VERSION "created by canmatrix"

NS_ :

BS_:

BU_: Pack01BMSLeader Pack02BMS Pack03BMS Pack04BMS Pack05BMS Pack06BMS Pack07BMS Pack08BMS Pack09BMS Pack10BMS Pack11BMS Pack12BMS Pack13BMS Pack14BMS Pack15BMS Pack16BMS

BO_ 2364525001 Control_1_Pack01BMSLeader: 8 Pack01BMSLeader
 SG_ Connect_Command : 0|3@1+ (1,0) [0|7] "" Pack01BMSLeader
 SG_ Disable_Command : 3|2@1+ (1,0) [0|3] "" Pack01BMSLeader

BO_ 2364525257 Control_1_Pack02BMS: 8 Pack01BMSLeader
 SG_ Connect_Command : 0|3@1+ (1,0) [0|7] "" Pack02BMS
 SG_ Disable_Command : 3|2@1+ (1,0) [0|3] "" Pack02BMS

BO_ 2364525513 Control_1_Pack03BMS: 8 Pack01BMSLeader
 SG_ Connect_Command : 0|3@1+ (1,0) [0|7] "" Pack03BMS
 SG_ Disable_Command : 3|2@1+ (1,0) [0|3] "" Pack03BMS

BO_ 2364525769 Control_1_Pack04BMS: 8 Pack01BMSLeader
 SG_ Connect_Command : 0|3@1+ (1,0) [0|7] "" Pack04BMS
 SG_ Disable_Command : 3|2@1+ (1,0) [0|3] "" Pack04BMS

BO_ 2364526025 Control_1_Pack05BMS: 8 Pack01BMSLeader
 SG_ Connect_Command : 0|3@1+ (1,0) [0|7] "" Pack05BMS
 SG_ Disable_Command : 3|2@1+ (1,0) [0|3] "" Pack05BMS

BO_ 2364526281 Control_1_Pack06BMS: 8 Pack01BMSLeader
 SG_ Connect_Command : 0|3@1+ (1,0) [0|7] "" Pack06BMS
 SG_ Disable_Command : 3|2@1+ (1,0) [0|3] "" Pack06BMS

BO_ 2364526537 Control_1_Pack07BMS: 8 Pack01BMSLeader
 SG_ Connect_Command : 0|3@1+ (1,0) [0|7] "" Pack07BMS
 SG_ Disable_Command : 3|2@1+ (1,0) [0|3] "" Pack07BMS

BO_ 2364526793 Control_1_Pack08BMS: 8 Pack01BMSLeader
 SG_ Connect_Command : 0|3@1+ (1,0) [0|7] "" Pack08BMS
 SG_ Disable_Command : 3|2@1+ (1,0) [0|3] "" Pack08BMS

BO_ 2364527049 Control_1_Pack09BMS: 8 Pack01BMSLeader
 SG_ Connect_Command : 0|3@1+ (1,0) [0|7] "" Pack09BMS
 SG_ Disable_Command : 3|2@1+ (1,0) [0|3] "" Pack09BMS

BO_ 2364527305 Control_1_Pack10BMS: 8 Pack01BMSLeader
 SG_ Connect_Command : 0|3@1+ (1,0) [0|7] "" Pack10BMS
 SG_ Disable_Command : 3|2@1+ (1,0) [0|3] "" Pack10BMS

BO_ 2364527561 Control_1_Pack11BMS: 8 Pack01BMSLeader
 SG_ Connect_Command : 0|3@1+ (1,0) [0|7] "" Pack11BMS
 SG_ Disable_Command : 3|2@1+ (1,0) [0|3] "" Pack11BMS

BO_ 2364527817 Control_1_Pack12BMS: 8 Pack01BMSLeader
 SG_ Connect_Command : 0|3@1+ (1,0) [0|7] "" Pack12BMS
 SG_ Disable_Command : 3|2@1+ (1,0) [0|3] "" Pack12BMS

BO_ 2364528073 Control_1_Pack13BMS: 8 Pack01BMSLeader
 SG_ Connect_Command : 0|3@1+ (1,0) [0|7] "" Pack13BMS
 SG_ Disable_Command : 3|2@1+ (1,0) [0|3] "" Pack13BMS

BO_ 2364528329 Control_1_Pack14BMS: 8 Pack01BMSLeader
 SG_ Connect_Command : 0|3@1+ (1,0) [0|7] "" Pack14BMS
 SG_ Disable_Command : 3|2@1+ (1,0) [0|3] "" Pack14BMS

BO_ 2364528585 Control_1_Pack15BMS: 8 Pack01BMSLeader
 SG_ Connect_Command : 0|3@1+ (1,0) [0|7] "" Pack15BMS
 SG_ Disable_Command : 3|2@1+ (1,0) [0|3] "" Pack15BMS

BO_ 2364528841 Control_1_Pack16BMS: 8 Pack01BMSLeader
 SG_ Connect_Command : 0|3@1+ (1,0) [0|7] "" Pack16BMS
 SG_ Disable_Command : 3|2@1+ (1,0) [0|3] "" Pack16BMS

BO_ 2365587401 Control_2_Broadcast: 8 Pack01BMSLeader
 SG_ System_Current : 0|16@1+ (0.05,-1600) [-1600|1676.75] "A" Vector__XXX
 SG_ System_Average_Current_Connected : 16|16@1+ (0.05,-1600) [-1600|1676.75] "A" Vector__XXX
 SG_ System_HVDC_Bus_Voltage : 32|16@1+ (0.05,0) [0|3276.75] "V" Vector__XXX
 SG_ System_Charging_Mode : 48|2@1+ (1,0) [0|3] "" Vector__XXX

BO_ 2365587145 Control_3_Broadcast: 8 Pack01BMSLeader
 SG_ System_Unix_Time : 0|32@1+ (1,0) [0|4294967295] "s" Vector__XXX
 SG_ System_Clear_DMs_Command : 32|2@1+ (1,0) [0|3] "" Vector__XXX

BO_ 2566834889 DM1_INTERPACK_Pack01BMSLeader: 550 Pack01BMSLeader

BO_ 2566834890 DM1_INTERPACK_Pack02BMS: 550 Pack02BMS

BO_ 2566834891 DM1_INTERPACK_Pack03BMS: 550 Pack03BMS

BO_ 2566834892 DM1_INTERPACK_Pack04BMS: 550 Pack04BMS

BO_ 2566834893 DM1_INTERPACK_Pack05BMS: 550 Pack05BMS

BO_ 2566834894 DM1_INTERPACK_Pack06BMS: 550 Pack06BMS

BO_ 2566834895 DM1_INTERPACK_Pack07BMS: 550 Pack07BMS

BO_ 2566834896 DM1_INTERPACK_Pack08BMS: 550 Pack08BMS

BO_ 2566834897 DM1_INTERPACK_Pack09BMS: 550 Pack09BMS

BO_ 2566834898 DM1_INTERPACK_Pack10BMS: 550 Pack10BMS

BO_ 2566834899 DM1_INTERPACK_Pack11BMS: 550 Pack11BMS

BO_ 2566834900 DM1_INTERPACK_Pack12BMS: 550 Pack12BMS

BO_ 2566834901 DM1_INTERPACK_Pack13BMS: 550 Pack13BMS

BO_ 2566834902 DM1_INTERPACK_Pack14BMS: 550 Pack14BMS

BO_ 2566834903 DM1_INTERPACK_Pack15BMS: 550 Pack15BMS

BO_ 2566834904 DM1_INTERPACK_Pack16BMS: 550 Pack16BMS

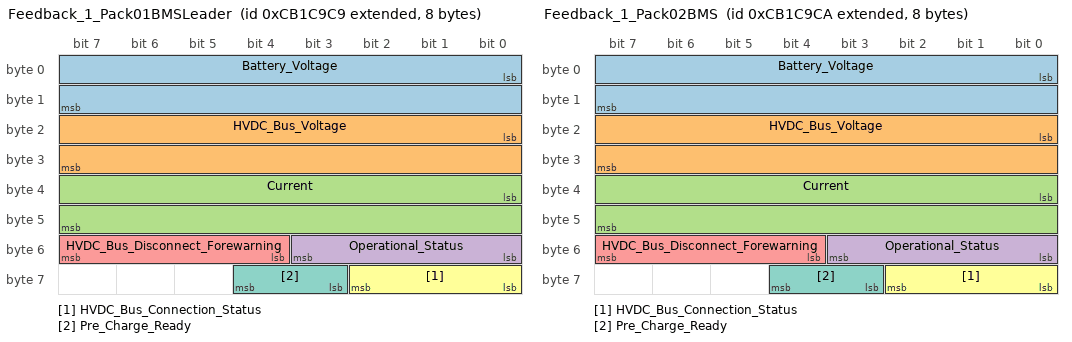
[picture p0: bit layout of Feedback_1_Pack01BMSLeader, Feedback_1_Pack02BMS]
BO_ 2360461769 Feedback_1_Pack01BMSLeader: 8 Pack01BMSLeader
 SG_ Battery_Voltage : 0|16@1+ (0.05,0) [0|3276.75] "V" Pack01BMSLeader
 SG_ HVDC_Bus_Voltage : 16|16@1+ (0.05,0) [0|3276.75] "V" Pack01BMSLeader
 SG_ Current : 32|16@1+ (0.05,-1600) [-1600|1676.75] "A" Pack01BMSLeader
 SG_ Operational_Status : 48|4@1+ (1,0) [0|15] "" Pack01BMSLeader
 SG_ HVDC_Bus_Disconnect_Forewarning : 52|4@1+ (1,0) [0|15] "" Pack01BMSLeader
 SG_ HVDC_Bus_Connection_Status : 56|3@1+ (1,0) [0|7] "" Pack01BMSLeader
 SG_ Pre_Charge_Ready : 59|2@1+ (1,0) [0|3] "" Pack01BMSLeader

BO_ 2360461770 Feedback_1_Pack02BMS: 8 Pack02BMS
 SG_ Battery_Voltage : 0|16@1+ (0.05,0) [0|3276.75] "V" Pack01BMSLeader
 SG_ HVDC_Bus_Voltage : 16|16@1+ (0.05,0) [0|3276.75] "V" Pack01BMSLeader
 SG_ Current : 32|16@1+ (0.05,-1600) [-1600|1676.75] "A" Pack01BMSLeader
 SG_ Operational_Status : 48|4@1+ (1,0) [0|15] "" Pack01BMSLeader
 SG_ HVDC_Bus_Disconnect_Forewarning : 52|4@1+ (1,0) [0|15] "" Pack01BMSLeader
 SG_ HVDC_Bus_Connection_Status : 56|3@1+ (1,0) [0|7] "" Pack01BMSLeader
 SG_ Pre_Charge_Ready : 59|2@1+ (1,0) [0|3] "" Pack01BMSLeader

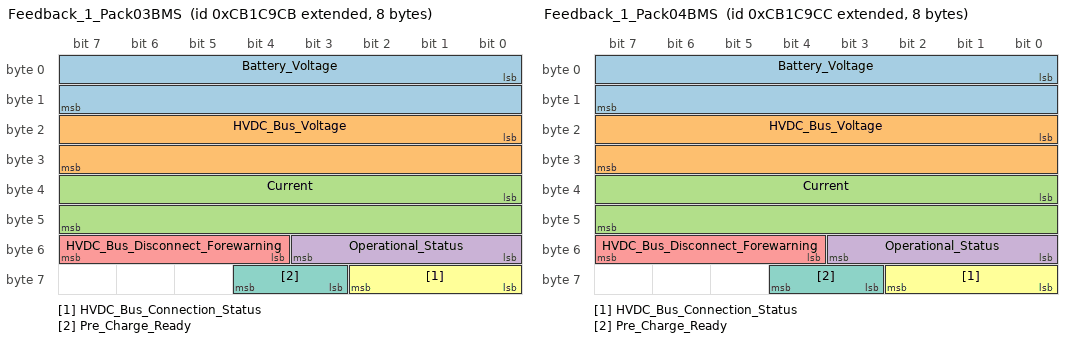
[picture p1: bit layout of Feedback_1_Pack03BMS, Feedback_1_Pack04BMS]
BO_ 2360461771 Feedback_1_Pack03BMS: 8 Pack03BMS
 SG_ Battery_Voltage : 0|16@1+ (0.05,0) [0|3276.75] "V" Pack01BMSLeader
 SG_ HVDC_Bus_Voltage : 16|16@1+ (0.05,0) [0|3276.75] "V" Pack01BMSLeader
 SG_ Current : 32|16@1+ (0.05,-1600) [-1600|1676.75] "A" Pack01BMSLeader
 SG_ Operational_Status : 48|4@1+ (1,0) [0|15] "" Pack01BMSLeader
 SG_ HVDC_Bus_Disconnect_Forewarning : 52|4@1+ (1,0) [0|15] "" Pack01BMSLeader
 SG_ HVDC_Bus_Connection_Status : 56|3@1+ (1,0) [0|7] "" Pack01BMSLeader
 SG_ Pre_Charge_Ready : 59|2@1+ (1,0) [0|3] "" Pack01BMSLeader

BO_ 2360461772 Feedback_1_Pack04BMS: 8 Pack04BMS
 SG_ Battery_Voltage : 0|16@1+ (0.05,0) [0|3276.75] "V" Pack01BMSLeader
 SG_ HVDC_Bus_Voltage : 16|16@1+ (0.05,0) [0|3276.75] "V" Pack01BMSLeader
 SG_ Current : 32|16@1+ (0.05,-1600) [-1600|1676.75] "A" Pack01BMSLeader
 SG_ Operational_Status : 48|4@1+ (1,0) [0|15] "" Pack01BMSLeader
 SG_ HVDC_Bus_Disconnect_Forewarning : 52|4@1+ (1,0) [0|15] "" Pack01BMSLeader
 SG_ HVDC_Bus_Connection_Status : 56|3@1+ (1,0) [0|7] "" Pack01BMSLeader
 SG_ Pre_Charge_Ready : 59|2@1+ (1,0) [0|3] "" Pack01BMSLeader

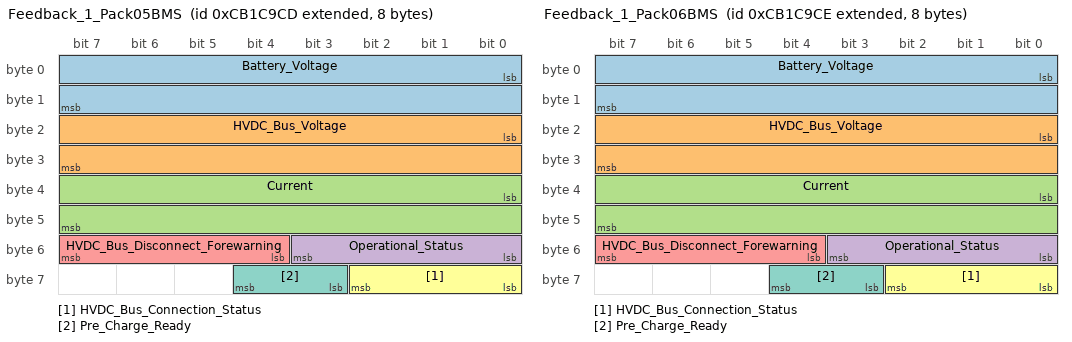
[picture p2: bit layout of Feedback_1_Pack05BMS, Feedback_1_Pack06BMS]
BO_ 2360461773 Feedback_1_Pack05BMS: 8 Pack05BMS
 SG_ Battery_Voltage : 0|16@1+ (0.05,0) [0|3276.75] "V" Pack01BMSLeader
 SG_ HVDC_Bus_Voltage : 16|16@1+ (0.05,0) [0|3276.75] "V" Pack01BMSLeader
 SG_ Current : 32|16@1+ (0.05,-1600) [-1600|1676.75] "A" Pack01BMSLeader
 SG_ Operational_Status : 48|4@1+ (1,0) [0|15] "" Pack01BMSLeader
 SG_ HVDC_Bus_Disconnect_Forewarning : 52|4@1+ (1,0) [0|15] "" Pack01BMSLeader
 SG_ HVDC_Bus_Connection_Status : 56|3@1+ (1,0) [0|7] "" Pack01BMSLeader
 SG_ Pre_Charge_Ready : 59|2@1+ (1,0) [0|3] "" Pack01BMSLeader

BO_ 2360461774 Feedback_1_Pack06BMS: 8 Pack06BMS
 SG_ Battery_Voltage : 0|16@1+ (0.05,0) [0|3276.75] "V" Pack01BMSLeader
 SG_ HVDC_Bus_Voltage : 16|16@1+ (0.05,0) [0|3276.75] "V" Pack01BMSLeader
 SG_ Current : 32|16@1+ (0.05,-1600) [-1600|1676.75] "A" Pack01BMSLeader
 SG_ Operational_Status : 48|4@1+ (1,0) [0|15] "" Pack01BMSLeader
 SG_ HVDC_Bus_Disconnect_Forewarning : 52|4@1+ (1,0) [0|15] "" Pack01BMSLeader
 SG_ HVDC_Bus_Connection_Status : 56|3@1+ (1,0) [0|7] "" Pack01BMSLeader
 SG_ Pre_Charge_Ready : 59|2@1+ (1,0) [0|3] "" Pack01BMSLeader

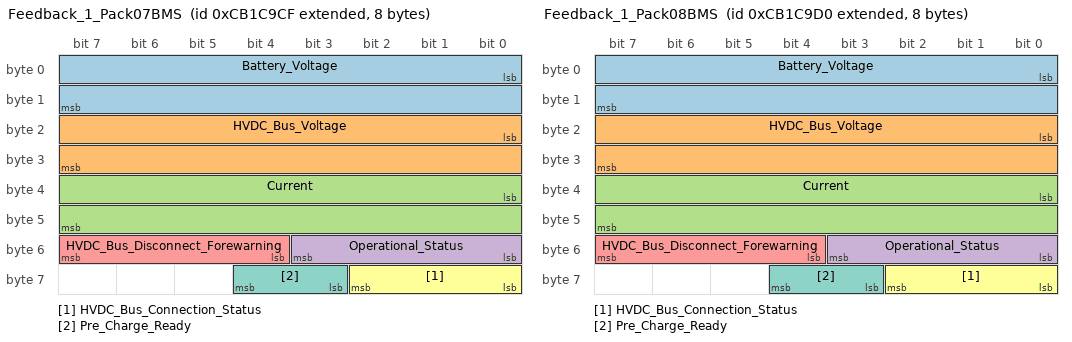
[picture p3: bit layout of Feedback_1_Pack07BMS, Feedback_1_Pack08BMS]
BO_ 2360461775 Feedback_1_Pack07BMS: 8 Pack07BMS
 SG_ Battery_Voltage : 0|16@1+ (0.05,0) [0|3276.75] "V" Pack01BMSLeader
 SG_ HVDC_Bus_Voltage : 16|16@1+ (0.05,0) [0|3276.75] "V" Pack01BMSLeader
 SG_ Current : 32|16@1+ (0.05,-1600) [-1600|1676.75] "A" Pack01BMSLeader
 SG_ Operational_Status : 48|4@1+ (1,0) [0|15] "" Pack01BMSLeader
 SG_ HVDC_Bus_Disconnect_Forewarning : 52|4@1+ (1,0) [0|15] "" Pack01BMSLeader
 SG_ HVDC_Bus_Connection_Status : 56|3@1+ (1,0) [0|7] "" Pack01BMSLeader
 SG_ Pre_Charge_Ready : 59|2@1+ (1,0) [0|3] "" Pack01BMSLeader

BO_ 2360461776 Feedback_1_Pack08BMS: 8 Pack08BMS
 SG_ Battery_Voltage : 0|16@1+ (0.05,0) [0|3276.75] "V" Pack01BMSLeader
 SG_ HVDC_Bus_Voltage : 16|16@1+ (0.05,0) [0|3276.75] "V" Pack01BMSLeader
 SG_ Current : 32|16@1+ (0.05,-1600) [-1600|1676.75] "A" Pack01BMSLeader
 SG_ Operational_Status : 48|4@1+ (1,0) [0|15] "" Pack01BMSLeader
 SG_ HVDC_Bus_Disconnect_Forewarning : 52|4@1+ (1,0) [0|15] "" Pack01BMSLeader
 SG_ HVDC_Bus_Connection_Status : 56|3@1+ (1,0) [0|7] "" Pack01BMSLeader
 SG_ Pre_Charge_Ready : 59|2@1+ (1,0) [0|3] "" Pack01BMSLeader

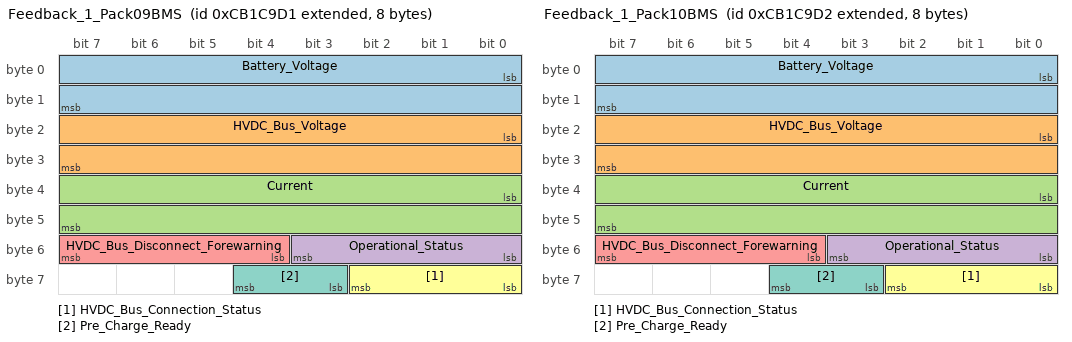
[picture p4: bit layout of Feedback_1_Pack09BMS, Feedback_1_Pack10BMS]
BO_ 2360461777 Feedback_1_Pack09BMS: 8 Pack09BMS
 SG_ Battery_Voltage : 0|16@1+ (0.05,0) [0|3276.75] "V" Pack01BMSLeader
 SG_ HVDC_Bus_Voltage : 16|16@1+ (0.05,0) [0|3276.75] "V" Pack01BMSLeader
 SG_ Current : 32|16@1+ (0.05,-1600) [-1600|1676.75] "A" Pack01BMSLeader
 SG_ Operational_Status : 48|4@1+ (1,0) [0|15] "" Pack01BMSLeader
 SG_ HVDC_Bus_Disconnect_Forewarning : 52|4@1+ (1,0) [0|15] "" Pack01BMSLeader
 SG_ HVDC_Bus_Connection_Status : 56|3@1+ (1,0) [0|7] "" Pack01BMSLeader
 SG_ Pre_Charge_Ready : 59|2@1+ (1,0) [0|3] "" Pack01BMSLeader

BO_ 2360461778 Feedback_1_Pack10BMS: 8 Pack10BMS
 SG_ Battery_Voltage : 0|16@1+ (0.05,0) [0|3276.75] "V" Pack01BMSLeader
 SG_ HVDC_Bus_Voltage : 16|16@1+ (0.05,0) [0|3276.75] "V" Pack01BMSLeader
 SG_ Current : 32|16@1+ (0.05,-1600) [-1600|1676.75] "A" Pack01BMSLeader
 SG_ Operational_Status : 48|4@1+ (1,0) [0|15] "" Pack01BMSLeader
 SG_ HVDC_Bus_Disconnect_Forewarning : 52|4@1+ (1,0) [0|15] "" Pack01BMSLeader
 SG_ HVDC_Bus_Connection_Status : 56|3@1+ (1,0) [0|7] "" Pack01BMSLeader
 SG_ Pre_Charge_Ready : 59|2@1+ (1,0) [0|3] "" Pack01BMSLeader

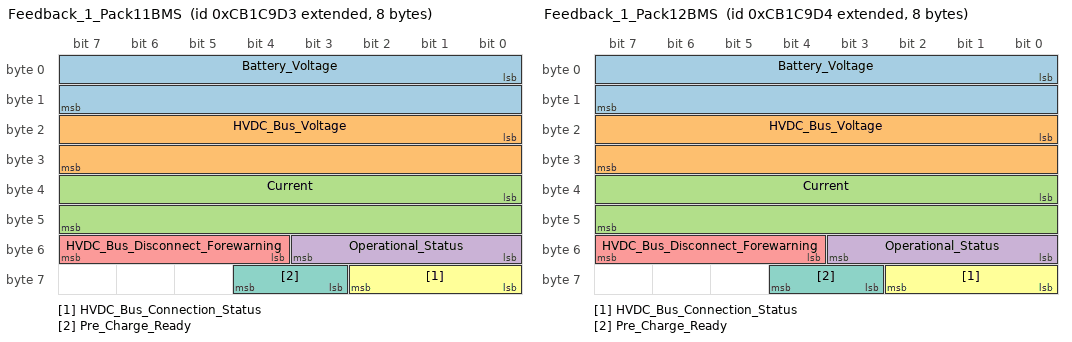
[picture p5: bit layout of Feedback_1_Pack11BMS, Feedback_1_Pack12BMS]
BO_ 2360461779 Feedback_1_Pack11BMS: 8 Pack11BMS
 SG_ Battery_Voltage : 0|16@1+ (0.05,0) [0|3276.75] "V" Pack01BMSLeader
 SG_ HVDC_Bus_Voltage : 16|16@1+ (0.05,0) [0|3276.75] "V" Pack01BMSLeader
 SG_ Current : 32|16@1+ (0.05,-1600) [-1600|1676.75] "A" Pack01BMSLeader
 SG_ Operational_Status : 48|4@1+ (1,0) [0|15] "" Pack01BMSLeader
 SG_ HVDC_Bus_Disconnect_Forewarning : 52|4@1+ (1,0) [0|15] "" Pack01BMSLeader
 SG_ HVDC_Bus_Connection_Status : 56|3@1+ (1,0) [0|7] "" Pack01BMSLeader
 SG_ Pre_Charge_Ready : 59|2@1+ (1,0) [0|3] "" Pack01BMSLeader

BO_ 2360461780 Feedback_1_Pack12BMS: 8 Pack12BMS
 SG_ Battery_Voltage : 0|16@1+ (0.05,0) [0|3276.75] "V" Pack01BMSLeader
 SG_ HVDC_Bus_Voltage : 16|16@1+ (0.05,0) [0|3276.75] "V" Pack01BMSLeader
 SG_ Current : 32|16@1+ (0.05,-1600) [-1600|1676.75] "A" Pack01BMSLeader
 SG_ Operational_Status : 48|4@1+ (1,0) [0|15] "" Pack01BMSLeader
 SG_ HVDC_Bus_Disconnect_Forewarning : 52|4@1+ (1,0) [0|15] "" Pack01BMSLeader
 SG_ HVDC_Bus_Connection_Status : 56|3@1+ (1,0) [0|7] "" Pack01BMSLeader
 SG_ Pre_Charge_Ready : 59|2@1+ (1,0) [0|3] "" Pack01BMSLeader

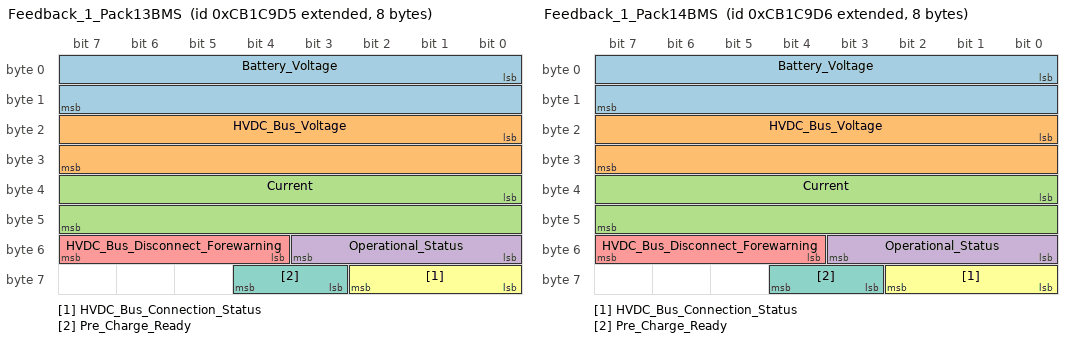
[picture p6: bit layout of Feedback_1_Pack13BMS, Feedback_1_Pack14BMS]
BO_ 2360461781 Feedback_1_Pack13BMS: 8 Pack13BMS
 SG_ Battery_Voltage : 0|16@1+ (0.05,0) [0|3276.75] "V" Pack01BMSLeader
 SG_ HVDC_Bus_Voltage : 16|16@1+ (0.05,0) [0|3276.75] "V" Pack01BMSLeader
 SG_ Current : 32|16@1+ (0.05,-1600) [-1600|1676.75] "A" Pack01BMSLeader
 SG_ Operational_Status : 48|4@1+ (1,0) [0|15] "" Pack01BMSLeader
 SG_ HVDC_Bus_Disconnect_Forewarning : 52|4@1+ (1,0) [0|15] "" Pack01BMSLeader
 SG_ HVDC_Bus_Connection_Status : 56|3@1+ (1,0) [0|7] "" Pack01BMSLeader
 SG_ Pre_Charge_Ready : 59|2@1+ (1,0) [0|3] "" Pack01BMSLeader

BO_ 2360461782 Feedback_1_Pack14BMS: 8 Pack14BMS
 SG_ Battery_Voltage : 0|16@1+ (0.05,0) [0|3276.75] "V" Pack01BMSLeader
 SG_ HVDC_Bus_Voltage : 16|16@1+ (0.05,0) [0|3276.75] "V" Pack01BMSLeader
 SG_ Current : 32|16@1+ (0.05,-1600) [-1600|1676.75] "A" Pack01BMSLeader
 SG_ Operational_Status : 48|4@1+ (1,0) [0|15] "" Pack01BMSLeader
 SG_ HVDC_Bus_Disconnect_Forewarning : 52|4@1+ (1,0) [0|15] "" Pack01BMSLeader
 SG_ HVDC_Bus_Connection_Status : 56|3@1+ (1,0) [0|7] "" Pack01BMSLeader
 SG_ Pre_Charge_Ready : 59|2@1+ (1,0) [0|3] "" Pack01BMSLeader

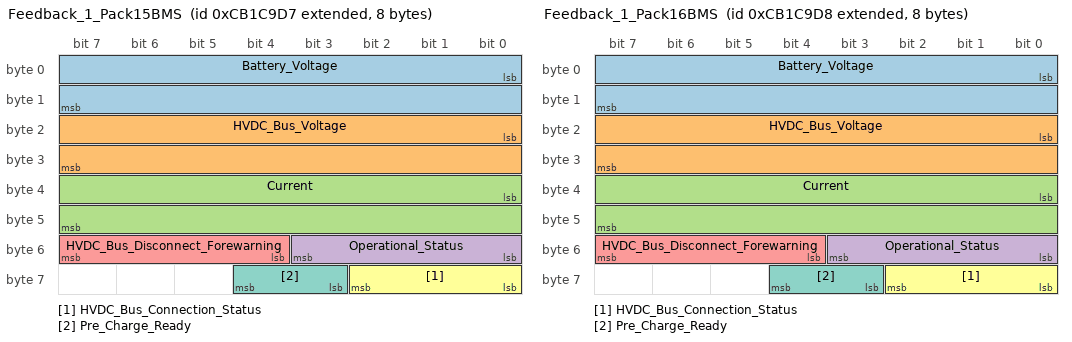
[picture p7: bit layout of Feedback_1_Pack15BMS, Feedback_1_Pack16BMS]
BO_ 2360461783 Feedback_1_Pack15BMS: 8 Pack15BMS
 SG_ Battery_Voltage : 0|16@1+ (0.05,0) [0|3276.75] "V" Pack01BMSLeader
 SG_ HVDC_Bus_Voltage : 16|16@1+ (0.05,0) [0|3276.75] "V" Pack01BMSLeader
 SG_ Current : 32|16@1+ (0.05,-1600) [-1600|1676.75] "A" Pack01BMSLeader
 SG_ Operational_Status : 48|4@1+ (1,0) [0|15] "" Pack01BMSLeader
 SG_ HVDC_Bus_Disconnect_Forewarning : 52|4@1+ (1,0) [0|15] "" Pack01BMSLeader
 SG_ HVDC_Bus_Connection_Status : 56|3@1+ (1,0) [0|7] "" Pack01BMSLeader
 SG_ Pre_Charge_Ready : 59|2@1+ (1,0) [0|3] "" Pack01BMSLeader

BO_ 2360461784 Feedback_1_Pack16BMS: 8 Pack16BMS
 SG_ Battery_Voltage : 0|16@1+ (0.05,0) [0|3276.75] "V" Pack01BMSLeader
 SG_ HVDC_Bus_Voltage : 16|16@1+ (0.05,0) [0|3276.75] "V" Pack01BMSLeader
 SG_ Current : 32|16@1+ (0.05,-1600) [-1600|1676.75] "A" Pack01BMSLeader
 SG_ Operational_Status : 48|4@1+ (1,0) [0|15] "" Pack01BMSLeader
 SG_ HVDC_Bus_Disconnect_Forewarning : 52|4@1+ (1,0) [0|15] "" Pack01BMSLeader
 SG_ HVDC_Bus_Connection_Status : 56|3@1+ (1,0) [0|7] "" Pack01BMSLeader
 SG_ Pre_Charge_Ready : 59|2@1+ (1,0) [0|3] "" Pack01BMSLeader

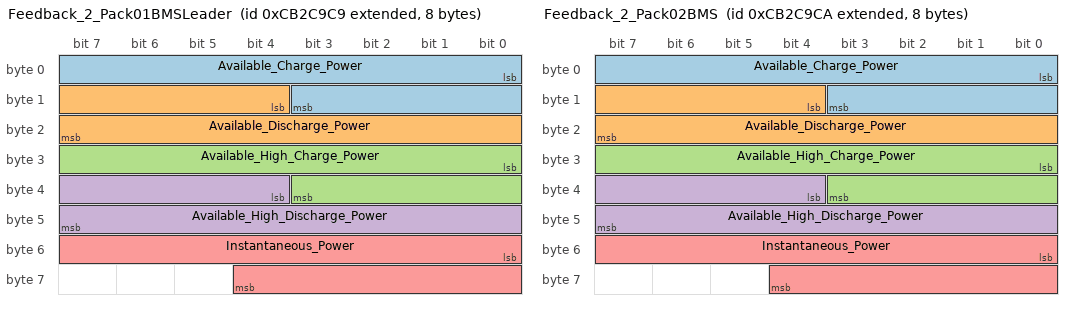
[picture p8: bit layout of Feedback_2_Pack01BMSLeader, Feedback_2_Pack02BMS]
BO_ 2360527305 Feedback_2_Pack01BMSLeader: 8 Pack01BMSLeader
 SG_ Available_Charge_Power : 0|12@1+ (0.05,0) [0|204.75] "kW" Pack01BMSLeader
 SG_ Available_Discharge_Power : 12|12@1+ (0.05,0) [0|204.75] "kW" Pack01BMSLeader
 SG_ Available_High_Charge_Power : 24|12@1+ (0.05,0) [0|204.75] "kW" Pack01BMSLeader
 SG_ Available_High_Discharge_Power : 36|12@1+ (0.05,0) [0|204.75] "kW" Pack01BMSLeader
 SG_ Instantaneous_Power : 48|13@1+ (0.05,-204) [-204|205.55] "kW" Pack01BMSLeader

BO_ 2360527306 Feedback_2_Pack02BMS: 8 Pack02BMS
 SG_ Available_Charge_Power : 0|12@1+ (0.05,0) [0|204.75] "kW" Pack01BMSLeader
 SG_ Available_Discharge_Power : 12|12@1+ (0.05,0) [0|204.75] "kW" Pack01BMSLeader
 SG_ Available_High_Charge_Power : 24|12@1+ (0.05,0) [0|204.75] "kW" Pack01BMSLeader
 SG_ Available_High_Discharge_Power : 36|12@1+ (0.05,0) [0|204.75] "kW" Pack01BMSLeader
 SG_ Instantaneous_Power : 48|13@1+ (0.05,-204) [-204|205.55] "kW" Pack01BMSLeader

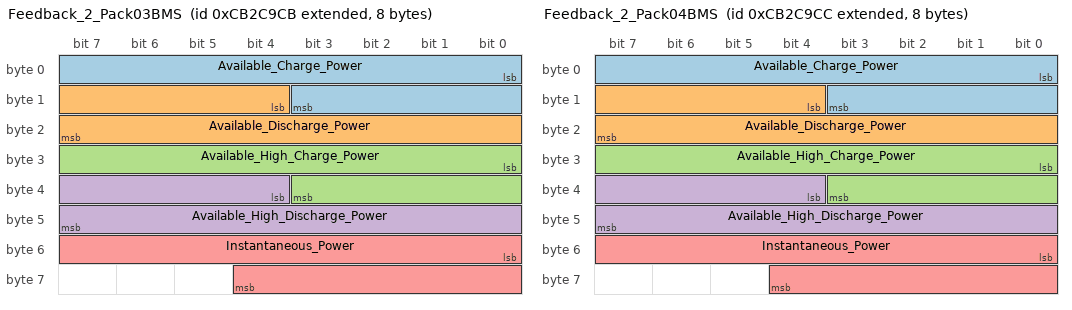
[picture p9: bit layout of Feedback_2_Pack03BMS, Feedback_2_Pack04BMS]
BO_ 2360527307 Feedback_2_Pack03BMS: 8 Pack03BMS
 SG_ Available_Charge_Power : 0|12@1+ (0.05,0) [0|204.75] "kW" Pack01BMSLeader
 SG_ Available_Discharge_Power : 12|12@1+ (0.05,0) [0|204.75] "kW" Pack01BMSLeader
 SG_ Available_High_Charge_Power : 24|12@1+ (0.05,0) [0|204.75] "kW" Pack01BMSLeader
 SG_ Available_High_Discharge_Power : 36|12@1+ (0.05,0) [0|204.75] "kW" Pack01BMSLeader
 SG_ Instantaneous_Power : 48|13@1+ (0.05,-204) [-204|205.55] "kW" Pack01BMSLeader

BO_ 2360527308 Feedback_2_Pack04BMS: 8 Pack04BMS
 SG_ Available_Charge_Power : 0|12@1+ (0.05,0) [0|204.75] "kW" Pack01BMSLeader
 SG_ Available_Discharge_Power : 12|12@1+ (0.05,0) [0|204.75] "kW" Pack01BMSLeader
 SG_ Available_High_Charge_Power : 24|12@1+ (0.05,0) [0|204.75] "kW" Pack01BMSLeader
 SG_ Available_High_Discharge_Power : 36|12@1+ (0.05,0) [0|204.75] "kW" Pack01BMSLeader
 SG_ Instantaneous_Power : 48|13@1+ (0.05,-204) [-204|205.55] "kW" Pack01BMSLeader

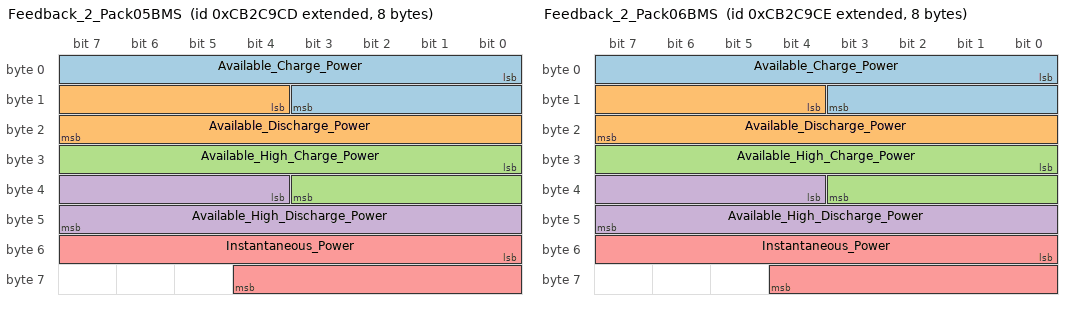
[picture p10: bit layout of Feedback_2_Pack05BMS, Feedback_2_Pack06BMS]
BO_ 2360527309 Feedback_2_Pack05BMS: 8 Pack05BMS
 SG_ Available_Charge_Power : 0|12@1+ (0.05,0) [0|204.75] "kW" Pack01BMSLeader
 SG_ Available_Discharge_Power : 12|12@1+ (0.05,0) [0|204.75] "kW" Pack01BMSLeader
 SG_ Available_High_Charge_Power : 24|12@1+ (0.05,0) [0|204.75] "kW" Pack01BMSLeader
 SG_ Available_High_Discharge_Power : 36|12@1+ (0.05,0) [0|204.75] "kW" Pack01BMSLeader
 SG_ Instantaneous_Power : 48|13@1+ (0.05,-204) [-204|205.55] "kW" Pack01BMSLeader

BO_ 2360527310 Feedback_2_Pack06BMS: 8 Pack06BMS
 SG_ Available_Charge_Power : 0|12@1+ (0.05,0) [0|204.75] "kW" Pack01BMSLeader
 SG_ Available_Discharge_Power : 12|12@1+ (0.05,0) [0|204.75] "kW" Pack01BMSLeader
 SG_ Available_High_Charge_Power : 24|12@1+ (0.05,0) [0|204.75] "kW" Pack01BMSLeader
 SG_ Available_High_Discharge_Power : 36|12@1+ (0.05,0) [0|204.75] "kW" Pack01BMSLeader
 SG_ Instantaneous_Power : 48|13@1+ (0.05,-204) [-204|205.55] "kW" Pack01BMSLeader

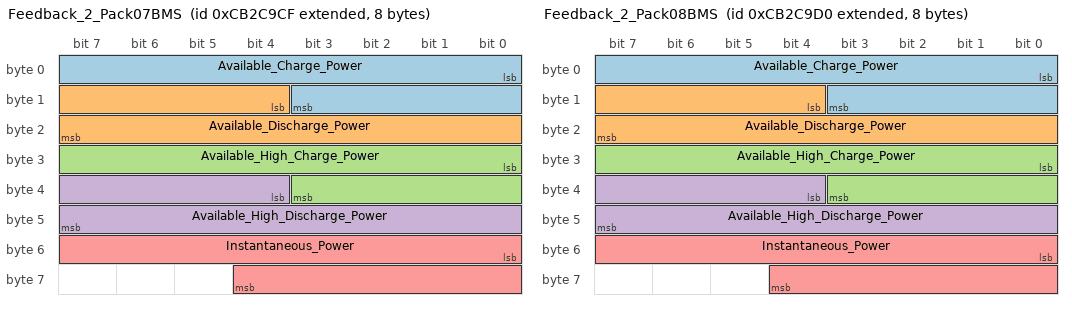
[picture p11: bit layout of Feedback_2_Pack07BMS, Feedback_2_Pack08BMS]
BO_ 2360527311 Feedback_2_Pack07BMS: 8 Pack07BMS
 SG_ Available_Charge_Power : 0|12@1+ (0.05,0) [0|204.75] "kW" Pack01BMSLeader
 SG_ Available_Discharge_Power : 12|12@1+ (0.05,0) [0|204.75] "kW" Pack01BMSLeader
 SG_ Available_High_Charge_Power : 24|12@1+ (0.05,0) [0|204.75] "kW" Pack01BMSLeader
 SG_ Available_High_Discharge_Power : 36|12@1+ (0.05,0) [0|204.75] "kW" Pack01BMSLeader
 SG_ Instantaneous_Power : 48|13@1+ (0.05,-204) [-204|205.55] "kW" Pack01BMSLeader

BO_ 2360527312 Feedback_2_Pack08BMS: 8 Pack08BMS
 SG_ Available_Charge_Power : 0|12@1+ (0.05,0) [0|204.75] "kW" Pack01BMSLeader
 SG_ Available_Discharge_Power : 12|12@1+ (0.05,0) [0|204.75] "kW" Pack01BMSLeader
 SG_ Available_High_Charge_Power : 24|12@1+ (0.05,0) [0|204.75] "kW" Pack01BMSLeader
 SG_ Available_High_Discharge_Power : 36|12@1+ (0.05,0) [0|204.75] "kW" Pack01BMSLeader
 SG_ Instantaneous_Power : 48|13@1+ (0.05,-204) [-204|205.55] "kW" Pack01BMSLeader

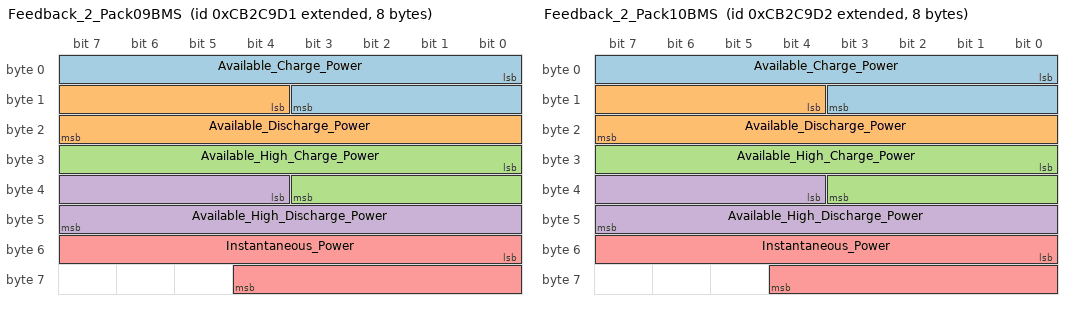
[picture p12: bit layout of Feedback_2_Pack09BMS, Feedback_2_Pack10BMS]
BO_ 2360527313 Feedback_2_Pack09BMS: 8 Pack09BMS
 SG_ Available_Charge_Power : 0|12@1+ (0.05,0) [0|204.75] "kW" Pack01BMSLeader
 SG_ Available_Discharge_Power : 12|12@1+ (0.05,0) [0|204.75] "kW" Pack01BMSLeader
 SG_ Available_High_Charge_Power : 24|12@1+ (0.05,0) [0|204.75] "kW" Pack01BMSLeader
 SG_ Available_High_Discharge_Power : 36|12@1+ (0.05,0) [0|204.75] "kW" Pack01BMSLeader
 SG_ Instantaneous_Power : 48|13@1+ (0.05,-204) [-204|205.55] "kW" Pack01BMSLeader

BO_ 2360527314 Feedback_2_Pack10BMS: 8 Pack10BMS
 SG_ Available_Charge_Power : 0|12@1+ (0.05,0) [0|204.75] "kW" Pack01BMSLeader
 SG_ Available_Discharge_Power : 12|12@1+ (0.05,0) [0|204.75] "kW" Pack01BMSLeader
 SG_ Available_High_Charge_Power : 24|12@1+ (0.05,0) [0|204.75] "kW" Pack01BMSLeader
 SG_ Available_High_Discharge_Power : 36|12@1+ (0.05,0) [0|204.75] "kW" Pack01BMSLeader
 SG_ Instantaneous_Power : 48|13@1+ (0.05,-204) [-204|205.55] "kW" Pack01BMSLeader

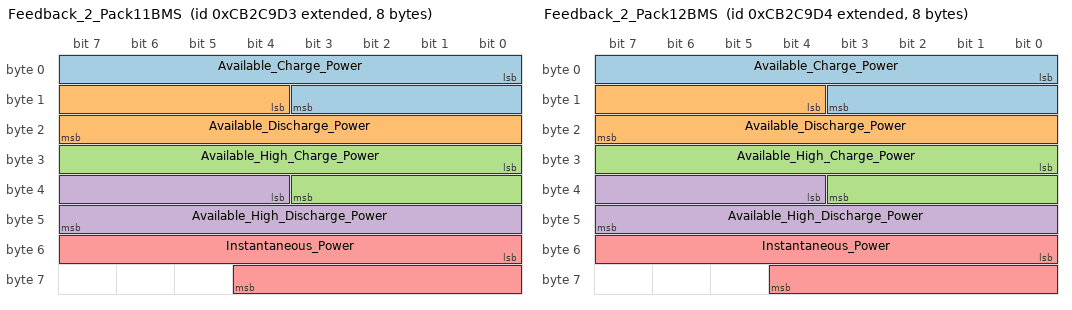
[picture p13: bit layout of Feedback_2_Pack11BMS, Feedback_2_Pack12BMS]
BO_ 2360527315 Feedback_2_Pack11BMS: 8 Pack11BMS
 SG_ Available_Charge_Power : 0|12@1+ (0.05,0) [0|204.75] "kW" Pack01BMSLeader
 SG_ Available_Discharge_Power : 12|12@1+ (0.05,0) [0|204.75] "kW" Pack01BMSLeader
 SG_ Available_High_Charge_Power : 24|12@1+ (0.05,0) [0|204.75] "kW" Pack01BMSLeader
 SG_ Available_High_Discharge_Power : 36|12@1+ (0.05,0) [0|204.75] "kW" Pack01BMSLeader
 SG_ Instantaneous_Power : 48|13@1+ (0.05,-204) [-204|205.55] "kW" Pack01BMSLeader

BO_ 2360527316 Feedback_2_Pack12BMS: 8 Pack12BMS
 SG_ Available_Charge_Power : 0|12@1+ (0.05,0) [0|204.75] "kW" Pack01BMSLeader
 SG_ Available_Discharge_Power : 12|12@1+ (0.05,0) [0|204.75] "kW" Pack01BMSLeader
 SG_ Available_High_Charge_Power : 24|12@1+ (0.05,0) [0|204.75] "kW" Pack01BMSLeader
 SG_ Available_High_Discharge_Power : 36|12@1+ (0.05,0) [0|204.75] "kW" Pack01BMSLeader
 SG_ Instantaneous_Power : 48|13@1+ (0.05,-204) [-204|205.55] "kW" Pack01BMSLeader

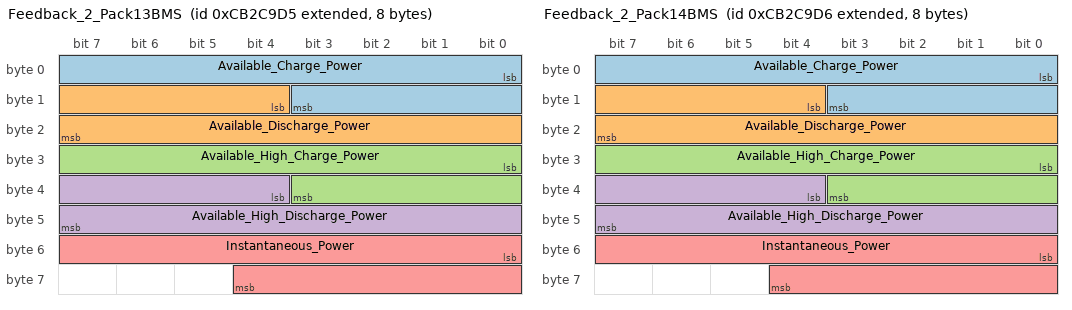
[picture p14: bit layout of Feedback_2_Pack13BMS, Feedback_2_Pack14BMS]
BO_ 2360527317 Feedback_2_Pack13BMS: 8 Pack13BMS
 SG_ Available_Charge_Power : 0|12@1+ (0.05,0) [0|204.75] "kW" Pack01BMSLeader
 SG_ Available_Discharge_Power : 12|12@1+ (0.05,0) [0|204.75] "kW" Pack01BMSLeader
 SG_ Available_High_Charge_Power : 24|12@1+ (0.05,0) [0|204.75] "kW" Pack01BMSLeader
 SG_ Available_High_Discharge_Power : 36|12@1+ (0.05,0) [0|204.75] "kW" Pack01BMSLeader
 SG_ Instantaneous_Power : 48|13@1+ (0.05,-204) [-204|205.55] "kW" Pack01BMSLeader

BO_ 2360527318 Feedback_2_Pack14BMS: 8 Pack14BMS
 SG_ Available_Charge_Power : 0|12@1+ (0.05,0) [0|204.75] "kW" Pack01BMSLeader
 SG_ Available_Discharge_Power : 12|12@1+ (0.05,0) [0|204.75] "kW" Pack01BMSLeader
 SG_ Available_High_Charge_Power : 24|12@1+ (0.05,0) [0|204.75] "kW" Pack01BMSLeader
 SG_ Available_High_Discharge_Power : 36|12@1+ (0.05,0) [0|204.75] "kW" Pack01BMSLeader
 SG_ Instantaneous_Power : 48|13@1+ (0.05,-204) [-204|205.55] "kW" Pack01BMSLeader

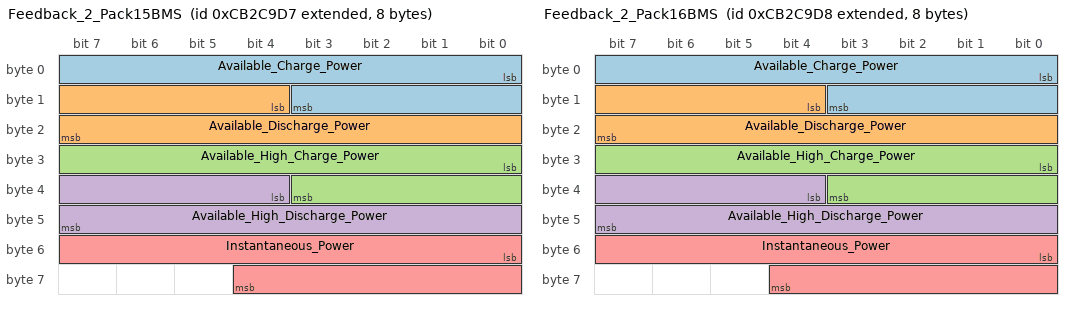
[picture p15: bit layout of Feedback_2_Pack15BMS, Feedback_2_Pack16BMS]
BO_ 2360527319 Feedback_2_Pack15BMS: 8 Pack15BMS
 SG_ Available_Charge_Power : 0|12@1+ (0.05,0) [0|204.75] "kW" Pack01BMSLeader
 SG_ Available_Discharge_Power : 12|12@1+ (0.05,0) [0|204.75] "kW" Pack01BMSLeader
 SG_ Available_High_Charge_Power : 24|12@1+ (0.05,0) [0|204.75] "kW" Pack01BMSLeader
 SG_ Available_High_Discharge_Power : 36|12@1+ (0.05,0) [0|204.75] "kW" Pack01BMSLeader
 SG_ Instantaneous_Power : 48|13@1+ (0.05,-204) [-204|205.55] "kW" Pack01BMSLeader

BO_ 2360527320 Feedback_2_Pack16BMS: 8 Pack16BMS
 SG_ Available_Charge_Power : 0|12@1+ (0.05,0) [0|204.75] "kW" Pack01BMSLeader
 SG_ Available_Discharge_Power : 12|12@1+ (0.05,0) [0|204.75] "kW" Pack01BMSLeader
 SG_ Available_High_Charge_Power : 24|12@1+ (0.05,0) [0|204.75] "kW" Pack01BMSLeader
 SG_ Available_High_Discharge_Power : 36|12@1+ (0.05,0) [0|204.75] "kW" Pack01BMSLeader
 SG_ Instantaneous_Power : 48|13@1+ (0.05,-204) [-204|205.55] "kW" Pack01BMSLeader

BO_ 2360592841 Feedback_3_Pack01BMSLeader: 8 Pack01BMSLeader
 SG_ Lowest_Cell_Voltage : 0|13@1+ (0.001,0) [0|8.191] "V" Pack01BMSLeader
 SG_ Highest_Cell_Voltage : 13|13@1+ (0.001,0) [0|8.191] "V" Pack01BMSLeader
 SG_ Lowest_Cell_Temperature : 26|11@1+ (0.1,-100) [-100|104.7] "degC" Pack01BMSLeader
 SG_ Highest_Cell_Temperature : 37|11@1+ (0.1,-100) [-100|104.7] "degC" Pack01BMSLeader
 SG_ Battery_Isolation : 48|16@1+ (0.1,0) [0|6553.5] "ohm per V" Pack01BMSLeader

BO_ 2360592842 Feedback_3_Pack02BMS: 8 Pack02BMS
 SG_ Lowest_Cell_Voltage : 0|13@1+ (0.001,0) [0|8.191] "V" Pack01BMSLeader
 SG_ Highest_Cell_Voltage : 13|13@1+ (0.001,0) [0|8.191] "V" Pack01BMSLeader
 SG_ Lowest_Cell_Temperature : 26|11@1+ (0.1,-100) [-100|104.7] "degC" Pack01BMSLeader
 SG_ Highest_Cell_Temperature : 37|11@1+ (0.1,-100) [-100|104.7] "degC" Pack01BMSLeader
 SG_ Battery_Isolation : 48|16@1+ (0.1,0) [0|6553.5] "ohm per V" Pack01BMSLeader

BO_ 2360592843 Feedback_3_Pack03BMS: 8 Pack03BMS
 SG_ Lowest_Cell_Voltage : 0|13@1+ (0.001,0) [0|8.191] "V" Pack01BMSLeader
 SG_ Highest_Cell_Voltage : 13|13@1+ (0.001,0) [0|8.191] "V" Pack01BMSLeader
 SG_ Lowest_Cell_Temperature : 26|11@1+ (0.1,-100) [-100|104.7] "degC" Pack01BMSLeader
 SG_ Highest_Cell_Temperature : 37|11@1+ (0.1,-100) [-100|104.7] "degC" Pack01BMSLeader
 SG_ Battery_Isolation : 48|16@1+ (0.1,0) [0|6553.5] "ohm per V" Pack01BMSLeader

BO_ 2360592844 Feedback_3_Pack04BMS: 8 Pack04BMS
 SG_ Lowest_Cell_Voltage : 0|13@1+ (0.001,0) [0|8.191] "V" Pack01BMSLeader
 SG_ Highest_Cell_Voltage : 13|13@1+ (0.001,0) [0|8.191] "V" Pack01BMSLeader
 SG_ Lowest_Cell_Temperature : 26|11@1+ (0.1,-100) [-100|104.7] "degC" Pack01BMSLeader
 SG_ Highest_Cell_Temperature : 37|11@1+ (0.1,-100) [-100|104.7] "degC" Pack01BMSLeader
 SG_ Battery_Isolation : 48|16@1+ (0.1,0) [0|6553.5] "ohm per V" Pack01BMSLeader

BO_ 2360592845 Feedback_3_Pack05BMS: 8 Pack05BMS
 SG_ Lowest_Cell_Voltage : 0|13@1+ (0.001,0) [0|8.191] "V" Pack01BMSLeader
 SG_ Highest_Cell_Voltage : 13|13@1+ (0.001,0) [0|8.191] "V" Pack01BMSLeader
 SG_ Lowest_Cell_Temperature : 26|11@1+ (0.1,-100) [-100|104.7] "degC" Pack01BMSLeader
 SG_ Highest_Cell_Temperature : 37|11@1+ (0.1,-100) [-100|104.7] "degC" Pack01BMSLeader
 SG_ Battery_Isolation : 48|16@1+ (0.1,0) [0|6553.5] "ohm per V" Pack01BMSLeader

BO_ 2360592846 Feedback_3_Pack06BMS: 8 Pack06BMS
 SG_ Lowest_Cell_Voltage : 0|13@1+ (0.001,0) [0|8.191] "V" Pack01BMSLeader
 SG_ Highest_Cell_Voltage : 13|13@1+ (0.001,0) [0|8.191] "V" Pack01BMSLeader
 SG_ Lowest_Cell_Temperature : 26|11@1+ (0.1,-100) [-100|104.7] "degC" Pack01BMSLeader
 SG_ Highest_Cell_Temperature : 37|11@1+ (0.1,-100) [-100|104.7] "degC" Pack01BMSLeader
 SG_ Battery_Isolation : 48|16@1+ (0.1,0) [0|6553.5] "ohm per V" Pack01BMSLeader

BO_ 2360592847 Feedback_3_Pack07BMS: 8 Pack07BMS
 SG_ Lowest_Cell_Voltage : 0|13@1+ (0.001,0) [0|8.191] "V" Pack01BMSLeader
 SG_ Highest_Cell_Voltage : 13|13@1+ (0.001,0) [0|8.191] "V" Pack01BMSLeader
 SG_ Lowest_Cell_Temperature : 26|11@1+ (0.1,-100) [-100|104.7] "degC" Pack01BMSLeader
 SG_ Highest_Cell_Temperature : 37|11@1+ (0.1,-100) [-100|104.7] "degC" Pack01BMSLeader
 SG_ Battery_Isolation : 48|16@1+ (0.1,0) [0|6553.5] "ohm per V" Pack01BMSLeader

BO_ 2360592848 Feedback_3_Pack08BMS: 8 Pack08BMS
 SG_ Lowest_Cell_Voltage : 0|13@1+ (0.001,0) [0|8.191] "V" Pack01BMSLeader
 SG_ Highest_Cell_Voltage : 13|13@1+ (0.001,0) [0|8.191] "V" Pack01BMSLeader
 SG_ Lowest_Cell_Temperature : 26|11@1+ (0.1,-100) [-100|104.7] "degC" Pack01BMSLeader
 SG_ Highest_Cell_Temperature : 37|11@1+ (0.1,-100) [-100|104.7] "degC" Pack01BMSLeader
 SG_ Battery_Isolation : 48|16@1+ (0.1,0) [0|6553.5] "ohm per V" Pack01BMSLeader

BO_ 2360592849 Feedback_3_Pack09BMS: 8 Pack09BMS
 SG_ Lowest_Cell_Voltage : 0|13@1+ (0.001,0) [0|8.191] "V" Pack01BMSLeader
 SG_ Highest_Cell_Voltage : 13|13@1+ (0.001,0) [0|8.191] "V" Pack01BMSLeader
 SG_ Lowest_Cell_Temperature : 26|11@1+ (0.1,-100) [-100|104.7] "degC" Pack01BMSLeader
 SG_ Highest_Cell_Temperature : 37|11@1+ (0.1,-100) [-100|104.7] "degC" Pack01BMSLeader
 SG_ Battery_Isolation : 48|16@1+ (0.1,0) [0|6553.5] "ohm per V" Pack01BMSLeader

BO_ 2360592850 Feedback_3_Pack10BMS: 8 Pack10BMS
 SG_ Lowest_Cell_Voltage : 0|13@1+ (0.001,0) [0|8.191] "V" Pack01BMSLeader
 SG_ Highest_Cell_Voltage : 13|13@1+ (0.001,0) [0|8.191] "V" Pack01BMSLeader
 SG_ Lowest_Cell_Temperature : 26|11@1+ (0.1,-100) [-100|104.7] "degC" Pack01BMSLeader
 SG_ Highest_Cell_Temperature : 37|11@1+ (0.1,-100) [-100|104.7] "degC" Pack01BMSLeader
 SG_ Battery_Isolation : 48|16@1+ (0.1,0) [0|6553.5] "ohm per V" Pack01BMSLeader

BO_ 2360592851 Feedback_3_Pack11BMS: 8 Pack11BMS
 SG_ Lowest_Cell_Voltage : 0|13@1+ (0.001,0) [0|8.191] "V" Pack01BMSLeader
 SG_ Highest_Cell_Voltage : 13|13@1+ (0.001,0) [0|8.191] "V" Pack01BMSLeader
 SG_ Lowest_Cell_Temperature : 26|11@1+ (0.1,-100) [-100|104.7] "degC" Pack01BMSLeader
 SG_ Highest_Cell_Temperature : 37|11@1+ (0.1,-100) [-100|104.7] "degC" Pack01BMSLeader
 SG_ Battery_Isolation : 48|16@1+ (0.1,0) [0|6553.5] "ohm per V" Pack01BMSLeader

BO_ 2360592852 Feedback_3_Pack12BMS: 8 Pack12BMS
 SG_ Lowest_Cell_Voltage : 0|13@1+ (0.001,0) [0|8.191] "V" Pack01BMSLeader
 SG_ Highest_Cell_Voltage : 13|13@1+ (0.001,0) [0|8.191] "V" Pack01BMSLeader
 SG_ Lowest_Cell_Temperature : 26|11@1+ (0.1,-100) [-100|104.7] "degC" Pack01BMSLeader
 SG_ Highest_Cell_Temperature : 37|11@1+ (0.1,-100) [-100|104.7] "degC" Pack01BMSLeader
 SG_ Battery_Isolation : 48|16@1+ (0.1,0) [0|6553.5] "ohm per V" Pack01BMSLeader

BO_ 2360592853 Feedback_3_Pack13BMS: 8 Pack13BMS
 SG_ Lowest_Cell_Voltage : 0|13@1+ (0.001,0) [0|8.191] "V" Pack01BMSLeader
 SG_ Highest_Cell_Voltage : 13|13@1+ (0.001,0) [0|8.191] "V" Pack01BMSLeader
 SG_ Lowest_Cell_Temperature : 26|11@1+ (0.1,-100) [-100|104.7] "degC" Pack01BMSLeader
 SG_ Highest_Cell_Temperature : 37|11@1+ (0.1,-100) [-100|104.7] "degC" Pack01BMSLeader
 SG_ Battery_Isolation : 48|16@1+ (0.1,0) [0|6553.5] "ohm per V" Pack01BMSLeader

BO_ 2360592854 Feedback_3_Pack14BMS: 8 Pack14BMS
 SG_ Lowest_Cell_Voltage : 0|13@1+ (0.001,0) [0|8.191] "V" Pack01BMSLeader
 SG_ Highest_Cell_Voltage : 13|13@1+ (0.001,0) [0|8.191] "V" Pack01BMSLeader
 SG_ Lowest_Cell_Temperature : 26|11@1+ (0.1,-100) [-100|104.7] "degC" Pack01BMSLeader
 SG_ Highest_Cell_Temperature : 37|11@1+ (0.1,-100) [-100|104.7] "degC" Pack01BMSLeader
 SG_ Battery_Isolation : 48|16@1+ (0.1,0) [0|6553.5] "ohm per V" Pack01BMSLeader

BO_ 2360592855 Feedback_3_Pack15BMS: 8 Pack15BMS
 SG_ Lowest_Cell_Voltage : 0|13@1+ (0.001,0) [0|8.191] "V" Pack01BMSLeader
 SG_ Highest_Cell_Voltage : 13|13@1+ (0.001,0) [0|8.191] "V" Pack01BMSLeader
 SG_ Lowest_Cell_Temperature : 26|11@1+ (0.1,-100) [-100|104.7] "degC" Pack01BMSLeader
 SG_ Highest_Cell_Temperature : 37|11@1+ (0.1,-100) [-100|104.7] "degC" Pack01BMSLeader
 SG_ Battery_Isolation : 48|16@1+ (0.1,0) [0|6553.5] "ohm per V" Pack01BMSLeader

BO_ 2360592856 Feedback_3_Pack16BMS: 8 Pack16BMS
 SG_ Lowest_Cell_Voltage : 0|13@1+ (0.001,0) [0|8.191] "V" Pack01BMSLeader
 SG_ Highest_Cell_Voltage : 13|13@1+ (0.001,0) [0|8.191] "V" Pack01BMSLeader
 SG_ Lowest_Cell_Temperature : 26|11@1+ (0.1,-100) [-100|104.7] "degC" Pack01BMSLeader
 SG_ Highest_Cell_Temperature : 37|11@1+ (0.1,-100) [-100|104.7] "degC" Pack01BMSLeader
 SG_ Battery_Isolation : 48|16@1+ (0.1,0) [0|6553.5] "ohm per V" Pack01BMSLeader

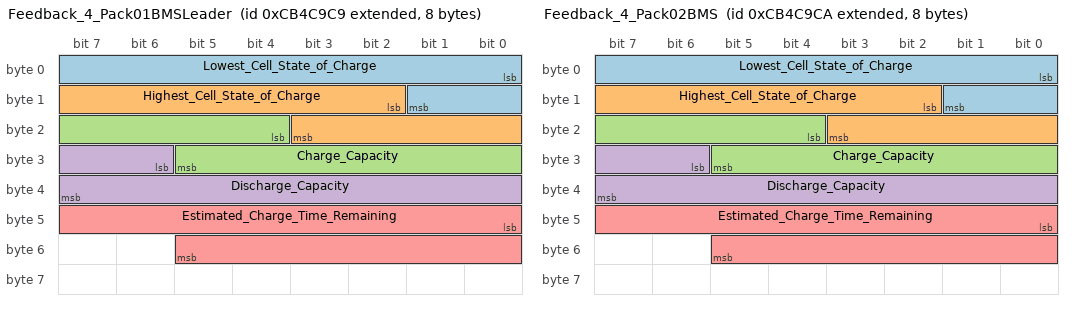
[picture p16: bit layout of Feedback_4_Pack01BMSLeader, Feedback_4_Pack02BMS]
BO_ 2360658377 Feedback_4_Pack01BMSLeader: 8 Pack01BMSLeader
 SG_ Lowest_Cell_State_of_Charge : 0|10@1+ (0.1,0) [0|102.3] "%" Pack01BMSLeader
 SG_ Highest_Cell_State_of_Charge : 10|10@1+ (0.1,0) [0|102.3] "%" Pack01BMSLeader
 SG_ Charge_Capacity : 20|10@1+ (0.1,0) [0|102.3] "Ah" Pack01BMSLeader
 SG_ Discharge_Capacity : 30|10@1+ (0.1,0) [0|102.3] "Ah" Pack01BMSLeader
 SG_ Estimated_Charge_Time_Remaining : 40|14@1+ (1,0) [0|16383] "min" Pack01BMSLeader

BO_ 2360658378 Feedback_4_Pack02BMS: 8 Pack02BMS
 SG_ Lowest_Cell_State_of_Charge : 0|10@1+ (0.1,0) [0|102.3] "%" Pack01BMSLeader
 SG_ Highest_Cell_State_of_Charge : 10|10@1+ (0.1,0) [0|102.3] "%" Pack01BMSLeader
 SG_ Charge_Capacity : 20|10@1+ (0.1,0) [0|102.3] "Ah" Pack01BMSLeader
 SG_ Discharge_Capacity : 30|10@1+ (0.1,0) [0|102.3] "Ah" Pack01BMSLeader
 SG_ Estimated_Charge_Time_Remaining : 40|14@1+ (1,0) [0|16383] "min" Pack01BMSLeader

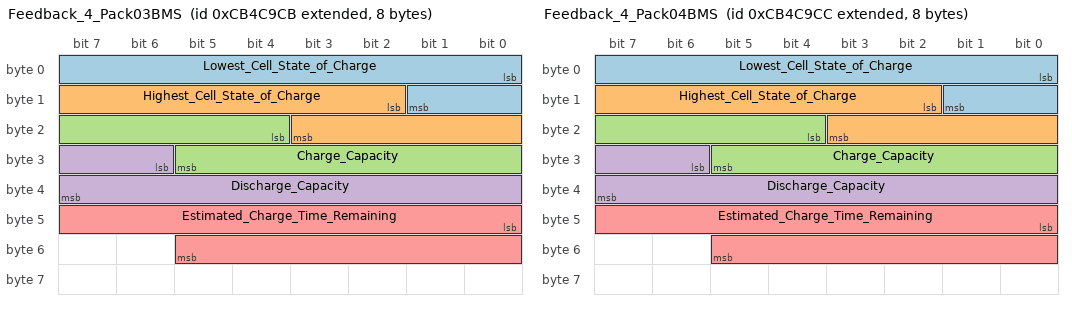
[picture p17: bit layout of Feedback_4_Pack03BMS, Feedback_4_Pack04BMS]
BO_ 2360658379 Feedback_4_Pack03BMS: 8 Pack03BMS
 SG_ Lowest_Cell_State_of_Charge : 0|10@1+ (0.1,0) [0|102.3] "%" Pack01BMSLeader
 SG_ Highest_Cell_State_of_Charge : 10|10@1+ (0.1,0) [0|102.3] "%" Pack01BMSLeader
 SG_ Charge_Capacity : 20|10@1+ (0.1,0) [0|102.3] "Ah" Pack01BMSLeader
 SG_ Discharge_Capacity : 30|10@1+ (0.1,0) [0|102.3] "Ah" Pack01BMSLeader
 SG_ Estimated_Charge_Time_Remaining : 40|14@1+ (1,0) [0|16383] "min" Pack01BMSLeader

BO_ 2360658380 Feedback_4_Pack04BMS: 8 Pack04BMS
 SG_ Lowest_Cell_State_of_Charge : 0|10@1+ (0.1,0) [0|102.3] "%" Pack01BMSLeader
 SG_ Highest_Cell_State_of_Charge : 10|10@1+ (0.1,0) [0|102.3] "%" Pack01BMSLeader
 SG_ Charge_Capacity : 20|10@1+ (0.1,0) [0|102.3] "Ah" Pack01BMSLeader
 SG_ Discharge_Capacity : 30|10@1+ (0.1,0) [0|102.3] "Ah" Pack01BMSLeader
 SG_ Estimated_Charge_Time_Remaining : 40|14@1+ (1,0) [0|16383] "min" Pack01BMSLeader

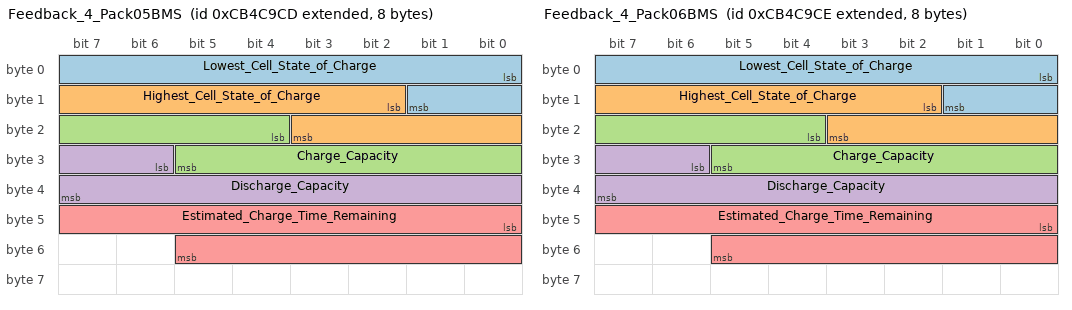
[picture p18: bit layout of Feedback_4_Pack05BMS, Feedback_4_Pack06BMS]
BO_ 2360658381 Feedback_4_Pack05BMS: 8 Pack05BMS
 SG_ Lowest_Cell_State_of_Charge : 0|10@1+ (0.1,0) [0|102.3] "%" Pack01BMSLeader
 SG_ Highest_Cell_State_of_Charge : 10|10@1+ (0.1,0) [0|102.3] "%" Pack01BMSLeader
 SG_ Charge_Capacity : 20|10@1+ (0.1,0) [0|102.3] "Ah" Pack01BMSLeader
 SG_ Discharge_Capacity : 30|10@1+ (0.1,0) [0|102.3] "Ah" Pack01BMSLeader
 SG_ Estimated_Charge_Time_Remaining : 40|14@1+ (1,0) [0|16383] "min" Pack01BMSLeader

BO_ 2360658382 Feedback_4_Pack06BMS: 8 Pack06BMS
 SG_ Lowest_Cell_State_of_Charge : 0|10@1+ (0.1,0) [0|102.3] "%" Pack01BMSLeader
 SG_ Highest_Cell_State_of_Charge : 10|10@1+ (0.1,0) [0|102.3] "%" Pack01BMSLeader
 SG_ Charge_Capacity : 20|10@1+ (0.1,0) [0|102.3] "Ah" Pack01BMSLeader
 SG_ Discharge_Capacity : 30|10@1+ (0.1,0) [0|102.3] "Ah" Pack01BMSLeader
 SG_ Estimated_Charge_Time_Remaining : 40|14@1+ (1,0) [0|16383] "min" Pack01BMSLeader

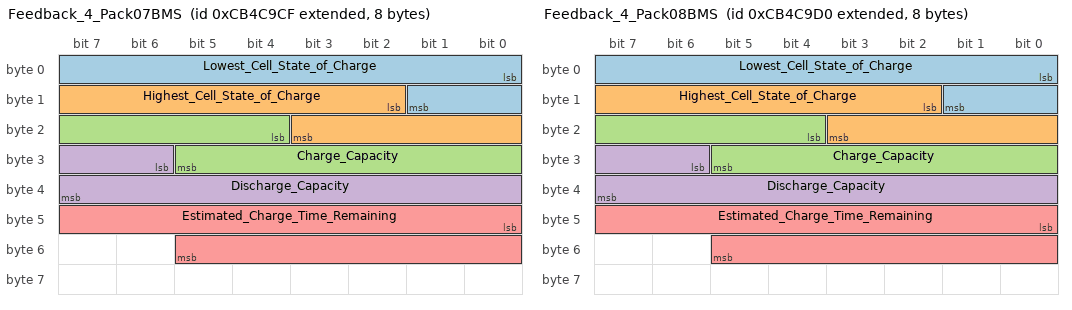
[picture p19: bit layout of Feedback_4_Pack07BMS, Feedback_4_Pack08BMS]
BO_ 2360658383 Feedback_4_Pack07BMS: 8 Pack07BMS
 SG_ Lowest_Cell_State_of_Charge : 0|10@1+ (0.1,0) [0|102.3] "%" Pack01BMSLeader
 SG_ Highest_Cell_State_of_Charge : 10|10@1+ (0.1,0) [0|102.3] "%" Pack01BMSLeader
 SG_ Charge_Capacity : 20|10@1+ (0.1,0) [0|102.3] "Ah" Pack01BMSLeader
 SG_ Discharge_Capacity : 30|10@1+ (0.1,0) [0|102.3] "Ah" Pack01BMSLeader
 SG_ Estimated_Charge_Time_Remaining : 40|14@1+ (1,0) [0|16383] "min" Pack01BMSLeader

BO_ 2360658384 Feedback_4_Pack08BMS: 8 Pack08BMS
 SG_ Lowest_Cell_State_of_Charge : 0|10@1+ (0.1,0) [0|102.3] "%" Pack01BMSLeader
 SG_ Highest_Cell_State_of_Charge : 10|10@1+ (0.1,0) [0|102.3] "%" Pack01BMSLeader
 SG_ Charge_Capacity : 20|10@1+ (0.1,0) [0|102.3] "Ah" Pack01BMSLeader
 SG_ Discharge_Capacity : 30|10@1+ (0.1,0) [0|102.3] "Ah" Pack01BMSLeader
 SG_ Estimated_Charge_Time_Remaining : 40|14@1+ (1,0) [0|16383] "min" Pack01BMSLeader

BO_ 2360658385 Feedback_4_Pack09BMS: 8 Pack09BMS
 SG_ Lowest_Cell_State_of_Charge : 0|10@1+ (0.1,0) [0|102.3] "%" Pack01BMSLeader
 SG_ Highest_Cell_State_of_Charge : 10|10@1+ (0.1,0) [0|102.3] "%" Pack01BMSLeader
 SG_ Charge_Capacity : 20|10@1+ (0.1,0) [0|102.3] "Ah" Pack01BMSLeader
 SG_ Discharge_Capacity : 30|10@1+ (0.1,0) [0|102.3] "Ah" Pack01BMSLeader
 SG_ Estimated_Charge_Time_Remaining : 40|14@1+ (1,0) [0|16383] "min" Pack01BMSLeader

BO_ 2360658386 Feedback_4_Pack10BMS: 8 Pack10BMS
 SG_ Lowest_Cell_State_of_Charge : 0|10@1+ (0.1,0) [0|102.3] "%" Pack01BMSLeader
 SG_ Highest_Cell_State_of_Charge : 10|10@1+ (0.1,0) [0|102.3] "%" Pack01BMSLeader
 SG_ Charge_Capacity : 20|10@1+ (0.1,0) [0|102.3] "Ah" Pack01BMSLeader
 SG_ Discharge_Capacity : 30|10@1+ (0.1,0) [0|102.3] "Ah" Pack01BMSLeader
 SG_ Estimated_Charge_Time_Remaining : 40|14@1+ (1,0) [0|16383] "min" Pack01BMSLeader

BO_ 2360658387 Feedback_4_Pack11BMS: 8 Pack11BMS
 SG_ Lowest_Cell_State_of_Charge : 0|10@1+ (0.1,0) [0|102.3] "%" Pack01BMSLeader
 SG_ Highest_Cell_State_of_Charge : 10|10@1+ (0.1,0) [0|102.3] "%" Pack01BMSLeader
 SG_ Charge_Capacity : 20|10@1+ (0.1,0) [0|102.3] "Ah" Pack01BMSLeader
 SG_ Discharge_Capacity : 30|10@1+ (0.1,0) [0|102.3] "Ah" Pack01BMSLeader
 SG_ Estimated_Charge_Time_Remaining : 40|14@1+ (1,0) [0|16383] "min" Pack01BMSLeader

BO_ 2360658388 Feedback_4_Pack12BMS: 8 Pack12BMS
 SG_ Lowest_Cell_State_of_Charge : 0|10@1+ (0.1,0) [0|102.3] "%" Pack01BMSLeader
 SG_ Highest_Cell_State_of_Charge : 10|10@1+ (0.1,0) [0|102.3] "%" Pack01BMSLeader
 SG_ Charge_Capacity : 20|10@1+ (0.1,0) [0|102.3] "Ah" Pack01BMSLeader
 SG_ Discharge_Capacity : 30|10@1+ (0.1,0) [0|102.3] "Ah" Pack01BMSLeader
 SG_ Estimated_Charge_Time_Remaining : 40|14@1+ (1,0) [0|16383] "min" Pack01BMSLeader

BO_ 2360658389 Feedback_4_Pack13BMS: 8 Pack13BMS
 SG_ Lowest_Cell_State_of_Charge : 0|10@1+ (0.1,0) [0|102.3] "%" Pack01BMSLeader
 SG_ Highest_Cell_State_of_Charge : 10|10@1+ (0.1,0) [0|102.3] "%" Pack01BMSLeader
 SG_ Charge_Capacity : 20|10@1+ (0.1,0) [0|102.3] "Ah" Pack01BMSLeader
 SG_ Discharge_Capacity : 30|10@1+ (0.1,0) [0|102.3] "Ah" Pack01BMSLeader
 SG_ Estimated_Charge_Time_Remaining : 40|14@1+ (1,0) [0|16383] "min" Pack01BMSLeader

BO_ 2360658390 Feedback_4_Pack14BMS: 8 Pack14BMS
 SG_ Lowest_Cell_State_of_Charge : 0|10@1+ (0.1,0) [0|102.3] "%" Pack01BMSLeader
 SG_ Highest_Cell_State_of_Charge : 10|10@1+ (0.1,0) [0|102.3] "%" Pack01BMSLeader
 SG_ Charge_Capacity : 20|10@1+ (0.1,0) [0|102.3] "Ah" Pack01BMSLeader
 SG_ Discharge_Capacity : 30|10@1+ (0.1,0) [0|102.3] "Ah" Pack01BMSLeader
 SG_ Estimated_Charge_Time_Remaining : 40|14@1+ (1,0) [0|16383] "min" Pack01BMSLeader

BO_ 2360658391 Feedback_4_Pack15BMS: 8 Pack15BMS
 SG_ Lowest_Cell_State_of_Charge : 0|10@1+ (0.1,0) [0|102.3] "%" Pack01BMSLeader
 SG_ Highest_Cell_State_of_Charge : 10|10@1+ (0.1,0) [0|102.3] "%" Pack01BMSLeader
 SG_ Charge_Capacity : 20|10@1+ (0.1,0) [0|102.3] "Ah" Pack01BMSLeader
 SG_ Discharge_Capacity : 30|10@1+ (0.1,0) [0|102.3] "Ah" Pack01BMSLeader
 SG_ Estimated_Charge_Time_Remaining : 40|14@1+ (1,0) [0|16383] "min" Pack01BMSLeader

BO_ 2360658392 Feedback_4_Pack16BMS: 8 Pack16BMS
 SG_ Lowest_Cell_State_of_Charge : 0|10@1+ (0.1,0) [0|102.3] "%" Pack01BMSLeader
 SG_ Highest_Cell_State_of_Charge : 10|10@1+ (0.1,0) [0|102.3] "%" Pack01BMSLeader
 SG_ Charge_Capacity : 20|10@1+ (0.1,0) [0|102.3] "Ah" Pack01BMSLeader
 SG_ Discharge_Capacity : 30|10@1+ (0.1,0) [0|102.3] "Ah" Pack01BMSLeader
 SG_ Estimated_Charge_Time_Remaining : 40|14@1+ (1,0) [0|16383] "min" Pack01BMSLeader

BO_ 2360723913 Feedback_5_Pack01BMSLeader: 8 Pack01BMSLeader
 SG_ Total_Lifetime_Energy_Input : 0|32@1+ (1,0) [0|4294967295] "kWh" Pack01BMSLeader
 SG_ Total_Lifetime_Energy_Output : 32|32@1+ (1,0) [0|4294967295] "kWh" Pack01BMSLeader

BO_ 2360723914 Feedback_5_Pack02BMS: 8 Pack02BMS
 SG_ Total_Lifetime_Energy_Input : 0|32@1+ (1,0) [0|4294967295] "kWh" Pack01BMSLeader
 SG_ Total_Lifetime_Energy_Output : 32|32@1+ (1,0) [0|4294967295] "kWh" Pack01BMSLeader

BO_ 2360723915 Feedback_5_Pack03BMS: 8 Pack03BMS
 SG_ Total_Lifetime_Energy_Input : 0|32@1+ (1,0) [0|4294967295] "kWh" Pack01BMSLeader
 SG_ Total_Lifetime_Energy_Output : 32|32@1+ (1,0) [0|4294967295] "kWh" Pack01BMSLeader

BO_ 2360723916 Feedback_5_Pack04BMS: 8 Pack04BMS
 SG_ Total_Lifetime_Energy_Input : 0|32@1+ (1,0) [0|4294967295] "kWh" Pack01BMSLeader
 SG_ Total_Lifetime_Energy_Output : 32|32@1+ (1,0) [0|4294967295] "kWh" Pack01BMSLeader

BO_ 2360723917 Feedback_5_Pack05BMS: 8 Pack05BMS
 SG_ Total_Lifetime_Energy_Input : 0|32@1+ (1,0) [0|4294967295] "kWh" Pack01BMSLeader
 SG_ Total_Lifetime_Energy_Output : 32|32@1+ (1,0) [0|4294967295] "kWh" Pack01BMSLeader

BO_ 2360723918 Feedback_5_Pack06BMS: 8 Pack06BMS
 SG_ Total_Lifetime_Energy_Input : 0|32@1+ (1,0) [0|4294967295] "kWh" Pack01BMSLeader
 SG_ Total_Lifetime_Energy_Output : 32|32@1+ (1,0) [0|4294967295] "kWh" Pack01BMSLeader

BO_ 2360723919 Feedback_5_Pack07BMS: 8 Pack07BMS
 SG_ Total_Lifetime_Energy_Input : 0|32@1+ (1,0) [0|4294967295] "kWh" Pack01BMSLeader
 SG_ Total_Lifetime_Energy_Output : 32|32@1+ (1,0) [0|4294967295] "kWh" Pack01BMSLeader

BO_ 2360723920 Feedback_5_Pack08BMS: 8 Pack08BMS
 SG_ Total_Lifetime_Energy_Input : 0|32@1+ (1,0) [0|4294967295] "kWh" Pack01BMSLeader
 SG_ Total_Lifetime_Energy_Output : 32|32@1+ (1,0) [0|4294967295] "kWh" Pack01BMSLeader

BO_ 2360723921 Feedback_5_Pack09BMS: 8 Pack09BMS
 SG_ Total_Lifetime_Energy_Input : 0|32@1+ (1,0) [0|4294967295] "kWh" Pack01BMSLeader
 SG_ Total_Lifetime_Energy_Output : 32|32@1+ (1,0) [0|4294967295] "kWh" Pack01BMSLeader

BO_ 2360723922 Feedback_5_Pack10BMS: 8 Pack10BMS
 SG_ Total_Lifetime_Energy_Input : 0|32@1+ (1,0) [0|4294967295] "kWh" Pack01BMSLeader
 SG_ Total_Lifetime_Energy_Output : 32|32@1+ (1,0) [0|4294967295] "kWh" Pack01BMSLeader

BO_ 2360723923 Feedback_5_Pack11BMS: 8 Pack11BMS
 SG_ Total_Lifetime_Energy_Input : 0|32@1+ (1,0) [0|4294967295] "kWh" Pack01BMSLeader
 SG_ Total_Lifetime_Energy_Output : 32|32@1+ (1,0) [0|4294967295] "kWh" Pack01BMSLeader

BO_ 2360723924 Feedback_5_Pack12BMS: 8 Pack12BMS
 SG_ Total_Lifetime_Energy_Input : 0|32@1+ (1,0) [0|4294967295] "kWh" Pack01BMSLeader
 SG_ Total_Lifetime_Energy_Output : 32|32@1+ (1,0) [0|4294967295] "kWh" Pack01BMSLeader

BO_ 2360723925 Feedback_5_Pack13BMS: 8 Pack13BMS
 SG_ Total_Lifetime_Energy_Input : 0|32@1+ (1,0) [0|4294967295] "kWh" Pack01BMSLeader
 SG_ Total_Lifetime_Energy_Output : 32|32@1+ (1,0) [0|4294967295] "kWh" Pack01BMSLeader

BO_ 2360723926 Feedback_5_Pack14BMS: 8 Pack14BMS
 SG_ Total_Lifetime_Energy_Input : 0|32@1+ (1,0) [0|4294967295] "kWh" Pack01BMSLeader
 SG_ Total_Lifetime_Energy_Output : 32|32@1+ (1,0) [0|4294967295] "kWh" Pack01BMSLeader

BO_ 2360723927 Feedback_5_Pack15BMS: 8 Pack15BMS
 SG_ Total_Lifetime_Energy_Input : 0|32@1+ (1,0) [0|4294967295] "kWh" Pack01BMSLeader
 SG_ Total_Lifetime_Energy_Output : 32|32@1+ (1,0) [0|4294967295] "kWh" Pack01BMSLeader

BO_ 2360723928 Feedback_5_Pack16BMS: 8 Pack16BMS
 SG_ Total_Lifetime_Energy_Input : 0|32@1+ (1,0) [0|4294967295] "kWh" Pack01BMSLeader
 SG_ Total_Lifetime_Energy_Output : 32|32@1+ (1,0) [0|4294967295] "kWh" Pack01BMSLeader

BO_ 2360789449 Feedback_6_Pack01BMSLeader: 8 Pack01BMSLeader
 SG_ Available_Charge_Current : 0|12@1+ (0.05,0) [0|204.75] "A" Pack01BMSLeader
 SG_ Available_Discharge_Current : 12|12@1+ (0.05,0) [0|204.75] "A" Pack01BMSLeader
 SG_ Available_Pulse_Charge_Current : 24|12@1+ (0.05,0) [0|204.75] "A" Pack01BMSLeader
 SG_ Available_Pulse_Discharge_Curren : 36|12@1+ (0.05,0) [0|204.75] "A" Pack01BMSLeader

BO_ 2360789450 Feedback_6_Pack02BMS: 8 Pack02BMS
 SG_ Available_Charge_Current : 0|12@1+ (0.05,0) [0|204.75] "A" Pack01BMSLeader
 SG_ Available_Discharge_Current : 12|12@1+ (0.05,0) [0|204.75] "A" Pack01BMSLeader
 SG_ Available_Pulse_Charge_Current : 24|12@1+ (0.05,0) [0|204.75] "A" Pack01BMSLeader
 SG_ Available_Pulse_Discharge_Curren : 36|12@1+ (0.05,0) [0|204.75] "A" Pack01BMSLeader

BO_ 2360789451 Feedback_6_Pack03BMS: 8 Pack03BMS
 SG_ Available_Charge_Current : 0|12@1+ (0.05,0) [0|204.75] "A" Pack01BMSLeader
 SG_ Available_Discharge_Current : 12|12@1+ (0.05,0) [0|204.75] "A" Pack01BMSLeader
 SG_ Available_Pulse_Charge_Current : 24|12@1+ (0.05,0) [0|204.75] "A" Pack01BMSLeader
 SG_ Available_Pulse_Discharge_Curren : 36|12@1+ (0.05,0) [0|204.75] "A" Pack01BMSLeader

BO_ 2360789452 Feedback_6_Pack04BMS: 8 Pack04BMS
 SG_ Available_Charge_Current : 0|12@1+ (0.05,0) [0|204.75] "A" Pack01BMSLeader
 SG_ Available_Discharge_Current : 12|12@1+ (0.05,0) [0|204.75] "A" Pack01BMSLeader
 SG_ Available_Pulse_Charge_Current : 24|12@1+ (0.05,0) [0|204.75] "A" Pack01BMSLeader
 SG_ Available_Pulse_Discharge_Curren : 36|12@1+ (0.05,0) [0|204.75] "A" Pack01BMSLeader

BO_ 2360789453 Feedback_6_Pack05BMS: 8 Pack05BMS
 SG_ Available_Charge_Current : 0|12@1+ (0.05,0) [0|204.75] "A" Pack01BMSLeader
 SG_ Available_Discharge_Current : 12|12@1+ (0.05,0) [0|204.75] "A" Pack01BMSLeader
 SG_ Available_Pulse_Charge_Current : 24|12@1+ (0.05,0) [0|204.75] "A" Pack01BMSLeader
 SG_ Available_Pulse_Discharge_Curren : 36|12@1+ (0.05,0) [0|204.75] "A" Pack01BMSLeader

BO_ 2360789454 Feedback_6_Pack06BMS: 8 Pack06BMS
 SG_ Available_Charge_Current : 0|12@1+ (0.05,0) [0|204.75] "A" Pack01BMSLeader
 SG_ Available_Discharge_Current : 12|12@1+ (0.05,0) [0|204.75] "A" Pack01BMSLeader
 SG_ Available_Pulse_Charge_Current : 24|12@1+ (0.05,0) [0|204.75] "A" Pack01BMSLeader
 SG_ Available_Pulse_Discharge_Curren : 36|12@1+ (0.05,0) [0|204.75] "A" Pack01BMSLeader

BO_ 2360789455 Feedback_6_Pack07BMS: 8 Pack07BMS
 SG_ Available_Charge_Current : 0|12@1+ (0.05,0) [0|204.75] "A" Pack01BMSLeader
 SG_ Available_Discharge_Current : 12|12@1+ (0.05,0) [0|204.75] "A" Pack01BMSLeader
 SG_ Available_Pulse_Charge_Current : 24|12@1+ (0.05,0) [0|204.75] "A" Pack01BMSLeader
 SG_ Available_Pulse_Discharge_Curren : 36|12@1+ (0.05,0) [0|204.75] "A" Pack01BMSLeader

BO_ 2360789456 Feedback_6_Pack08BMS: 8 Pack08BMS
 SG_ Available_Charge_Current : 0|12@1+ (0.05,0) [0|204.75] "A" Pack01BMSLeader
 SG_ Available_Discharge_Current : 12|12@1+ (0.05,0) [0|204.75] "A" Pack01BMSLeader
 SG_ Available_Pulse_Charge_Current : 24|12@1+ (0.05,0) [0|204.75] "A" Pack01BMSLeader
 SG_ Available_Pulse_Discharge_Curren : 36|12@1+ (0.05,0) [0|204.75] "A" Pack01BMSLeader

BO_ 2360789457 Feedback_6_Pack09BMS: 8 Pack09BMS
 SG_ Available_Charge_Current : 0|12@1+ (0.05,0) [0|204.75] "A" Pack01BMSLeader
 SG_ Available_Discharge_Current : 12|12@1+ (0.05,0) [0|204.75] "A" Pack01BMSLeader
 SG_ Available_Pulse_Charge_Current : 24|12@1+ (0.05,0) [0|204.75] "A" Pack01BMSLeader
 SG_ Available_Pulse_Discharge_Curren : 36|12@1+ (0.05,0) [0|204.75] "A" Pack01BMSLeader

BO_ 2360789458 Feedback_6_Pack10BMS: 8 Pack10BMS
 SG_ Available_Charge_Current : 0|12@1+ (0.05,0) [0|204.75] "A" Pack01BMSLeader
 SG_ Available_Discharge_Current : 12|12@1+ (0.05,0) [0|204.75] "A" Pack01BMSLeader
 SG_ Available_Pulse_Charge_Current : 24|12@1+ (0.05,0) [0|204.75] "A" Pack01BMSLeader
 SG_ Available_Pulse_Discharge_Curren : 36|12@1+ (0.05,0) [0|204.75] "A" Pack01BMSLeader

BO_ 2360789459 Feedback_6_Pack11BMS: 8 Pack11BMS
 SG_ Available_Charge_Current : 0|12@1+ (0.05,0) [0|204.75] "A" Pack01BMSLeader
 SG_ Available_Discharge_Current : 12|12@1+ (0.05,0) [0|204.75] "A" Pack01BMSLeader
 SG_ Available_Pulse_Charge_Current : 24|12@1+ (0.05,0) [0|204.75] "A" Pack01BMSLeader
 SG_ Available_Pulse_Discharge_Curren : 36|12@1+ (0.05,0) [0|204.75] "A" Pack01BMSLeader

BO_ 2360789460 Feedback_6_Pack12BMS: 8 Pack12BMS
 SG_ Available_Charge_Current : 0|12@1+ (0.05,0) [0|204.75] "A" Pack01BMSLeader
 SG_ Available_Discharge_Current : 12|12@1+ (0.05,0) [0|204.75] "A" Pack01BMSLeader
 SG_ Available_Pulse_Charge_Current : 24|12@1+ (0.05,0) [0|204.75] "A" Pack01BMSLeader
 SG_ Available_Pulse_Discharge_Curren : 36|12@1+ (0.05,0) [0|204.75] "A" Pack01BMSLeader

BO_ 2360789461 Feedback_6_Pack13BMS: 8 Pack13BMS
 SG_ Available_Charge_Current : 0|12@1+ (0.05,0) [0|204.75] "A" Pack01BMSLeader
 SG_ Available_Discharge_Current : 12|12@1+ (0.05,0) [0|204.75] "A" Pack01BMSLeader
 SG_ Available_Pulse_Charge_Current : 24|12@1+ (0.05,0) [0|204.75] "A" Pack01BMSLeader
 SG_ Available_Pulse_Discharge_Curren : 36|12@1+ (0.05,0) [0|204.75] "A" Pack01BMSLeader

BO_ 2360789462 Feedback_6_Pack14BMS: 8 Pack14BMS
 SG_ Available_Charge_Current : 0|12@1+ (0.05,0) [0|204.75] "A" Pack01BMSLeader
 SG_ Available_Discharge_Current : 12|12@1+ (0.05,0) [0|204.75] "A" Pack01BMSLeader
 SG_ Available_Pulse_Charge_Current : 24|12@1+ (0.05,0) [0|204.75] "A" Pack01BMSLeader
 SG_ Available_Pulse_Discharge_Curren : 36|12@1+ (0.05,0) [0|204.75] "A" Pack01BMSLeader

BO_ 2360789463 Feedback_6_Pack15BMS: 8 Pack15BMS
 SG_ Available_Charge_Current : 0|12@1+ (0.05,0) [0|204.75] "A" Pack01BMSLeader
 SG_ Available_Discharge_Current : 12|12@1+ (0.05,0) [0|204.75] "A" Pack01BMSLeader
 SG_ Available_Pulse_Charge_Current : 24|12@1+ (0.05,0) [0|204.75] "A" Pack01BMSLeader
 SG_ Available_Pulse_Discharge_Curren : 36|12@1+ (0.05,0) [0|204.75] "A" Pack01BMSLeader

BO_ 2360789464 Feedback_6_Pack16BMS: 8 Pack16BMS
 SG_ Available_Charge_Current : 0|12@1+ (0.05,0) [0|204.75] "A" Pack01BMSLeader
 SG_ Available_Discharge_Current : 12|12@1+ (0.05,0) [0|204.75] "A" Pack01BMSLeader
 SG_ Available_Pulse_Charge_Current : 24|12@1+ (0.05,0) [0|204.75] "A" Pack01BMSLeader
 SG_ Available_Pulse_Discharge_Curren : 36|12@1+ (0.05,0) [0|204.75] "A" Pack01BMSLeader

BO_ 2360854985 Feedback_7_Pack01BMSLeader: 8 Pack01BMSLeader
 SG_ Charge_Pulse_Counter : 0|10@1+ (0.05,0) [0|51.15] "s" Pack01BMSLeader
 SG_ Discharge_Pulse_Counter : 10|10@1+ (0.05,0) [0|51.15] "s" Pack01BMSLeader

BO_ 2360854986 Feedback_7_Pack02BMS: 8 Pack02BMS
 SG_ Charge_Pulse_Counter : 0|10@1+ (0.05,0) [0|51.15] "s" Pack01BMSLeader
 SG_ Discharge_Pulse_Counter : 10|10@1+ (0.05,0) [0|51.15] "s" Pack01BMSLeader

BO_ 2360854987 Feedback_7_Pack03BMS: 8 Pack03BMS
 SG_ Charge_Pulse_Counter : 0|10@1+ (0.05,0) [0|51.15] "s" Pack01BMSLeader
 SG_ Discharge_Pulse_Counter : 10|10@1+ (0.05,0) [0|51.15] "s" Pack01BMSLeader

BO_ 2360854988 Feedback_7_Pack04BMS: 8 Pack04BMS
 SG_ Charge_Pulse_Counter : 0|10@1+ (0.05,0) [0|51.15] "s" Pack01BMSLeader
 SG_ Discharge_Pulse_Counter : 10|10@1+ (0.05,0) [0|51.15] "s" Pack01BMSLeader

BO_ 2360854989 Feedback_7_Pack05BMS: 8 Pack05BMS
 SG_ Charge_Pulse_Counter : 0|10@1+ (0.05,0) [0|51.15] "s" Pack01BMSLeader
 SG_ Discharge_Pulse_Counter : 10|10@1+ (0.05,0) [0|51.15] "s" Pack01BMSLeader

BO_ 2360854990 Feedback_7_Pack06BMS: 8 Pack06BMS
 SG_ Charge_Pulse_Counter : 0|10@1+ (0.05,0) [0|51.15] "s" Pack01BMSLeader
 SG_ Discharge_Pulse_Counter : 10|10@1+ (0.05,0) [0|51.15] "s" Pack01BMSLeader

BO_ 2360854991 Feedback_7_Pack07BMS: 8 Pack07BMS
 SG_ Charge_Pulse_Counter : 0|10@1+ (0.05,0) [0|51.15] "s" Pack01BMSLeader
 SG_ Discharge_Pulse_Counter : 10|10@1+ (0.05,0) [0|51.15] "s" Pack01BMSLeader

BO_ 2360854992 Feedback_7_Pack08BMS: 8 Pack08BMS
 SG_ Charge_Pulse_Counter : 0|10@1+ (0.05,0) [0|51.15] "s" Pack01BMSLeader
 SG_ Discharge_Pulse_Counter : 10|10@1+ (0.05,0) [0|51.15] "s" Pack01BMSLeader

BO_ 2360854993 Feedback_7_Pack09BMS: 8 Pack09BMS
 SG_ Charge_Pulse_Counter : 0|10@1+ (0.05,0) [0|51.15] "s" Pack01BMSLeader
 SG_ Discharge_Pulse_Counter : 10|10@1+ (0.05,0) [0|51.15] "s" Pack01BMSLeader

BO_ 2360854994 Feedback_7_Pack10BMS: 8 Pack10BMS
 SG_ Charge_Pulse_Counter : 0|10@1+ (0.05,0) [0|51.15] "s" Pack01BMSLeader
 SG_ Discharge_Pulse_Counter : 10|10@1+ (0.05,0) [0|51.15] "s" Pack01BMSLeader

BO_ 2360854995 Feedback_7_Pack11BMS: 8 Pack11BMS
 SG_ Charge_Pulse_Counter : 0|10@1+ (0.05,0) [0|51.15] "s" Pack01BMSLeader
 SG_ Discharge_Pulse_Counter : 10|10@1+ (0.05,0) [0|51.15] "s" Pack01BMSLeader

BO_ 2360854996 Feedback_7_Pack12BMS: 8 Pack12BMS
 SG_ Charge_Pulse_Counter : 0|10@1+ (0.05,0) [0|51.15] "s" Pack01BMSLeader
 SG_ Discharge_Pulse_Counter : 10|10@1+ (0.05,0) [0|51.15] "s" Pack01BMSLeader

BO_ 2360854997 Feedback_7_Pack13BMS: 8 Pack13BMS
 SG_ Charge_Pulse_Counter : 0|10@1+ (0.05,0) [0|51.15] "s" Pack01BMSLeader
 SG_ Discharge_Pulse_Counter : 10|10@1+ (0.05,0) [0|51.15] "s" Pack01BMSLeader

BO_ 2360854998 Feedback_7_Pack14BMS: 8 Pack14BMS
 SG_ Charge_Pulse_Counter : 0|10@1+ (0.05,0) [0|51.15] "s" Pack01BMSLeader
 SG_ Discharge_Pulse_Counter : 10|10@1+ (0.05,0) [0|51.15] "s" Pack01BMSLeader

BO_ 2360854999 Feedback_7_Pack15BMS: 8 Pack15BMS
 SG_ Charge_Pulse_Counter : 0|10@1+ (0.05,0) [0|51.15] "s" Pack01BMSLeader
 SG_ Discharge_Pulse_Counter : 10|10@1+ (0.05,0) [0|51.15] "s" Pack01BMSLeader

BO_ 2360855000 Feedback_7_Pack16BMS: 8 Pack16BMS
 SG_ Charge_Pulse_Counter : 0|10@1+ (0.05,0) [0|51.15] "s" Pack01BMSLeader
 SG_ Discharge_Pulse_Counter : 10|10@1+ (0.05,0) [0|51.15] "s" Pack01BMSLeader

CM_ SG_ 2364525001 Connect_Command "Command from LBMS to connect battery pack";
CM_ SG_ 2364525001 Disable_Command "Command from LBMS to disable battery pack";
CM_ SG_ 2364525257 Connect_Command "Command from LBMS to connect battery pack";
CM_ SG_ 2364525257 Disable_Command "Command from LBMS to disable battery pack";
CM_ SG_ 2364525513 Connect_Command "Command from LBMS to connect battery pack";
CM_ SG_ 2364525513 Disable_Command "Command from LBMS to disable battery pack";
CM_ SG_ 2364525769 Connect_Command "Command from LBMS to connect battery pack";
CM_ SG_ 2364525769 Disable_Command "Command from LBMS to disable battery pack";
CM_ SG_ 2364526025 Connect_Command "Command from LBMS to connect battery pack";
CM_ SG_ 2364526025 Disable_Command "Command from LBMS to disable battery pack";
CM_ SG_ 2364526281 Connect_Command "Command from LBMS to connect battery pack";
CM_ SG_ 2364526281 Disable_Command "Command from LBMS to disable battery pack";
CM_ SG_ 2364526537 Connect_Command "Command from LBMS to connect battery pack";
CM_ SG_ 2364526537 Disable_Command "Command from LBMS to disable battery pack";
CM_ SG_ 2364526793 Connect_Command "Command from LBMS to connect battery pack";
CM_ SG_ 2364526793 Disable_Command "Command from LBMS to disable battery pack";
CM_ SG_ 2364527049 Connect_Command "Command from LBMS to connect battery pack";
CM_ SG_ 2364527049 Disable_Command "Command from LBMS to disable battery pack";
CM_ SG_ 2364527305 Connect_Command "Command from LBMS to connect battery pack";
CM_ SG_ 2364527305 Disable_Command "Command from LBMS to disable battery pack";
CM_ SG_ 2364527561 Connect_Command "Command from LBMS to connect battery pack";
CM_ SG_ 2364527561 Disable_Command "Command from LBMS to disable battery pack";
CM_ SG_ 2364527817 Connect_Command "Command from LBMS to connect battery pack";
CM_ SG_ 2364527817 Disable_Command "Command from LBMS to disable battery pack";
CM_ SG_ 2364528073 Connect_Command "Command from LBMS to connect battery pack";
CM_ SG_ 2364528073 Disable_Command "Command from LBMS to disable battery pack";
CM_ SG_ 2364528329 Connect_Command "Command from LBMS to connect battery pack";
CM_ SG_ 2364528329 Disable_Command "Command from LBMS to disable battery pack";
CM_ SG_ 2364528585 Connect_Command "Command from LBMS to connect battery pack";
CM_ SG_ 2364528585 Disable_Command "Command from LBMS to disable battery pack";
CM_ SG_ 2364528841 Connect_Command "Command from LBMS to connect battery pack";
CM_ SG_ 2364528841 Disable_Command "Command from LBMS to disable battery pack";
CM_ SG_ 2365587401 System_Current "System current";
CM_ SG_ 2365587401 System_Average_Current_Connected "System average current of connected packs";
CM_ SG_ 2365587401 System_HVDC_Bus_Voltage "System HVDC bus voltage";
CM_ SG_ 2365587401 System_Charging_Mode "Communication of intent to charge from LBMS";
CM_ SG_ 2365587145 System_Unix_Time "System unix time";
CM_ SG_ 2365587145 System_Clear_DMs_Command "Command from LBMS to clear DMs";
CM_ SG_ 2360461769 Battery_Voltage "Battery pack voltage";
CM_ SG_ 2360461769 HVDC_Bus_Voltage "HVDC bus voltage";
CM_ SG_ 2360461769 Current "Battery pack current";
CM_ SG_ 2360461769 Operational_Status "Battery pack operational status";
CM_ SG_ 2360461769 HVDC_Bus_Disconnect_Forewarning "Indicates the battery pack is about to disconnect from the HVDC bus due to validated fault condition";
CM_ SG_ 2360461769 HVDC_Bus_Connection_Status "Battery pack connection status to the HVDC bus";
CM_ SG_ 2360461769 Pre_Charge_Ready "Indication battery pack is ready to pre-charge";
CM_ SG_ 2360461770 Battery_Voltage "Battery pack voltage";
CM_ SG_ 2360461770 HVDC_Bus_Voltage "HVDC bus voltage";
CM_ SG_ 2360461770 Current "Battery pack current";
CM_ SG_ 2360461770 Operational_Status "Battery pack operational status";
CM_ SG_ 2360461770 HVDC_Bus_Disconnect_Forewarning "Indicates the battery pack is about to disconnect from the HVDC bus due to validated fault condition";
CM_ SG_ 2360461770 HVDC_Bus_Connection_Status "Battery pack connection status to the HVDC bus";
CM_ SG_ 2360461770 Pre_Charge_Ready "Indication battery pack is ready to pre-charge";
CM_ SG_ 2360461771 Battery_Voltage "Battery pack voltage";
CM_ SG_ 2360461771 HVDC_Bus_Voltage "HVDC bus voltage";
CM_ SG_ 2360461771 Current "Battery pack current";
CM_ SG_ 2360461771 Operational_Status "Battery pack operational status";
CM_ SG_ 2360461771 HVDC_Bus_Disconnect_Forewarning "Indicates the battery pack is about to disconnect from the HVDC bus due to validated fault condition";
CM_ SG_ 2360461771 HVDC_Bus_Connection_Status "Battery pack connection status to the HVDC bus";
CM_ SG_ 2360461771 Pre_Charge_Ready "Indication battery pack is ready to pre-charge";
CM_ SG_ 2360461772 Battery_Voltage "Battery pack voltage";
CM_ SG_ 2360461772 HVDC_Bus_Voltage "HVDC bus voltage";
CM_ SG_ 2360461772 Current "Battery pack current";
CM_ SG_ 2360461772 Operational_Status "Battery pack operational status";
CM_ SG_ 2360461772 HVDC_Bus_Disconnect_Forewarning "Indicates the battery pack is about to disconnect from the HVDC bus due to validated fault condition";
CM_ SG_ 2360461772 HVDC_Bus_Connection_Status "Battery pack connection status to the HVDC bus";
CM_ SG_ 2360461772 Pre_Charge_Ready "Indication battery pack is ready to pre-charge";
CM_ SG_ 2360461773 Battery_Voltage "Battery pack voltage";
CM_ SG_ 2360461773 HVDC_Bus_Voltage "HVDC bus voltage";
CM_ SG_ 2360461773 Current "Battery pack current";
CM_ SG_ 2360461773 Operational_Status "Battery pack operational status";
CM_ SG_ 2360461773 HVDC_Bus_Disconnect_Forewarning "Indicates the battery pack is about to disconnect from the HVDC bus due to validated fault condition";
CM_ SG_ 2360461773 HVDC_Bus_Connection_Status "Battery pack connection status to the HVDC bus";
CM_ SG_ 2360461773 Pre_Charge_Ready "Indication battery pack is ready to pre-charge";
CM_ SG_ 2360461774 Battery_Voltage "Battery pack voltage";
CM_ SG_ 2360461774 HVDC_Bus_Voltage "HVDC bus voltage";
CM_ SG_ 2360461774 Current "Battery pack current";
CM_ SG_ 2360461774 Operational_Status "Battery pack operational status";
CM_ SG_ 2360461774 HVDC_Bus_Disconnect_Forewarning "Indicates the battery pack is about to disconnect from the HVDC bus due to validated fault condition";
CM_ SG_ 2360461774 HVDC_Bus_Connection_Status "Battery pack connection status to the HVDC bus";
CM_ SG_ 2360461774 Pre_Charge_Ready "Indication battery pack is ready to pre-charge";
CM_ SG_ 2360461775 Battery_Voltage "Battery pack voltage";
CM_ SG_ 2360461775 HVDC_Bus_Voltage "HVDC bus voltage";
CM_ SG_ 2360461775 Current "Battery pack current";
CM_ SG_ 2360461775 Operational_Status "Battery pack operational status";
CM_ SG_ 2360461775 HVDC_Bus_Disconnect_Forewarning "Indicates the battery pack is about to disconnect from the HVDC bus due to validated fault condition";
CM_ SG_ 2360461775 HVDC_Bus_Connection_Status "Battery pack connection status to the HVDC bus";
CM_ SG_ 2360461775 Pre_Charge_Ready "Indication battery pack is ready to pre-charge";
CM_ SG_ 2360461776 Battery_Voltage "Battery pack voltage";
CM_ SG_ 2360461776 HVDC_Bus_Voltage "HVDC bus voltage";
CM_ SG_ 2360461776 Current "Battery pack current";
CM_ SG_ 2360461776 Operational_Status "Battery pack operational status";
CM_ SG_ 2360461776 HVDC_Bus_Disconnect_Forewarning "Indicates the battery pack is about to disconnect from the HVDC bus due to validated fault condition";
CM_ SG_ 2360461776 HVDC_Bus_Connection_Status "Battery pack connection status to the HVDC bus";
CM_ SG_ 2360461776 Pre_Charge_Ready "Indication battery pack is ready to pre-charge";
CM_ SG_ 2360461777 Battery_Voltage "Battery pack voltage";
CM_ SG_ 2360461777 HVDC_Bus_Voltage "HVDC bus voltage";
CM_ SG_ 2360461777 Current "Battery pack current";
CM_ SG_ 2360461777 Operational_Status "Battery pack operational status";
CM_ SG_ 2360461777 HVDC_Bus_Disconnect_Forewarning "Indicates the battery pack is about to disconnect from the HVDC bus due to validated fault condition";
CM_ SG_ 2360461777 HVDC_Bus_Connection_Status "Battery pack connection status to the HVDC bus";
CM_ SG_ 2360461777 Pre_Charge_Ready "Indication battery pack is ready to pre-charge";
CM_ SG_ 2360461778 Battery_Voltage "Battery pack voltage";
CM_ SG_ 2360461778 HVDC_Bus_Voltage "HVDC bus voltage";
CM_ SG_ 2360461778 Current "Battery pack current";
CM_ SG_ 2360461778 Operational_Status "Battery pack operational status";
CM_ SG_ 2360461778 HVDC_Bus_Disconnect_Forewarning "Indicates the battery pack is about to disconnect from the HVDC bus due to validated fault condition";
CM_ SG_ 2360461778 HVDC_Bus_Connection_Status "Battery pack connection status to the HVDC bus";
CM_ SG_ 2360461778 Pre_Charge_Ready "Indication battery pack is ready to pre-charge";
CM_ SG_ 2360461779 Battery_Voltage "Battery pack voltage";
CM_ SG_ 2360461779 HVDC_Bus_Voltage "HVDC bus voltage";
CM_ SG_ 2360461779 Current "Battery pack current";
CM_ SG_ 2360461779 Operational_Status "Battery pack operational status";
CM_ SG_ 2360461779 HVDC_Bus_Disconnect_Forewarning "Indicates the battery pack is about to disconnect from the HVDC bus due to validated fault condition";
CM_ SG_ 2360461779 HVDC_Bus_Connection_Status "Battery pack connection status to the HVDC bus";
CM_ SG_ 2360461779 Pre_Charge_Ready "Indication battery pack is ready to pre-charge";
CM_ SG_ 2360461780 Battery_Voltage "Battery pack voltage";
CM_ SG_ 2360461780 HVDC_Bus_Voltage "HVDC bus voltage";
CM_ SG_ 2360461780 Current "Battery pack current";
CM_ SG_ 2360461780 Operational_Status "Battery pack operational status";
CM_ SG_ 2360461780 HVDC_Bus_Disconnect_Forewarning "Indicates the battery pack is about to disconnect from the HVDC bus due to validated fault condition";
CM_ SG_ 2360461780 HVDC_Bus_Connection_Status "Battery pack connection status to the HVDC bus";
CM_ SG_ 2360461780 Pre_Charge_Ready "Indication battery pack is ready to pre-charge";
CM_ SG_ 2360461781 Battery_Voltage "Battery pack voltage";
CM_ SG_ 2360461781 HVDC_Bus_Voltage "HVDC bus voltage";
CM_ SG_ 2360461781 Current "Battery pack current";
CM_ SG_ 2360461781 Operational_Status "Battery pack operational status";
CM_ SG_ 2360461781 HVDC_Bus_Disconnect_Forewarning "Indicates the battery pack is about to disconnect from the HVDC bus due to validated fault condition";
CM_ SG_ 2360461781 HVDC_Bus_Connection_Status "Battery pack connection status to the HVDC bus";
CM_ SG_ 2360461781 Pre_Charge_Ready "Indication battery pack is ready to pre-charge";
CM_ SG_ 2360461782 Battery_Voltage "Battery pack voltage";
CM_ SG_ 2360461782 HVDC_Bus_Voltage "HVDC bus voltage";
CM_ SG_ 2360461782 Current "Battery pack current";
CM_ SG_ 2360461782 Operational_Status "Battery pack operational status";
CM_ SG_ 2360461782 HVDC_Bus_Disconnect_Forewarning "Indicates the battery pack is about to disconnect from the HVDC bus due to validated fault condition";
CM_ SG_ 2360461782 HVDC_Bus_Connection_Status "Battery pack connection status to the HVDC bus";
CM_ SG_ 2360461782 Pre_Charge_Ready "Indication battery pack is ready to pre-charge";
CM_ SG_ 2360461783 Battery_Voltage "Battery pack voltage";
CM_ SG_ 2360461783 HVDC_Bus_Voltage "HVDC bus voltage";
CM_ SG_ 2360461783 Current "Battery pack current";
CM_ SG_ 2360461783 Operational_Status "Battery pack operational status";
CM_ SG_ 2360461783 HVDC_Bus_Disconnect_Forewarning "Indicates the battery pack is about to disconnect from the HVDC bus due to validated fault condition";
CM_ SG_ 2360461783 HVDC_Bus_Connection_Status "Battery pack connection status to the HVDC bus";
CM_ SG_ 2360461783 Pre_Charge_Ready "Indication battery pack is ready to pre-charge";
CM_ SG_ 2360461784 Battery_Voltage "Battery pack voltage";
CM_ SG_ 2360461784 HVDC_Bus_Voltage "HVDC bus voltage";
CM_ SG_ 2360461784 Current "Battery pack current";
CM_ SG_ 2360461784 Operational_Status "Battery pack operational status";
CM_ SG_ 2360461784 HVDC_Bus_Disconnect_Forewarning "Indicates the battery pack is about to disconnect from the HVDC bus due to validated fault condition";
CM_ SG_ 2360461784 HVDC_Bus_Connection_Status "Battery pack connection status to the HVDC bus";
CM_ SG_ 2360461784 Pre_Charge_Ready "Indication battery pack is ready to pre-charge";
CM_ SG_ 2360527305 Available_Charge_Power "Battery pack available charge power";
CM_ SG_ 2360527305 Available_Discharge_Power "Battery pack available discharge power";
CM_ SG_ 2360527305 Available_High_Charge_Power "Battery pack available high charge power";
CM_ SG_ 2360527305 Available_High_Discharge_Power "Battery pack available high discharge power";
CM_ SG_ 2360527305 Instantaneous_Power "Battery pack instantaneous power";
CM_ SG_ 2360527306 Available_Charge_Power "Battery pack available charge power";
CM_ SG_ 2360527306 Available_Discharge_Power "Battery pack available discharge power";
CM_ SG_ 2360527306 Available_High_Charge_Power "Battery pack available high charge power";
CM_ SG_ 2360527306 Available_High_Discharge_Power "Battery pack available high discharge power";
CM_ SG_ 2360527306 Instantaneous_Power "Battery pack instantaneous power";
CM_ SG_ 2360527307 Available_Charge_Power "Battery pack available charge power";
CM_ SG_ 2360527307 Available_Discharge_Power "Battery pack available discharge power";
CM_ SG_ 2360527307 Available_High_Charge_Power "Battery pack available high charge power";
CM_ SG_ 2360527307 Available_High_Discharge_Power "Battery pack available high discharge power";
CM_ SG_ 2360527307 Instantaneous_Power "Battery pack instantaneous power";
CM_ SG_ 2360527308 Available_Charge_Power "Battery pack available charge power";
CM_ SG_ 2360527308 Available_Discharge_Power "Battery pack available discharge power";
CM_ SG_ 2360527308 Available_High_Charge_Power "Battery pack available high charge power";
CM_ SG_ 2360527308 Available_High_Discharge_Power "Battery pack available high discharge power";
CM_ SG_ 2360527308 Instantaneous_Power "Battery pack instantaneous power";
CM_ SG_ 2360527309 Available_Charge_Power "Battery pack available charge power";
CM_ SG_ 2360527309 Available_Discharge_Power "Battery pack available discharge power";
CM_ SG_ 2360527309 Available_High_Charge_Power "Battery pack available high charge power";
CM_ SG_ 2360527309 Available_High_Discharge_Power "Battery pack available high discharge power";
CM_ SG_ 2360527309 Instantaneous_Power "Battery pack instantaneous power";
CM_ SG_ 2360527310 Available_Charge_Power "Battery pack available charge power";
CM_ SG_ 2360527310 Available_Discharge_Power "Battery pack available discharge power";
CM_ SG_ 2360527310 Available_High_Charge_Power "Battery pack available high charge power";
CM_ SG_ 2360527310 Available_High_Discharge_Power "Battery pack available high discharge power";
CM_ SG_ 2360527310 Instantaneous_Power "Battery pack instantaneous power";
CM_ SG_ 2360527311 Available_Charge_Power "Battery pack available charge power";
CM_ SG_ 2360527311 Available_Discharge_Power "Battery pack available discharge power";
CM_ SG_ 2360527311 Available_High_Charge_Power "Battery pack available high charge power";
CM_ SG_ 2360527311 Available_High_Discharge_Power "Battery pack available high discharge power";
CM_ SG_ 2360527311 Instantaneous_Power "Battery pack instantaneous power";
CM_ SG_ 2360527312 Available_Charge_Power "Battery pack available charge power";
CM_ SG_ 2360527312 Available_Discharge_Power "Battery pack available discharge power";
CM_ SG_ 2360527312 Available_High_Charge_Power "Battery pack available high charge power";
CM_ SG_ 2360527312 Available_High_Discharge_Power "Battery pack available high discharge power";
CM_ SG_ 2360527312 Instantaneous_Power "Battery pack instantaneous power";
CM_ SG_ 2360527313 Available_Charge_Power "Battery pack available charge power";
CM_ SG_ 2360527313 Available_Discharge_Power "Battery pack available discharge power";
CM_ SG_ 2360527313 Available_High_Charge_Power "Battery pack available high charge power";
CM_ SG_ 2360527313 Available_High_Discharge_Power "Battery pack available high discharge power";
CM_ SG_ 2360527313 Instantaneous_Power "Battery pack instantaneous power";
CM_ SG_ 2360527314 Available_Charge_Power "Battery pack available charge power";
CM_ SG_ 2360527314 Available_Discharge_Power "Battery pack available discharge power";
CM_ SG_ 2360527314 Available_High_Charge_Power "Battery pack available high charge power";
CM_ SG_ 2360527314 Available_High_Discharge_Power "Battery pack available high discharge power";
CM_ SG_ 2360527314 Instantaneous_Power "Battery pack instantaneous power";
CM_ SG_ 2360527315 Available_Charge_Power "Battery pack available charge power";
CM_ SG_ 2360527315 Available_Discharge_Power "Battery pack available discharge power";
CM_ SG_ 2360527315 Available_High_Charge_Power "Battery pack available high charge power";
CM_ SG_ 2360527315 Available_High_Discharge_Power "Battery pack available high discharge power";
CM_ SG_ 2360527315 Instantaneous_Power "Battery pack instantaneous power";
CM_ SG_ 2360527316 Available_Charge_Power "Battery pack available charge power";
CM_ SG_ 2360527316 Available_Discharge_Power "Battery pack available discharge power";
CM_ SG_ 2360527316 Available_High_Charge_Power "Battery pack available high charge power";
CM_ SG_ 2360527316 Available_High_Discharge_Power "Battery pack available high discharge power";
CM_ SG_ 2360527316 Instantaneous_Power "Battery pack instantaneous power";
CM_ SG_ 2360527317 Available_Charge_Power "Battery pack available charge power";
CM_ SG_ 2360527317 Available_Discharge_Power "Battery pack available discharge power";
CM_ SG_ 2360527317 Available_High_Charge_Power "Battery pack available high charge power";
CM_ SG_ 2360527317 Available_High_Discharge_Power "Battery pack available high discharge power";
CM_ SG_ 2360527317 Instantaneous_Power "Battery pack instantaneous power";
CM_ SG_ 2360527318 Available_Charge_Power "Battery pack available charge power";
CM_ SG_ 2360527318 Available_Discharge_Power "Battery pack available discharge power";
CM_ SG_ 2360527318 Available_High_Charge_Power "Battery pack available high charge power";
CM_ SG_ 2360527318 Available_High_Discharge_Power "Battery pack available high discharge power";
CM_ SG_ 2360527318 Instantaneous_Power "Battery pack instantaneous power";
CM_ SG_ 2360527319 Available_Charge_Power "Battery pack available charge power";
CM_ SG_ 2360527319 Available_Discharge_Power "Battery pack available discharge power";
CM_ SG_ 2360527319 Available_High_Charge_Power "Battery pack available high charge power";
CM_ SG_ 2360527319 Available_High_Discharge_Power "Battery pack available high discharge power";
CM_ SG_ 2360527319 Instantaneous_Power "Battery pack instantaneous power";
CM_ SG_ 2360527320 Available_Charge_Power "Battery pack available charge power";
CM_ SG_ 2360527320 Available_Discharge_Power "Battery pack available discharge power";
CM_ SG_ 2360527320 Available_High_Charge_Power "Battery pack available high charge power";
CM_ SG_ 2360527320 Available_High_Discharge_Power "Battery pack available high discharge power";
CM_ SG_ 2360527320 Instantaneous_Power "Battery pack instantaneous power";
CM_ SG_ 2360592841 Lowest_Cell_Voltage "Lowest cell voltage";
CM_ SG_ 2360592841 Highest_Cell_Voltage "Highest cell voltage";
CM_ SG_ 2360592841 Lowest_Cell_Temperature "Battery pack lowest cell temperature";
CM_ SG_ 2360592841 Highest_Cell_Temperature "Battery pack highest cell temperature";
CM_ SG_ 2360592841 Battery_Isolation "Battery pack isolation measurement";
CM_ SG_ 2360592842 Lowest_Cell_Voltage "Lowest cell voltage";
CM_ SG_ 2360592842 Highest_Cell_Voltage "Highest cell voltage";
CM_ SG_ 2360592842 Lowest_Cell_Temperature "Battery pack lowest cell temperature";
CM_ SG_ 2360592842 Highest_Cell_Temperature "Battery pack highest cell temperature";
CM_ SG_ 2360592842 Battery_Isolation "Battery pack isolation measurement";
CM_ SG_ 2360592843 Lowest_Cell_Voltage "Lowest cell voltage";
CM_ SG_ 2360592843 Highest_Cell_Voltage "Highest cell voltage";
CM_ SG_ 2360592843 Lowest_Cell_Temperature "Battery pack lowest cell temperature";
CM_ SG_ 2360592843 Highest_Cell_Temperature "Battery pack highest cell temperature";
CM_ SG_ 2360592843 Battery_Isolation "Battery pack isolation measurement";
CM_ SG_ 2360592844 Lowest_Cell_Voltage "Lowest cell voltage";
CM_ SG_ 2360592844 Highest_Cell_Voltage "Highest cell voltage";
CM_ SG_ 2360592844 Lowest_Cell_Temperature "Battery pack lowest cell temperature";
CM_ SG_ 2360592844 Highest_Cell_Temperature "Battery pack highest cell temperature";
CM_ SG_ 2360592844 Battery_Isolation "Battery pack isolation measurement";
CM_ SG_ 2360592845 Lowest_Cell_Voltage "Lowest cell voltage";
CM_ SG_ 2360592845 Highest_Cell_Voltage "Highest cell voltage";
CM_ SG_ 2360592845 Lowest_Cell_Temperature "Battery pack lowest cell temperature";
CM_ SG_ 2360592845 Highest_Cell_Temperature "Battery pack highest cell temperature";
CM_ SG_ 2360592845 Battery_Isolation "Battery pack isolation measurement";
CM_ SG_ 2360592846 Lowest_Cell_Voltage "Lowest cell voltage";
CM_ SG_ 2360592846 Highest_Cell_Voltage "Highest cell voltage";
CM_ SG_ 2360592846 Lowest_Cell_Temperature "Battery pack lowest cell temperature";
CM_ SG_ 2360592846 Highest_Cell_Temperature "Battery pack highest cell temperature";
CM_ SG_ 2360592846 Battery_Isolation "Battery pack isolation measurement";
CM_ SG_ 2360592847 Lowest_Cell_Voltage "Lowest cell voltage";
CM_ SG_ 2360592847 Highest_Cell_Voltage "Highest cell voltage";
CM_ SG_ 2360592847 Lowest_Cell_Temperature "Battery pack lowest cell temperature";
CM_ SG_ 2360592847 Highest_Cell_Temperature "Battery pack highest cell temperature";
CM_ SG_ 2360592847 Battery_Isolation "Battery pack isolation measurement";
CM_ SG_ 2360592848 Lowest_Cell_Voltage "Lowest cell voltage";
CM_ SG_ 2360592848 Highest_Cell_Voltage "Highest cell voltage";
CM_ SG_ 2360592848 Lowest_Cell_Temperature "Battery pack lowest cell temperature";
CM_ SG_ 2360592848 Highest_Cell_Temperature "Battery pack highest cell temperature";
CM_ SG_ 2360592848 Battery_Isolation "Battery pack isolation measurement";
CM_ SG_ 2360592849 Lowest_Cell_Voltage "Lowest cell voltage";
CM_ SG_ 2360592849 Highest_Cell_Voltage "Highest cell voltage";
CM_ SG_ 2360592849 Lowest_Cell_Temperature "Battery pack lowest cell temperature";
CM_ SG_ 2360592849 Highest_Cell_Temperature "Battery pack highest cell temperature";
CM_ SG_ 2360592849 Battery_Isolation "Battery pack isolation measurement";
CM_ SG_ 2360592850 Lowest_Cell_Voltage "Lowest cell voltage";
CM_ SG_ 2360592850 Highest_Cell_Voltage "Highest cell voltage";
CM_ SG_ 2360592850 Lowest_Cell_Temperature "Battery pack lowest cell temperature";
CM_ SG_ 2360592850 Highest_Cell_Temperature "Battery pack highest cell temperature";
CM_ SG_ 2360592850 Battery_Isolation "Battery pack isolation measurement";
CM_ SG_ 2360592851 Lowest_Cell_Voltage "Lowest cell voltage";
CM_ SG_ 2360592851 Highest_Cell_Voltage "Highest cell voltage";
CM_ SG_ 2360592851 Lowest_Cell_Temperature "Battery pack lowest cell temperature";
CM_ SG_ 2360592851 Highest_Cell_Temperature "Battery pack highest cell temperature";
CM_ SG_ 2360592851 Battery_Isolation "Battery pack isolation measurement";
CM_ SG_ 2360592852 Lowest_Cell_Voltage "Lowest cell voltage";
CM_ SG_ 2360592852 Highest_Cell_Voltage "Highest cell voltage";
CM_ SG_ 2360592852 Lowest_Cell_Temperature "Battery pack lowest cell temperature";
CM_ SG_ 2360592852 Highest_Cell_Temperature "Battery pack highest cell temperature";
CM_ SG_ 2360592852 Battery_Isolation "Battery pack isolation measurement";
CM_ SG_ 2360592853 Lowest_Cell_Voltage "Lowest cell voltage";
CM_ SG_ 2360592853 Highest_Cell_Voltage "Highest cell voltage";
CM_ SG_ 2360592853 Lowest_Cell_Temperature "Battery pack lowest cell temperature";
CM_ SG_ 2360592853 Highest_Cell_Temperature "Battery pack highest cell temperature";
CM_ SG_ 2360592853 Battery_Isolation "Battery pack isolation measurement";
CM_ SG_ 2360592854 Lowest_Cell_Voltage "Lowest cell voltage";
CM_ SG_ 2360592854 Highest_Cell_Voltage "Highest cell voltage";
CM_ SG_ 2360592854 Lowest_Cell_Temperature "Battery pack lowest cell temperature";
CM_ SG_ 2360592854 Highest_Cell_Temperature "Battery pack highest cell temperature";
CM_ SG_ 2360592854 Battery_Isolation "Battery pack isolation measurement";
CM_ SG_ 2360592855 Lowest_Cell_Voltage "Lowest cell voltage";
CM_ SG_ 2360592855 Highest_Cell_Voltage "Highest cell voltage";
CM_ SG_ 2360592855 Lowest_Cell_Temperature "Battery pack lowest cell temperature";
CM_ SG_ 2360592855 Highest_Cell_Temperature "Battery pack highest cell temperature";
CM_ SG_ 2360592855 Battery_Isolation "Battery pack isolation measurement";
CM_ SG_ 2360592856 Lowest_Cell_Voltage "Lowest cell voltage";
CM_ SG_ 2360592856 Highest_Cell_Voltage "Highest cell voltage";
CM_ SG_ 2360592856 Lowest_Cell_Temperature "Battery pack lowest cell temperature";
CM_ SG_ 2360592856 Highest_Cell_Temperature "Battery pack highest cell temperature";
CM_ SG_ 2360592856 Battery_Isolation "Battery pack isolation measurement";
CM_ SG_ 2360658377 Lowest_Cell_State_of_Charge "Battery pack lowest cell state of charge";
CM_ SG_ 2360658377 Highest_Cell_State_of_Charge "Battery pack highest cell state of charge";
CM_ SG_ 2360658377 Charge_Capacity "Ah available to be filled while applying available charge power";
CM_ SG_ 2360658377 Discharge_Capacity "Ah available to be used while applying available discharge power";
CM_ SG_ 2360658377 Estimated_Charge_Time_Remaining "Battery pack estimated charge time remaining";
CM_ SG_ 2360658378 Lowest_Cell_State_of_Charge "Battery pack lowest cell state of charge";
CM_ SG_ 2360658378 Highest_Cell_State_of_Charge "Battery pack highest cell state of charge";
CM_ SG_ 2360658378 Charge_Capacity "Ah available to be filled while applying available charge power";
CM_ SG_ 2360658378 Discharge_Capacity "Ah available to be used while applying available discharge power";
CM_ SG_ 2360658378 Estimated_Charge_Time_Remaining "Battery pack estimated charge time remaining";
CM_ SG_ 2360658379 Lowest_Cell_State_of_Charge "Battery pack lowest cell state of charge";
CM_ SG_ 2360658379 Highest_Cell_State_of_Charge "Battery pack highest cell state of charge";
CM_ SG_ 2360658379 Charge_Capacity "Ah available to be filled while applying available charge power";
CM_ SG_ 2360658379 Discharge_Capacity "Ah available to be used while applying available discharge power";
CM_ SG_ 2360658379 Estimated_Charge_Time_Remaining "Battery pack estimated charge time remaining";
CM_ SG_ 2360658380 Lowest_Cell_State_of_Charge "Battery pack lowest cell state of charge";
CM_ SG_ 2360658380 Highest_Cell_State_of_Charge "Battery pack highest cell state of charge";
CM_ SG_ 2360658380 Charge_Capacity "Ah available to be filled while applying available charge power";
CM_ SG_ 2360658380 Discharge_Capacity "Ah available to be used while applying available discharge power";
CM_ SG_ 2360658380 Estimated_Charge_Time_Remaining "Battery pack estimated charge time remaining";
CM_ SG_ 2360658381 Lowest_Cell_State_of_Charge "Battery pack lowest cell state of charge";
CM_ SG_ 2360658381 Highest_Cell_State_of_Charge "Battery pack highest cell state of charge";
CM_ SG_ 2360658381 Charge_Capacity "Ah available to be filled while applying available charge power";
CM_ SG_ 2360658381 Discharge_Capacity "Ah available to be used while applying available discharge power";
CM_ SG_ 2360658381 Estimated_Charge_Time_Remaining "Battery pack estimated charge time remaining";
CM_ SG_ 2360658382 Lowest_Cell_State_of_Charge "Battery pack lowest cell state of charge";
CM_ SG_ 2360658382 Highest_Cell_State_of_Charge "Battery pack highest cell state of charge";
CM_ SG_ 2360658382 Charge_Capacity "Ah available to be filled while applying available charge power";
CM_ SG_ 2360658382 Discharge_Capacity "Ah available to be used while applying available discharge power";
CM_ SG_ 2360658382 Estimated_Charge_Time_Remaining "Battery pack estimated charge time remaining";
CM_ SG_ 2360658383 Lowest_Cell_State_of_Charge "Battery pack lowest cell state of charge";
CM_ SG_ 2360658383 Highest_Cell_State_of_Charge "Battery pack highest cell state of charge";
CM_ SG_ 2360658383 Charge_Capacity "Ah available to be filled while applying available charge power";
CM_ SG_ 2360658383 Discharge_Capacity "Ah available to be used while applying available discharge power";
CM_ SG_ 2360658383 Estimated_Charge_Time_Remaining "Battery pack estimated charge time remaining";
CM_ SG_ 2360658384 Lowest_Cell_State_of_Charge "Battery pack lowest cell state of charge";
CM_ SG_ 2360658384 Highest_Cell_State_of_Charge "Battery pack highest cell state of charge";
CM_ SG_ 2360658384 Charge_Capacity "Ah available to be filled while applying available charge power";
CM_ SG_ 2360658384 Discharge_Capacity "Ah available to be used while applying available discharge power";
CM_ SG_ 2360658384 Estimated_Charge_Time_Remaining "Battery pack estimated charge time remaining";
CM_ SG_ 2360658385 Lowest_Cell_State_of_Charge "Battery pack lowest cell state of charge";
CM_ SG_ 2360658385 Highest_Cell_State_of_Charge "Battery pack highest cell state of charge";
CM_ SG_ 2360658385 Charge_Capacity "Ah available to be filled while applying available charge power";
CM_ SG_ 2360658385 Discharge_Capacity "Ah available to be used while applying available discharge power";
CM_ SG_ 2360658385 Estimated_Charge_Time_Remaining "Battery pack estimated charge time remaining";
CM_ SG_ 2360658386 Lowest_Cell_State_of_Charge "Battery pack lowest cell state of charge";
CM_ SG_ 2360658386 Highest_Cell_State_of_Charge "Battery pack highest cell state of charge";
CM_ SG_ 2360658386 Charge_Capacity "Ah available to be filled while applying available charge power";
CM_ SG_ 2360658386 Discharge_Capacity "Ah available to be used while applying available discharge power";
CM_ SG_ 2360658386 Estimated_Charge_Time_Remaining "Battery pack estimated charge time remaining";
CM_ SG_ 2360658387 Lowest_Cell_State_of_Charge "Battery pack lowest cell state of charge";
CM_ SG_ 2360658387 Highest_Cell_State_of_Charge "Battery pack highest cell state of charge";
CM_ SG_ 2360658387 Charge_Capacity "Ah available to be filled while applying available charge power";
CM_ SG_ 2360658387 Discharge_Capacity "Ah available to be used while applying available discharge power";
CM_ SG_ 2360658387 Estimated_Charge_Time_Remaining "Battery pack estimated charge time remaining";
CM_ SG_ 2360658388 Lowest_Cell_State_of_Charge "Battery pack lowest cell state of charge";
CM_ SG_ 2360658388 Highest_Cell_State_of_Charge "Battery pack highest cell state of charge";
CM_ SG_ 2360658388 Charge_Capacity "Ah available to be filled while applying available charge power";
CM_ SG_ 2360658388 Discharge_Capacity "Ah available to be used while applying available discharge power";
CM_ SG_ 2360658388 Estimated_Charge_Time_Remaining "Battery pack estimated charge time remaining";
CM_ SG_ 2360658389 Lowest_Cell_State_of_Charge "Battery pack lowest cell state of charge";
CM_ SG_ 2360658389 Highest_Cell_State_of_Charge "Battery pack highest cell state of charge";
CM_ SG_ 2360658389 Charge_Capacity "Ah available to be filled while applying available charge power";
CM_ SG_ 2360658389 Discharge_Capacity "Ah available to be used while applying available discharge power";
CM_ SG_ 2360658389 Estimated_Charge_Time_Remaining "Battery pack estimated charge time remaining";
CM_ SG_ 2360658390 Lowest_Cell_State_of_Charge "Battery pack lowest cell state of charge";
CM_ SG_ 2360658390 Highest_Cell_State_of_Charge "Battery pack highest cell state of charge";
CM_ SG_ 2360658390 Charge_Capacity "Ah available to be filled while applying available charge power";
CM_ SG_ 2360658390 Discharge_Capacity "Ah available to be used while applying available discharge power";
CM_ SG_ 2360658390 Estimated_Charge_Time_Remaining "Battery pack estimated charge time remaining";
CM_ SG_ 2360658391 Lowest_Cell_State_of_Charge "Battery pack lowest cell state of charge";
CM_ SG_ 2360658391 Highest_Cell_State_of_Charge "Battery pack highest cell state of charge";
CM_ SG_ 2360658391 Charge_Capacity "Ah available to be filled while applying available charge power";
CM_ SG_ 2360658391 Discharge_Capacity "Ah available to be used while applying available discharge power";
CM_ SG_ 2360658391 Estimated_Charge_Time_Remaining "Battery pack estimated charge time remaining";
CM_ SG_ 2360658392 Lowest_Cell_State_of_Charge "Battery pack lowest cell state of charge";
CM_ SG_ 2360658392 Highest_Cell_State_of_Charge "Battery pack highest cell state of charge";
CM_ SG_ 2360658392 Charge_Capacity "Ah available to be filled while applying available charge power";
CM_ SG_ 2360658392 Discharge_Capacity "Ah available to be used while applying available discharge power";
CM_ SG_ 2360658392 Estimated_Charge_Time_Remaining "Battery pack estimated charge time remaining";
CM_ SG_ 2360723913 Total_Lifetime_Energy_Input "Battery pack total lifetime energy input";
CM_ SG_ 2360723913 Total_Lifetime_Energy_Output "Battery pack total lifetime energy output";
CM_ SG_ 2360723914 Total_Lifetime_Energy_Input "Battery pack total lifetime energy input";
CM_ SG_ 2360723914 Total_Lifetime_Energy_Output "Battery pack total lifetime energy output";
CM_ SG_ 2360723915 Total_Lifetime_Energy_Input "Battery pack total lifetime energy input";
CM_ SG_ 2360723915 Total_Lifetime_Energy_Output "Battery pack total lifetime energy output";
CM_ SG_ 2360723916 Total_Lifetime_Energy_Input "Battery pack total lifetime energy input";
CM_ SG_ 2360723916 Total_Lifetime_Energy_Output "Battery pack total lifetime energy output";
CM_ SG_ 2360723917 Total_Lifetime_Energy_Input "Battery pack total lifetime energy input";
CM_ SG_ 2360723917 Total_Lifetime_Energy_Output "Battery pack total lifetime energy output";
CM_ SG_ 2360723918 Total_Lifetime_Energy_Input "Battery pack total lifetime energy input";
CM_ SG_ 2360723918 Total_Lifetime_Energy_Output "Battery pack total lifetime energy output";
CM_ SG_ 2360723919 Total_Lifetime_Energy_Input "Battery pack total lifetime energy input";
CM_ SG_ 2360723919 Total_Lifetime_Energy_Output "Battery pack total lifetime energy output";
CM_ SG_ 2360723920 Total_Lifetime_Energy_Input "Battery pack total lifetime energy input";
CM_ SG_ 2360723920 Total_Lifetime_Energy_Output "Battery pack total lifetime energy output";
CM_ SG_ 2360723921 Total_Lifetime_Energy_Input "Battery pack total lifetime energy input";
CM_ SG_ 2360723921 Total_Lifetime_Energy_Output "Battery pack total lifetime energy output";
CM_ SG_ 2360723922 Total_Lifetime_Energy_Input "Battery pack total lifetime energy input";
CM_ SG_ 2360723922 Total_Lifetime_Energy_Output "Battery pack total lifetime energy output";
CM_ SG_ 2360723923 Total_Lifetime_Energy_Input "Battery pack total lifetime energy input";
CM_ SG_ 2360723923 Total_Lifetime_Energy_Output "Battery pack total lifetime energy output";
CM_ SG_ 2360723924 Total_Lifetime_Energy_Input "Battery pack total lifetime energy input";
CM_ SG_ 2360723924 Total_Lifetime_Energy_Output "Battery pack total lifetime energy output";
CM_ SG_ 2360723925 Total_Lifetime_Energy_Input "Battery pack total lifetime energy input";
CM_ SG_ 2360723925 Total_Lifetime_Energy_Output "Battery pack total lifetime energy output";
CM_ SG_ 2360723926 Total_Lifetime_Energy_Input "Battery pack total lifetime energy input";
CM_ SG_ 2360723926 Total_Lifetime_Energy_Output "Battery pack total lifetime energy output";
CM_ SG_ 2360723927 Total_Lifetime_Energy_Input "Battery pack total lifetime energy input";
CM_ SG_ 2360723927 Total_Lifetime_Energy_Output "Battery pack total lifetime energy output";
CM_ SG_ 2360723928 Total_Lifetime_Energy_Input "Battery pack total lifetime energy input";
CM_ SG_ 2360723928 Total_Lifetime_Energy_Output "Battery pack total lifetime energy output";
CM_ SG_ 2360789449 Available_Charge_Current "Battery pack available charge current";
CM_ SG_ 2360789449 Available_Discharge_Current "Battery pack available discharge current";
CM_ SG_ 2360789449 Available_Pulse_Charge_Current "Battery pack available pulse charge current";
CM_ SG_ 2360789449 Available_Pulse_Discharge_Curren "Battery pack available pulse discharge current";
CM_ SG_ 2360789450 Available_Charge_Current "Battery pack available charge current";
CM_ SG_ 2360789450 Available_Discharge_Current "Battery pack available discharge current";
CM_ SG_ 2360789450 Available_Pulse_Charge_Current "Battery pack available pulse charge current";
CM_ SG_ 2360789450 Available_Pulse_Discharge_Curren "Battery pack available pulse discharge current";
CM_ SG_ 2360789451 Available_Charge_Current "Battery pack available charge current";
CM_ SG_ 2360789451 Available_Discharge_Current "Battery pack available discharge current";
CM_ SG_ 2360789451 Available_Pulse_Charge_Current "Battery pack available pulse charge current";
CM_ SG_ 2360789451 Available_Pulse_Discharge_Curren "Battery pack available pulse discharge current";
CM_ SG_ 2360789452 Available_Charge_Current "Battery pack available charge current";
CM_ SG_ 2360789452 Available_Discharge_Current "Battery pack available discharge current";
CM_ SG_ 2360789452 Available_Pulse_Charge_Current "Battery pack available pulse charge current";
CM_ SG_ 2360789452 Available_Pulse_Discharge_Curren "Battery pack available pulse discharge current";
CM_ SG_ 2360789453 Available_Charge_Current "Battery pack available charge current";
CM_ SG_ 2360789453 Available_Discharge_Current "Battery pack available discharge current";
CM_ SG_ 2360789453 Available_Pulse_Charge_Current "Battery pack available pulse charge current";
CM_ SG_ 2360789453 Available_Pulse_Discharge_Curren "Battery pack available pulse discharge current";
CM_ SG_ 2360789454 Available_Charge_Current "Battery pack available charge current";
CM_ SG_ 2360789454 Available_Discharge_Current "Battery pack available discharge current";
CM_ SG_ 2360789454 Available_Pulse_Charge_Current "Battery pack available pulse charge current";
CM_ SG_ 2360789454 Available_Pulse_Discharge_Curren "Battery pack available pulse discharge current";
CM_ SG_ 2360789455 Available_Charge_Current "Battery pack available charge current";
CM_ SG_ 2360789455 Available_Discharge_Current "Battery pack available discharge current";
CM_ SG_ 2360789455 Available_Pulse_Charge_Current "Battery pack available pulse charge current";
CM_ SG_ 2360789455 Available_Pulse_Discharge_Curren "Battery pack available pulse discharge current";
CM_ SG_ 2360789456 Available_Charge_Current "Battery pack available charge current";
CM_ SG_ 2360789456 Available_Discharge_Current "Battery pack available discharge current";
CM_ SG_ 2360789456 Available_Pulse_Charge_Current "Battery pack available pulse charge current";
CM_ SG_ 2360789456 Available_Pulse_Discharge_Curren "Battery pack available pulse discharge current";
CM_ SG_ 2360789457 Available_Charge_Current "Battery pack available charge current";
CM_ SG_ 2360789457 Available_Discharge_Current "Battery pack available discharge current";
CM_ SG_ 2360789457 Available_Pulse_Charge_Current "Battery pack available pulse charge current";
CM_ SG_ 2360789457 Available_Pulse_Discharge_Curren "Battery pack available pulse discharge current";
CM_ SG_ 2360789458 Available_Charge_Current "Battery pack available charge current";
CM_ SG_ 2360789458 Available_Discharge_Current "Battery pack available discharge current";
CM_ SG_ 2360789458 Available_Pulse_Charge_Current "Battery pack available pulse charge current";
CM_ SG_ 2360789458 Available_Pulse_Discharge_Curren "Battery pack available pulse discharge current";
CM_ SG_ 2360789459 Available_Charge_Current "Battery pack available charge current";
CM_ SG_ 2360789459 Available_Discharge_Current "Battery pack available discharge current";
CM_ SG_ 2360789459 Available_Pulse_Charge_Current "Battery pack available pulse charge current";
CM_ SG_ 2360789459 Available_Pulse_Discharge_Curren "Battery pack available pulse discharge current";
CM_ SG_ 2360789460 Available_Charge_Current "Battery pack available charge current";
CM_ SG_ 2360789460 Available_Discharge_Current "Battery pack available discharge current";
CM_ SG_ 2360789460 Available_Pulse_Charge_Current "Battery pack available pulse charge current";
CM_ SG_ 2360789460 Available_Pulse_Discharge_Curren "Battery pack available pulse discharge current";
CM_ SG_ 2360789461 Available_Charge_Current "Battery pack available charge current";
CM_ SG_ 2360789461 Available_Discharge_Current "Battery pack available discharge current";
CM_ SG_ 2360789461 Available_Pulse_Charge_Current "Battery pack available pulse charge current";
CM_ SG_ 2360789461 Available_Pulse_Discharge_Curren "Battery pack available pulse discharge current";
CM_ SG_ 2360789462 Available_Charge_Current "Battery pack available charge current";
CM_ SG_ 2360789462 Available_Discharge_Current "Battery pack available discharge current";
CM_ SG_ 2360789462 Available_Pulse_Charge_Current "Battery pack available pulse charge current";
CM_ SG_ 2360789462 Available_Pulse_Discharge_Curren "Battery pack available pulse discharge current";
CM_ SG_ 2360789463 Available_Charge_Current "Battery pack available charge current";
CM_ SG_ 2360789463 Available_Discharge_Current "Battery pack available discharge current";
CM_ SG_ 2360789463 Available_Pulse_Charge_Current "Battery pack available pulse charge current";
CM_ SG_ 2360789463 Available_Pulse_Discharge_Curren "Battery pack available pulse discharge current";
CM_ SG_ 2360789464 Available_Charge_Current "Battery pack available charge current";
CM_ SG_ 2360789464 Available_Discharge_Current "Battery pack available discharge current";
CM_ SG_ 2360789464 Available_Pulse_Charge_Current "Battery pack available pulse charge current";
CM_ SG_ 2360789464 Available_Pulse_Discharge_Curren "Battery pack available pulse discharge current";
CM_ SG_ 2360854985 Charge_Pulse_Counter "Battery pack charge pulse counter";
CM_ SG_ 2360854985 Discharge_Pulse_Counter "Battery pack discharge pulse counter";
CM_ SG_ 2360854986 Charge_Pulse_Counter "Battery pack charge pulse counter";
CM_ SG_ 2360854986 Discharge_Pulse_Counter "Battery pack discharge pulse counter";
CM_ SG_ 2360854987 Charge_Pulse_Counter "Battery pack charge pulse counter";
CM_ SG_ 2360854987 Discharge_Pulse_Counter "Battery pack discharge pulse counter";
CM_ SG_ 2360854988 Charge_Pulse_Counter "Battery pack charge pulse counter";
CM_ SG_ 2360854988 Discharge_Pulse_Counter "Battery pack discharge pulse counter";
CM_ SG_ 2360854989 Charge_Pulse_Counter "Battery pack charge pulse counter";
CM_ SG_ 2360854989 Discharge_Pulse_Counter "Battery pack discharge pulse counter";
CM_ SG_ 2360854990 Charge_Pulse_Counter "Battery pack charge pulse counter";
CM_ SG_ 2360854990 Discharge_Pulse_Counter "Battery pack discharge pulse counter";
CM_ SG_ 2360854991 Charge_Pulse_Counter "Battery pack charge pulse counter";
CM_ SG_ 2360854991 Discharge_Pulse_Counter "Battery pack discharge pulse counter";
CM_ SG_ 2360854992 Charge_Pulse_Counter "Battery pack charge pulse counter";
CM_ SG_ 2360854992 Discharge_Pulse_Counter "Battery pack discharge pulse counter";
CM_ SG_ 2360854993 Charge_Pulse_Counter "Battery pack charge pulse counter";
CM_ SG_ 2360854993 Discharge_Pulse_Counter "Battery pack discharge pulse counter";
CM_ SG_ 2360854994 Charge_Pulse_Counter "Battery pack charge pulse counter";
CM_ SG_ 2360854994 Discharge_Pulse_Counter "Battery pack discharge pulse counter";
CM_ SG_ 2360854995 Charge_Pulse_Counter "Battery pack charge pulse counter";
CM_ SG_ 2360854995 Discharge_Pulse_Counter "Battery pack discharge pulse counter";
CM_ SG_ 2360854996 Charge_Pulse_Counter "Battery pack charge pulse counter";
CM_ SG_ 2360854996 Discharge_Pulse_Counter "Battery pack discharge pulse counter";
CM_ SG_ 2360854997 Charge_Pulse_Counter "Battery pack charge pulse counter";
CM_ SG_ 2360854997 Discharge_Pulse_Counter "Battery pack discharge pulse counter";
CM_ SG_ 2360854998 Charge_Pulse_Counter "Battery pack charge pulse counter";
CM_ SG_ 2360854998 Discharge_Pulse_Counter "Battery pack discharge pulse counter";
CM_ SG_ 2360854999 Charge_Pulse_Counter "Battery pack charge pulse counter";
CM_ SG_ 2360854999 Discharge_Pulse_Counter "Battery pack discharge pulse counter";
CM_ SG_ 2360855000 Charge_Pulse_Counter "Battery pack charge pulse counter";
CM_ SG_ 2360855000 Discharge_Pulse_Counter "Battery pack discharge pulse counter";

BA_DEF_ BO_ "GenMsgCycleTime" INT 0 65535;
BA_DEF_ BO_ "VFrameFormat" ENUM  "StandardCAN","ExtendedCAN","reserved","J1939PG";
BA_DEF_ SG_ "GenSigStartValue" FLOAT 0 100000000000;
BA_DEF_  "ProtocolType" STRING;

BA_ "ProtocolType"   "J1939";

BA_ "GenMsgCycleTime" BO_ 2364525001 20;
BA_ "VFrameFormat" BO_ 2364525001 3;
BA_ "GenMsgCycleTime" BO_ 2364525257 20;
BA_ "VFrameFormat" BO_ 2364525257 3;
BA_ "GenMsgCycleTime" BO_ 2364525513 20;
BA_ "VFrameFormat" BO_ 2364525513 3;
BA_ "GenMsgCycleTime" BO_ 2364525769 20;
BA_ "VFrameFormat" BO_ 2364525769 3;
BA_ "GenMsgCycleTime" BO_ 2364526025 20;
BA_ "VFrameFormat" BO_ 2364526025 3;
BA_ "GenMsgCycleTime" BO_ 2364526281 20;
BA_ "VFrameFormat" BO_ 2364526281 3;
BA_ "GenMsgCycleTime" BO_ 2364526537 20;
BA_ "VFrameFormat" BO_ 2364526537 3;
BA_ "GenMsgCycleTime" BO_ 2364526793 20;
BA_ "VFrameFormat" BO_ 2364526793 3;
BA_ "GenMsgCycleTime" BO_ 2364527049 20;
BA_ "VFrameFormat" BO_ 2364527049 3;
BA_ "GenMsgCycleTime" BO_ 2364527305 20;
BA_ "VFrameFormat" BO_ 2364527305 3;
BA_ "GenMsgCycleTime" BO_ 2364527561 20;
BA_ "VFrameFormat" BO_ 2364527561 3;
BA_ "GenMsgCycleTime" BO_ 2364527817 20;
BA_ "VFrameFormat" BO_ 2364527817 3;
BA_ "GenMsgCycleTime" BO_ 2364528073 20;
BA_ "VFrameFormat" BO_ 2364528073 3;
BA_ "GenMsgCycleTime" BO_ 2364528329 20;
BA_ "VFrameFormat" BO_ 2364528329 3;
BA_ "GenMsgCycleTime" BO_ 2364528585 20;
BA_ "VFrameFormat" BO_ 2364528585 3;
BA_ "GenMsgCycleTime" BO_ 2364528841 20;
BA_ "VFrameFormat" BO_ 2364528841 3;
BA_ "GenMsgCycleTime" BO_ 2365587401 20;
BA_ "VFrameFormat" BO_ 2365587401 3;
BA_ "GenMsgCycleTime" BO_ 2365587145 1000;
BA_ "VFrameFormat" BO_ 2365587145 3;
BA_ "GenMsgCycleTime" BO_ 2566834889 1000;
BA_ "VFrameFormat" BO_ 2566834889 3;
BA_ "GenMsgCycleTime" BO_ 2566834890 1000;
BA_ "VFrameFormat" BO_ 2566834890 3;
BA_ "GenMsgCycleTime" BO_ 2566834891 1000;
BA_ "VFrameFormat" BO_ 2566834891 3;
BA_ "GenMsgCycleTime" BO_ 2566834892 1000;
BA_ "VFrameFormat" BO_ 2566834892 3;
BA_ "GenMsgCycleTime" BO_ 2566834893 1000;
BA_ "VFrameFormat" BO_ 2566834893 3;
BA_ "GenMsgCycleTime" BO_ 2566834894 1000;
BA_ "VFrameFormat" BO_ 2566834894 3;
BA_ "GenMsgCycleTime" BO_ 2566834895 1000;
BA_ "VFrameFormat" BO_ 2566834895 3;
BA_ "GenMsgCycleTime" BO_ 2566834896 1000;
BA_ "VFrameFormat" BO_ 2566834896 3;
BA_ "GenMsgCycleTime" BO_ 2566834897 1000;
BA_ "VFrameFormat" BO_ 2566834897 3;
BA_ "GenMsgCycleTime" BO_ 2566834898 1000;
BA_ "VFrameFormat" BO_ 2566834898 3;
BA_ "GenMsgCycleTime" BO_ 2566834899 1000;
BA_ "VFrameFormat" BO_ 2566834899 3;
BA_ "GenMsgCycleTime" BO_ 2566834900 1000;
BA_ "VFrameFormat" BO_ 2566834900 3;
BA_ "GenMsgCycleTime" BO_ 2566834901 1000;
BA_ "VFrameFormat" BO_ 2566834901 3;
BA_ "GenMsgCycleTime" BO_ 2566834902 1000;
BA_ "VFrameFormat" BO_ 2566834902 3;
BA_ "GenMsgCycleTime" BO_ 2566834903 1000;
BA_ "VFrameFormat" BO_ 2566834903 3;
BA_ "GenMsgCycleTime" BO_ 2566834904 1000;
BA_ "VFrameFormat" BO_ 2566834904 3;
BA_ "GenMsgCycleTime" BO_ 2360461769 20;
BA_ "VFrameFormat" BO_ 2360461769 3;
BA_ "GenMsgCycleTime" BO_ 2360461770 20;
BA_ "VFrameFormat" BO_ 2360461770 3;
BA_ "GenMsgCycleTime" BO_ 2360461771 20;
BA_ "VFrameFormat" BO_ 2360461771 3;
BA_ "GenMsgCycleTime" BO_ 2360461772 20;
BA_ "VFrameFormat" BO_ 2360461772 3;
BA_ "GenMsgCycleTime" BO_ 2360461773 20;
BA_ "VFrameFormat" BO_ 2360461773 3;
BA_ "GenMsgCycleTime" BO_ 2360461774 20;
BA_ "VFrameFormat" BO_ 2360461774 3;
BA_ "GenMsgCycleTime" BO_ 2360461775 20;
BA_ "VFrameFormat" BO_ 2360461775 3;
BA_ "GenMsgCycleTime" BO_ 2360461776 20;
BA_ "VFrameFormat" BO_ 2360461776 3;
BA_ "GenMsgCycleTime" BO_ 2360461777 20;
BA_ "VFrameFormat" BO_ 2360461777 3;
BA_ "GenMsgCycleTime" BO_ 2360461778 20;
BA_ "VFrameFormat" BO_ 2360461778 3;
BA_ "GenMsgCycleTime" BO_ 2360461779 20;
BA_ "VFrameFormat" BO_ 2360461779 3;
BA_ "GenMsgCycleTime" BO_ 2360461780 20;
BA_ "VFrameFormat" BO_ 2360461780 3;
BA_ "GenMsgCycleTime" BO_ 2360461781 20;
BA_ "VFrameFormat" BO_ 2360461781 3;
BA_ "GenMsgCycleTime" BO_ 2360461782 20;
BA_ "VFrameFormat" BO_ 2360461782 3;
BA_ "GenMsgCycleTime" BO_ 2360461783 20;
BA_ "VFrameFormat" BO_ 2360461783 3;
BA_ "GenMsgCycleTime" BO_ 2360461784 20;
BA_ "VFrameFormat" BO_ 2360461784 3;
BA_ "GenMsgCycleTime" BO_ 2360527305 50;
BA_ "VFrameFormat" BO_ 2360527305 3;
BA_ "GenMsgCycleTime" BO_ 2360527306 50;
BA_ "VFrameFormat" BO_ 2360527306 3;
BA_ "GenMsgCycleTime" BO_ 2360527307 50;
BA_ "VFrameFormat" BO_ 2360527307 3;
BA_ "GenMsgCycleTime" BO_ 2360527308 50;
BA_ "VFrameFormat" BO_ 2360527308 3;
BA_ "GenMsgCycleTime" BO_ 2360527309 50;
BA_ "VFrameFormat" BO_ 2360527309 3;
BA_ "GenMsgCycleTime" BO_ 2360527310 50;
BA_ "VFrameFormat" BO_ 2360527310 3;
BA_ "GenMsgCycleTime" BO_ 2360527311 50;
BA_ "VFrameFormat" BO_ 2360527311 3;
BA_ "GenMsgCycleTime" BO_ 2360527312 50;
BA_ "VFrameFormat" BO_ 2360527312 3;
BA_ "GenMsgCycleTime" BO_ 2360527313 50;
BA_ "VFrameFormat" BO_ 2360527313 3;
BA_ "GenMsgCycleTime" BO_ 2360527314 50;
BA_ "VFrameFormat" BO_ 2360527314 3;
BA_ "GenMsgCycleTime" BO_ 2360527315 50;
BA_ "VFrameFormat" BO_ 2360527315 3;
BA_ "GenMsgCycleTime" BO_ 2360527316 50;
BA_ "VFrameFormat" BO_ 2360527316 3;
BA_ "GenMsgCycleTime" BO_ 2360527317 50;
BA_ "VFrameFormat" BO_ 2360527317 3;
BA_ "GenMsgCycleTime" BO_ 2360527318 50;
BA_ "VFrameFormat" BO_ 2360527318 3;
BA_ "GenMsgCycleTime" BO_ 2360527319 50;
BA_ "VFrameFormat" BO_ 2360527319 3;
BA_ "GenMsgCycleTime" BO_ 2360527320 50;
BA_ "VFrameFormat" BO_ 2360527320 3;
BA_ "GenMsgCycleTime" BO_ 2360592841 1000;
BA_ "VFrameFormat" BO_ 2360592841 3;
BA_ "GenMsgCycleTime" BO_ 2360592842 1000;
BA_ "VFrameFormat" BO_ 2360592842 3;
BA_ "GenMsgCycleTime" BO_ 2360592843 1000;
BA_ "VFrameFormat" BO_ 2360592843 3;
BA_ "GenMsgCycleTime" BO_ 2360592844 1000;
BA_ "VFrameFormat" BO_ 2360592844 3;
BA_ "GenMsgCycleTime" BO_ 2360592845 1000;
BA_ "VFrameFormat" BO_ 2360592845 3;
BA_ "GenMsgCycleTime" BO_ 2360592846 1000;
BA_ "VFrameFormat" BO_ 2360592846 3;
BA_ "GenMsgCycleTime" BO_ 2360592847 1000;
BA_ "VFrameFormat" BO_ 2360592847 3;
BA_ "GenMsgCycleTime" BO_ 2360592848 1000;
BA_ "VFrameFormat" BO_ 2360592848 3;
BA_ "GenMsgCycleTime" BO_ 2360592849 1000;
BA_ "VFrameFormat" BO_ 2360592849 3;
BA_ "GenMsgCycleTime" BO_ 2360592850 1000;
BA_ "VFrameFormat" BO_ 2360592850 3;
BA_ "GenMsgCycleTime" BO_ 2360592851 1000;
BA_ "VFrameFormat" BO_ 2360592851 3;
BA_ "GenMsgCycleTime" BO_ 2360592852 1000;
BA_ "VFrameFormat" BO_ 2360592852 3;
BA_ "GenMsgCycleTime" BO_ 2360592853 1000;
BA_ "VFrameFormat" BO_ 2360592853 3;
BA_ "GenMsgCycleTime" BO_ 2360592854 1000;
BA_ "VFrameFormat" BO_ 2360592854 3;
BA_ "GenMsgCycleTime" BO_ 2360592855 1000;
BA_ "VFrameFormat" BO_ 2360592855 3;
BA_ "GenMsgCycleTime" BO_ 2360592856 1000;
BA_ "VFrameFormat" BO_ 2360592856 3;
BA_ "GenMsgCycleTime" BO_ 2360658377 1000;
BA_ "VFrameFormat" BO_ 2360658377 3;
BA_ "GenMsgCycleTime" BO_ 2360658378 1000;
BA_ "VFrameFormat" BO_ 2360658378 3;
BA_ "GenMsgCycleTime" BO_ 2360658379 1000;
BA_ "VFrameFormat" BO_ 2360658379 3;
BA_ "GenMsgCycleTime" BO_ 2360658380 1000;
BA_ "VFrameFormat" BO_ 2360658380 3;
BA_ "GenMsgCycleTime" BO_ 2360658381 1000;
BA_ "VFrameFormat" BO_ 2360658381 3;
BA_ "GenMsgCycleTime" BO_ 2360658382 1000;
BA_ "VFrameFormat" BO_ 2360658382 3;
BA_ "GenMsgCycleTime" BO_ 2360658383 1000;
BA_ "VFrameFormat" BO_ 2360658383 3;
BA_ "GenMsgCycleTime" BO_ 2360658384 1000;
BA_ "VFrameFormat" BO_ 2360658384 3;
BA_ "GenMsgCycleTime" BO_ 2360658385 1000;
BA_ "VFrameFormat" BO_ 2360658385 3;
BA_ "GenMsgCycleTime" BO_ 2360658386 1000;
BA_ "VFrameFormat" BO_ 2360658386 3;
BA_ "GenMsgCycleTime" BO_ 2360658387 1000;
BA_ "VFrameFormat" BO_ 2360658387 3;
BA_ "GenMsgCycleTime" BO_ 2360658388 1000;
BA_ "VFrameFormat" BO_ 2360658388 3;
BA_ "GenMsgCycleTime" BO_ 2360658389 1000;
BA_ "VFrameFormat" BO_ 2360658389 3;
BA_ "GenMsgCycleTime" BO_ 2360658390 1000;
BA_ "VFrameFormat" BO_ 2360658390 3;
BA_ "GenMsgCycleTime" BO_ 2360658391 1000;
BA_ "VFrameFormat" BO_ 2360658391 3;
BA_ "GenMsgCycleTime" BO_ 2360658392 1000;
BA_ "VFrameFormat" BO_ 2360658392 3;
BA_ "GenMsgCycleTime" BO_ 2360723913 1000;
BA_ "VFrameFormat" BO_ 2360723913 3;
BA_ "GenMsgCycleTime" BO_ 2360723914 1000;
BA_ "VFrameFormat" BO_ 2360723914 3;
BA_ "GenMsgCycleTime" BO_ 2360723915 1000;
BA_ "VFrameFormat" BO_ 2360723915 3;
BA_ "GenMsgCycleTime" BO_ 2360723916 1000;
BA_ "VFrameFormat" BO_ 2360723916 3;
BA_ "GenMsgCycleTime" BO_ 2360723917 1000;
BA_ "VFrameFormat" BO_ 2360723917 3;
BA_ "GenMsgCycleTime" BO_ 2360723918 1000;
BA_ "VFrameFormat" BO_ 2360723918 3;
BA_ "GenMsgCycleTime" BO_ 2360723919 1000;
BA_ "VFrameFormat" BO_ 2360723919 3;
BA_ "GenMsgCycleTime" BO_ 2360723920 1000;
BA_ "VFrameFormat" BO_ 2360723920 3;
BA_ "GenMsgCycleTime" BO_ 2360723921 1000;
BA_ "VFrameFormat" BO_ 2360723921 3;
BA_ "GenMsgCycleTime" BO_ 2360723922 1000;
BA_ "VFrameFormat" BO_ 2360723922 3;
BA_ "GenMsgCycleTime" BO_ 2360723923 1000;
BA_ "VFrameFormat" BO_ 2360723923 3;
BA_ "GenMsgCycleTime" BO_ 2360723924 1000;
BA_ "VFrameFormat" BO_ 2360723924 3;
BA_ "GenMsgCycleTime" BO_ 2360723925 1000;
BA_ "VFrameFormat" BO_ 2360723925 3;
BA_ "GenMsgCycleTime" BO_ 2360723926 1000;
BA_ "VFrameFormat" BO_ 2360723926 3;
BA_ "GenMsgCycleTime" BO_ 2360723927 1000;
BA_ "VFrameFormat" BO_ 2360723927 3;
BA_ "GenMsgCycleTime" BO_ 2360723928 1000;
BA_ "VFrameFormat" BO_ 2360723928 3;
BA_ "GenMsgCycleTime" BO_ 2360789449 50;
BA_ "VFrameFormat" BO_ 2360789449 3;
BA_ "GenMsgCycleTime" BO_ 2360789450 50;
BA_ "VFrameFormat" BO_ 2360789450 3;
BA_ "GenMsgCycleTime" BO_ 2360789451 50;
BA_ "VFrameFormat" BO_ 2360789451 3;
BA_ "GenMsgCycleTime" BO_ 2360789452 50;
BA_ "VFrameFormat" BO_ 2360789452 3;
BA_ "GenMsgCycleTime" BO_ 2360789453 50;
BA_ "VFrameFormat" BO_ 2360789453 3;
BA_ "GenMsgCycleTime" BO_ 2360789454 50;
BA_ "VFrameFormat" BO_ 2360789454 3;
BA_ "GenMsgCycleTime" BO_ 2360789455 50;
BA_ "VFrameFormat" BO_ 2360789455 3;
BA_ "GenMsgCycleTime" BO_ 2360789456 50;
BA_ "VFrameFormat" BO_ 2360789456 3;
BA_ "GenMsgCycleTime" BO_ 2360789457 50;
BA_ "VFrameFormat" BO_ 2360789457 3;
BA_ "GenMsgCycleTime" BO_ 2360789458 50;
BA_ "VFrameFormat" BO_ 2360789458 3;
BA_ "GenMsgCycleTime" BO_ 2360789459 50;
BA_ "VFrameFormat" BO_ 2360789459 3;
BA_ "GenMsgCycleTime" BO_ 2360789460 50;
BA_ "VFrameFormat" BO_ 2360789460 3;
BA_ "GenMsgCycleTime" BO_ 2360789461 50;
BA_ "VFrameFormat" BO_ 2360789461 3;
BA_ "GenMsgCycleTime" BO_ 2360789462 50;
BA_ "VFrameFormat" BO_ 2360789462 3;
BA_ "GenMsgCycleTime" BO_ 2360789463 50;
BA_ "VFrameFormat" BO_ 2360789463 3;
BA_ "GenMsgCycleTime" BO_ 2360789464 50;
BA_ "VFrameFormat" BO_ 2360789464 3;
BA_ "GenMsgCycleTime" BO_ 2360854985 50;
BA_ "VFrameFormat" BO_ 2360854985 3;
BA_ "GenMsgCycleTime" BO_ 2360854986 50;
BA_ "VFrameFormat" BO_ 2360854986 3;
BA_ "GenMsgCycleTime" BO_ 2360854987 50;
BA_ "VFrameFormat" BO_ 2360854987 3;
BA_ "GenMsgCycleTime" BO_ 2360854988 50;
BA_ "VFrameFormat" BO_ 2360854988 3;
BA_ "GenMsgCycleTime" BO_ 2360854989 50;
BA_ "VFrameFormat" BO_ 2360854989 3;
BA_ "GenMsgCycleTime" BO_ 2360854990 50;
BA_ "VFrameFormat" BO_ 2360854990 3;
BA_ "GenMsgCycleTime" BO_ 2360854991 50;
BA_ "VFrameFormat" BO_ 2360854991 3;
BA_ "GenMsgCycleTime" BO_ 2360854992 50;
BA_ "VFrameFormat" BO_ 2360854992 3;
BA_ "GenMsgCycleTime" BO_ 2360854993 50;
BA_ "VFrameFormat" BO_ 2360854993 3;
BA_ "GenMsgCycleTime" BO_ 2360854994 50;
BA_ "VFrameFormat" BO_ 2360854994 3;
BA_ "GenMsgCycleTime" BO_ 2360854995 50;
BA_ "VFrameFormat" BO_ 2360854995 3;
BA_ "GenMsgCycleTime" BO_ 2360854996 50;
BA_ "VFrameFormat" BO_ 2360854996 3;
BA_ "GenMsgCycleTime" BO_ 2360854997 50;
BA_ "VFrameFormat" BO_ 2360854997 3;
BA_ "GenMsgCycleTime" BO_ 2360854998 50;
BA_ "VFrameFormat" BO_ 2360854998 3;
BA_ "GenMsgCycleTime" BO_ 2360854999 50;
BA_ "VFrameFormat" BO_ 2360854999 3;
BA_ "GenMsgCycleTime" BO_ 2360855000 50;
BA_ "VFrameFormat" BO_ 2360855000 3;

BA_ "GenSigStartValue" SG_ 2365587401 System_Current 32000;
BA_ "GenSigStartValue" SG_ 2365587401 System_Average_Current_Connected 32000;
BA_ "GenSigStartValue" SG_ 2360461769 Current 32000;
BA_ "GenSigStartValue" SG_ 2360461770 Current 32000;
BA_ "GenSigStartValue" SG_ 2360461771 Current 32000;
BA_ "GenSigStartValue" SG_ 2360461772 Current 32000;
BA_ "GenSigStartValue" SG_ 2360461773 Current 32000;
BA_ "GenSigStartValue" SG_ 2360461774 Current 32000;
BA_ "GenSigStartValue" SG_ 2360461775 Current 32000;
BA_ "GenSigStartValue" SG_ 2360461776 Current 32000;
BA_ "GenSigStartValue" SG_ 2360461777 Current 32000;
BA_ "GenSigStartValue" SG_ 2360461778 Current 32000;
BA_ "GenSigStartValue" SG_ 2360461779 Current 32000;
BA_ "GenSigStartValue" SG_ 2360461780 Current 32000;
BA_ "GenSigStartValue" SG_ 2360461781 Current 32000;
BA_ "GenSigStartValue" SG_ 2360461782 Current 32000;
BA_ "GenSigStartValue" SG_ 2360461783 Current 32000;
BA_ "GenSigStartValue" SG_ 2360461784 Current 32000;
BA_ "GenSigStartValue" SG_ 2360527305 Instantaneous_Power 4080;
BA_ "GenSigStartValue" SG_ 2360527306 Instantaneous_Power 4080;
BA_ "GenSigStartValue" SG_ 2360527307 Instantaneous_Power 4080;
BA_ "GenSigStartValue" SG_ 2360527308 Instantaneous_Power 4080;
BA_ "GenSigStartValue" SG_ 2360527309 Instantaneous_Power 4080;
BA_ "GenSigStartValue" SG_ 2360527310 Instantaneous_Power 4080;
BA_ "GenSigStartValue" SG_ 2360527311 Instantaneous_Power 4080;
BA_ "GenSigStartValue" SG_ 2360527312 Instantaneous_Power 4080;
BA_ "GenSigStartValue" SG_ 2360527313 Instantaneous_Power 4080;
BA_ "GenSigStartValue" SG_ 2360527314 Instantaneous_Power 4080;
BA_ "GenSigStartValue" SG_ 2360527315 Instantaneous_Power 4080;
BA_ "GenSigStartValue" SG_ 2360527316 Instantaneous_Power 4080;
BA_ "GenSigStartValue" SG_ 2360527317 Instantaneous_Power 4080;
BA_ "GenSigStartValue" SG_ 2360527318 Instantaneous_Power 4080;
BA_ "GenSigStartValue" SG_ 2360527319 Instantaneous_Power 4080;
BA_ "GenSigStartValue" SG_ 2360527320 Instantaneous_Power 4080;
BA_ "GenSigStartValue" SG_ 2360592841 Lowest_Cell_Temperature 1000;
BA_ "GenSigStartValue" SG_ 2360592841 Highest_Cell_Temperature 1000;
BA_ "GenSigStartValue" SG_ 2360592842 Lowest_Cell_Temperature 1000;
BA_ "GenSigStartValue" SG_ 2360592842 Highest_Cell_Temperature 1000;
BA_ "GenSigStartValue" SG_ 2360592843 Lowest_Cell_Temperature 1000;
BA_ "GenSigStartValue" SG_ 2360592843 Highest_Cell_Temperature 1000;
BA_ "GenSigStartValue" SG_ 2360592844 Lowest_Cell_Temperature 1000;
BA_ "GenSigStartValue" SG_ 2360592844 Highest_Cell_Temperature 1000;
BA_ "GenSigStartValue" SG_ 2360592845 Lowest_Cell_Temperature 1000;
BA_ "GenSigStartValue" SG_ 2360592845 Highest_Cell_Temperature 1000;
BA_ "GenSigStartValue" SG_ 2360592846 Lowest_Cell_Temperature 1000;
BA_ "GenSigStartValue" SG_ 2360592846 Highest_Cell_Temperature 1000;
BA_ "GenSigStartValue" SG_ 2360592847 Lowest_Cell_Temperature 1000;
BA_ "GenSigStartValue" SG_ 2360592847 Highest_Cell_Temperature 1000;
BA_ "GenSigStartValue" SG_ 2360592848 Lowest_Cell_Temperature 1000;
BA_ "GenSigStartValue" SG_ 2360592848 Highest_Cell_Temperature 1000;
BA_ "GenSigStartValue" SG_ 2360592849 Lowest_Cell_Temperature 1000;
BA_ "GenSigStartValue" SG_ 2360592849 Highest_Cell_Temperature 1000;
BA_ "GenSigStartValue" SG_ 2360592850 Lowest_Cell_Temperature 1000;
BA_ "GenSigStartValue" SG_ 2360592850 Highest_Cell_Temperature 1000;
BA_ "GenSigStartValue" SG_ 2360592851 Lowest_Cell_Temperature 1000;
BA_ "GenSigStartValue" SG_ 2360592851 Highest_Cell_Temperature 1000;
BA_ "GenSigStartValue" SG_ 2360592852 Lowest_Cell_Temperature 1000;
BA_ "GenSigStartValue" SG_ 2360592852 Highest_Cell_Temperature 1000;
BA_ "GenSigStartValue" SG_ 2360592853 Lowest_Cell_Temperature 1000;
BA_ "GenSigStartValue" SG_ 2360592853 Highest_Cell_Temperature 1000;
BA_ "GenSigStartValue" SG_ 2360592854 Lowest_Cell_Temperature 1000;
BA_ "GenSigStartValue" SG_ 2360592854 Highest_Cell_Temperature 1000;
BA_ "GenSigStartValue" SG_ 2360592855 Lowest_Cell_Temperature 1000;
BA_ "GenSigStartValue" SG_ 2360592855 Highest_Cell_Temperature 1000;
BA_ "GenSigStartValue" SG_ 2360592856 Lowest_Cell_Temperature 1000;
BA_ "GenSigStartValue" SG_ 2360592856 Highest_Cell_Temperature 1000;

VAL_ 2364525001 Connect_Command 0 "Disconnect" 1 "Pre-Charge" 2 "Hot Connect Load" 3 "Hot Connect Standby" 4 "Reserved" 5 "Reserved" 6 "Error" 7 "Don't care/Take no action (Treat";
VAL_ 2364525001 Disable_Command 0 "Disable pack not requested" 1 "Disable pack requested" 2 "Reserved" 3 "Don't care/Take no action (Treat";
VAL_ 2364525257 Connect_Command 0 "Disconnect" 1 "Pre-Charge" 2 "Hot Connect Load" 3 "Hot Connect Standby" 4 "Reserved" 5 "Reserved" 6 "Error" 7 "Don't care/Take no action (Treat";
VAL_ 2364525257 Disable_Command 0 "Disable pack not requested" 1 "Disable pack requested" 2 "Reserved" 3 "Don't care/Take no action (Treat";
VAL_ 2364525513 Connect_Command 0 "Disconnect" 1 "Pre-Charge" 2 "Hot Connect Load" 3 "Hot Connect Standby" 4 "Reserved" 5 "Reserved" 6 "Error" 7 "Don't care/Take no action (Treat";
VAL_ 2364525513 Disable_Command 0 "Disable pack not requested" 1 "Disable pack requested" 2 "Reserved" 3 "Don't care/Take no action (Treat";
VAL_ 2364525769 Connect_Command 0 "Disconnect" 1 "Pre-Charge" 2 "Hot Connect Load" 3 "Hot Connect Standby" 4 "Reserved" 5 "Reserved" 6 "Error" 7 "Don't care/Take no action (Treat";
VAL_ 2364525769 Disable_Command 0 "Disable pack not requested" 1 "Disable pack requested" 2 "Reserved" 3 "Don't care/Take no action (Treat";
VAL_ 2364526025 Connect_Command 0 "Disconnect" 1 "Pre-Charge" 2 "Hot Connect Load" 3 "Hot Connect Standby" 4 "Reserved" 5 "Reserved" 6 "Error" 7 "Don't care/Take no action (Treat";
VAL_ 2364526025 Disable_Command 0 "Disable pack not requested" 1 "Disable pack requested" 2 "Reserved" 3 "Don't care/Take no action (Treat";
VAL_ 2364526281 Connect_Command 0 "Disconnect" 1 "Pre-Charge" 2 "Hot Connect Load" 3 "Hot Connect Standby" 4 "Reserved" 5 "Reserved" 6 "Error" 7 "Don't care/Take no action (Treat";
VAL_ 2364526281 Disable_Command 0 "Disable pack not requested" 1 "Disable pack requested" 2 "Reserved" 3 "Don't care/Take no action (Treat";
VAL_ 2364526537 Connect_Command 0 "Disconnect" 1 "Pre-Charge" 2 "Hot Connect Load" 3 "Hot Connect Standby" 4 "Reserved" 5 "Reserved" 6 "Error" 7 "Don't care/Take no action (Treat";
VAL_ 2364526537 Disable_Command 0 "Disable pack not requested" 1 "Disable pack requested" 2 "Reserved" 3 "Don't care/Take no action (Treat";
VAL_ 2364526793 Connect_Command 0 "Disconnect" 1 "Pre-Charge" 2 "Hot Connect Load" 3 "Hot Connect Standby" 4 "Reserved" 5 "Reserved" 6 "Error" 7 "Don't care/Take no action (Treat";
VAL_ 2364526793 Disable_Command 0 "Disable pack not requested" 1 "Disable pack requested" 2 "Reserved" 3 "Don't care/Take no action (Treat";
VAL_ 2364527049 Connect_Command 0 "Disconnect" 1 "Pre-Charge" 2 "Hot Connect Load" 3 "Hot Connect Standby" 4 "Reserved" 5 "Reserved" 6 "Error" 7 "Don't care/Take no action (Treat";
VAL_ 2364527049 Disable_Command 0 "Disable pack not requested" 1 "Disable pack requested" 2 "Reserved" 3 "Don't care/Take no action (Treat";
VAL_ 2364527305 Connect_Command 0 "Disconnect" 1 "Pre-Charge" 2 "Hot Connect Load" 3 "Hot Connect Standby" 4 "Reserved" 5 "Reserved" 6 "Error" 7 "Don't care/Take no action (Treat";
VAL_ 2364527305 Disable_Command 0 "Disable pack not requested" 1 "Disable pack requested" 2 "Reserved" 3 "Don't care/Take no action (Treat";
VAL_ 2364527561 Connect_Command 0 "Disconnect" 1 "Pre-Charge" 2 "Hot Connect Load" 3 "Hot Connect Standby" 4 "Reserved" 5 "Reserved" 6 "Error" 7 "Don't care/Take no action (Treat";
VAL_ 2364527561 Disable_Command 0 "Disable pack not requested" 1 "Disable pack requested" 2 "Reserved" 3 "Don't care/Take no action (Treat";
VAL_ 2364527817 Connect_Command 0 "Disconnect" 1 "Pre-Charge" 2 "Hot Connect Load" 3 "Hot Connect Standby" 4 "Reserved" 5 "Reserved" 6 "Error" 7 "Don't care/Take no action (Treat";
VAL_ 2364527817 Disable_Command 0 "Disable pack not requested" 1 "Disable pack requested" 2 "Reserved" 3 "Don't care/Take no action (Treat";
VAL_ 2364528073 Connect_Command 0 "Disconnect" 1 "Pre-Charge" 2 "Hot Connect Load" 3 "Hot Connect Standby" 4 "Reserved" 5 "Reserved" 6 "Error" 7 "Don't care/Take no action (Treat";
VAL_ 2364528073 Disable_Command 0 "Disable pack not requested" 1 "Disable pack requested" 2 "Reserved" 3 "Don't care/Take no action (Treat";
VAL_ 2364528329 Connect_Command 0 "Disconnect" 1 "Pre-Charge" 2 "Hot Connect Load" 3 "Hot Connect Standby" 4 "Reserved" 5 "Reserved" 6 "Error" 7 "Don't care/Take no action (Treat";
VAL_ 2364528329 Disable_Command 0 "Disable pack not requested" 1 "Disable pack requested" 2 "Reserved" 3 "Don't care/Take no action (Treat";
VAL_ 2364528585 Connect_Command 0 "Disconnect" 1 "Pre-Charge" 2 "Hot Connect Load" 3 "Hot Connect Standby" 4 "Reserved" 5 "Reserved" 6 "Error" 7 "Don't care/Take no action (Treat";
VAL_ 2364528585 Disable_Command 0 "Disable pack not requested" 1 "Disable pack requested" 2 "Reserved" 3 "Don't care/Take no action (Treat";
VAL_ 2364528841 Connect_Command 0 "Disconnect" 1 "Pre-Charge" 2 "Hot Connect Load" 3 "Hot Connect Standby" 4 "Reserved" 5 "Reserved" 6 "Error" 7 "Don't care/Take no action (Treat";
VAL_ 2364528841 Disable_Command 0 "Disable pack not requested" 1 "Disable pack requested" 2 "Reserved" 3 "Don't care/Take no action (Treat";
VAL_ 2365587401 System_Current 65533 "Saturated" 65534 "Error" 65535 "Not Available";
VAL_ 2365587401 System_Average_Current_Connected 65533 "Saturated" 65534 "Error" 65535 "Not Available";
VAL_ 2365587401 System_HVDC_Bus_Voltage 65533 "Saturated" 65534 "Error" 65535 "Not Available";
VAL_ 2365587401 System_Charging_Mode 0 "Intent to discharge" 1 "Intent to charge" 2 "Intent to fast charge" 3 "Intent to charge for longevity";
VAL_ 2365587145 System_Unix_Time -3 "Saturated" -2 "Error" -1 "Not Available";
VAL_ 2365587145 System_Clear_DMs_Command 0 "Clear DMs not requested" 1 "Clear DMs requested" 2 "Reserved" 3 "Don't care/Take no action (Treat";
VAL_ 2360461769 Battery_Voltage 65533 "Saturated" 65534 "Error" 65535 "Not Available";
VAL_ 2360461769 HVDC_Bus_Voltage 65533 "Saturated" 65534 "Error" 65535 "Not Available";
VAL_ 2360461769 Current 65533 "Saturated" 65534 "Error" 65535 "Not Available";
VAL_ 2360461769 Operational_Status 0 "Initialization" 1 "Reserved" 2 "Operational" 3 "Keep Alive" 4 "Emergency Stop" 5 "Disabled" 6 "Fault" 7 "Periodic checkup" 8 "Reserved" 9 "Reserved" 10 "Reserved" 11 "Reserved" 12 "Reserved" 13 "Reserved" 14 "Error" 15 "Not Available";
VAL_ 2360461769 HVDC_Bus_Disconnect_Forewarning 0 "Disconnect not pending" 1 "Disconnect imminent due to batte" 2 "Disconnect imminent due to batte" 3 "Reserved" 4 "Reserved" 5 "Disconnect imminent due to cell " 6 "Disconnect imminent due to cell " 7 "Disconnect imminent due to batte" 8 "Reserved" 9 "Reserved" 10 "Reserved" 11 "Reserved" 12 "Reserved" 13 "Disconnect imminent - no reason " 14 "Error" 15 "Not Available";
VAL_ 2360461769 HVDC_Bus_Connection_Status 0 "Disconnected" 1 "Connected" 2 "Connection in Progress" 3 "Disconnection in Progress" 4 "Reserved" 5 "Reserved" 6 "Error" 7 "Not Available";
VAL_ 2360461769 Pre_Charge_Ready 0 "Pre-Charge Not Ready" 1 "Pre-Charge Ready" 2 "Error" 3 "Not Available";
VAL_ 2360461770 Battery_Voltage 65533 "Saturated" 65534 "Error" 65535 "Not Available";
VAL_ 2360461770 HVDC_Bus_Voltage 65533 "Saturated" 65534 "Error" 65535 "Not Available";
VAL_ 2360461770 Current 65533 "Saturated" 65534 "Error" 65535 "Not Available";
VAL_ 2360461770 Operational_Status 0 "Initialization" 1 "Reserved" 2 "Operational" 3 "Keep Alive" 4 "Emergency Stop" 5 "Disabled" 6 "Fault" 7 "Periodic checkup" 8 "Reserved" 9 "Reserved" 10 "Reserved" 11 "Reserved" 12 "Reserved" 13 "Reserved" 14 "Error" 15 "Not Available";
VAL_ 2360461770 HVDC_Bus_Disconnect_Forewarning 0 "Disconnect not pending" 1 "Disconnect imminent due to batte" 2 "Disconnect imminent due to batte" 3 "Reserved" 4 "Reserved" 5 "Disconnect imminent due to cell " 6 "Disconnect imminent due to cell " 7 "Disconnect imminent due to batte" 8 "Reserved" 9 "Reserved" 10 "Reserved" 11 "Reserved" 12 "Reserved" 13 "Disconnect imminent - no reason " 14 "Error" 15 "Not Available";
VAL_ 2360461770 HVDC_Bus_Connection_Status 0 "Disconnected" 1 "Connected" 2 "Connection in Progress" 3 "Disconnection in Progress" 4 "Reserved" 5 "Reserved" 6 "Error" 7 "Not Available";
VAL_ 2360461770 Pre_Charge_Ready 0 "Pre-Charge Not Ready" 1 "Pre-Charge Ready" 2 "Error" 3 "Not Available";
VAL_ 2360461771 Battery_Voltage 65533 "Saturated" 65534 "Error" 65535 "Not Available";
VAL_ 2360461771 HVDC_Bus_Voltage 65533 "Saturated" 65534 "Error" 65535 "Not Available";
VAL_ 2360461771 Current 65533 "Saturated" 65534 "Error" 65535 "Not Available";
VAL_ 2360461771 Operational_Status 0 "Initialization" 1 "Reserved" 2 "Operational" 3 "Keep Alive" 4 "Emergency Stop" 5 "Disabled" 6 "Fault" 7 "Periodic checkup" 8 "Reserved" 9 "Reserved" 10 "Reserved" 11 "Reserved" 12 "Reserved" 13 "Reserved" 14 "Error" 15 "Not Available";
VAL_ 2360461771 HVDC_Bus_Disconnect_Forewarning 0 "Disconnect not pending" 1 "Disconnect imminent due to batte" 2 "Disconnect imminent due to batte" 3 "Reserved" 4 "Reserved" 5 "Disconnect imminent due to cell " 6 "Disconnect imminent due to cell " 7 "Disconnect imminent due to batte" 8 "Reserved" 9 "Reserved" 10 "Reserved" 11 "Reserved" 12 "Reserved" 13 "Disconnect imminent - no reason " 14 "Error" 15 "Not Available";
VAL_ 2360461771 HVDC_Bus_Connection_Status 0 "Disconnected" 1 "Connected" 2 "Connection in Progress" 3 "Disconnection in Progress" 4 "Reserved" 5 "Reserved" 6 "Error" 7 "Not Available";
VAL_ 2360461771 Pre_Charge_Ready 0 "Pre-Charge Not Ready" 1 "Pre-Charge Ready" 2 "Error" 3 "Not Available";
VAL_ 2360461772 Battery_Voltage 65533 "Saturated" 65534 "Error" 65535 "Not Available";
VAL_ 2360461772 HVDC_Bus_Voltage 65533 "Saturated" 65534 "Error" 65535 "Not Available";
VAL_ 2360461772 Current 65533 "Saturated" 65534 "Error" 65535 "Not Available";
VAL_ 2360461772 Operational_Status 0 "Initialization" 1 "Reserved" 2 "Operational" 3 "Keep Alive" 4 "Emergency Stop" 5 "Disabled" 6 "Fault" 7 "Periodic checkup" 8 "Reserved" 9 "Reserved" 10 "Reserved" 11 "Reserved" 12 "Reserved" 13 "Reserved" 14 "Error" 15 "Not Available";
VAL_ 2360461772 HVDC_Bus_Disconnect_Forewarning 0 "Disconnect not pending" 1 "Disconnect imminent due to batte" 2 "Disconnect imminent due to batte" 3 "Reserved" 4 "Reserved" 5 "Disconnect imminent due to cell " 6 "Disconnect imminent due to cell " 7 "Disconnect imminent due to batte" 8 "Reserved" 9 "Reserved" 10 "Reserved" 11 "Reserved" 12 "Reserved" 13 "Disconnect imminent - no reason " 14 "Error" 15 "Not Available";
VAL_ 2360461772 HVDC_Bus_Connection_Status 0 "Disconnected" 1 "Connected" 2 "Connection in Progress" 3 "Disconnection in Progress" 4 "Reserved" 5 "Reserved" 6 "Error" 7 "Not Available";
VAL_ 2360461772 Pre_Charge_Ready 0 "Pre-Charge Not Ready" 1 "Pre-Charge Ready" 2 "Error" 3 "Not Available";
VAL_ 2360461773 Battery_Voltage 65533 "Saturated" 65534 "Error" 65535 "Not Available";
VAL_ 2360461773 HVDC_Bus_Voltage 65533 "Saturated" 65534 "Error" 65535 "Not Available";
VAL_ 2360461773 Current 65533 "Saturated" 65534 "Error" 65535 "Not Available";
VAL_ 2360461773 Operational_Status 0 "Initialization" 1 "Reserved" 2 "Operational" 3 "Keep Alive" 4 "Emergency Stop" 5 "Disabled" 6 "Fault" 7 "Periodic checkup" 8 "Reserved" 9 "Reserved" 10 "Reserved" 11 "Reserved" 12 "Reserved" 13 "Reserved" 14 "Error" 15 "Not Available";
VAL_ 2360461773 HVDC_Bus_Disconnect_Forewarning 0 "Disconnect not pending" 1 "Disconnect imminent due to batte" 2 "Disconnect imminent due to batte" 3 "Reserved" 4 "Reserved" 5 "Disconnect imminent due to cell " 6 "Disconnect imminent due to cell " 7 "Disconnect imminent due to batte" 8 "Reserved" 9 "Reserved" 10 "Reserved" 11 "Reserved" 12 "Reserved" 13 "Disconnect imminent - no reason " 14 "Error" 15 "Not Available";
VAL_ 2360461773 HVDC_Bus_Connection_Status 0 "Disconnected" 1 "Connected" 2 "Connection in Progress" 3 "Disconnection in Progress" 4 "Reserved" 5 "Reserved" 6 "Error" 7 "Not Available";
VAL_ 2360461773 Pre_Charge_Ready 0 "Pre-Charge Not Ready" 1 "Pre-Charge Ready" 2 "Error" 3 "Not Available";
VAL_ 2360461774 Battery_Voltage 65533 "Saturated" 65534 "Error" 65535 "Not Available";
VAL_ 2360461774 HVDC_Bus_Voltage 65533 "Saturated" 65534 "Error" 65535 "Not Available";
VAL_ 2360461774 Current 65533 "Saturated" 65534 "Error" 65535 "Not Available";
VAL_ 2360461774 Operational_Status 0 "Initialization" 1 "Reserved" 2 "Operational" 3 "Keep Alive" 4 "Emergency Stop" 5 "Disabled" 6 "Fault" 7 "Periodic checkup" 8 "Reserved" 9 "Reserved" 10 "Reserved" 11 "Reserved" 12 "Reserved" 13 "Reserved" 14 "Error" 15 "Not Available";
VAL_ 2360461774 HVDC_Bus_Disconnect_Forewarning 0 "Disconnect not pending" 1 "Disconnect imminent due to batte" 2 "Disconnect imminent due to batte" 3 "Reserved" 4 "Reserved" 5 "Disconnect imminent due to cell " 6 "Disconnect imminent due to cell " 7 "Disconnect imminent due to batte" 8 "Reserved" 9 "Reserved" 10 "Reserved" 11 "Reserved" 12 "Reserved" 13 "Disconnect imminent - no reason " 14 "Error" 15 "Not Available";
VAL_ 2360461774 HVDC_Bus_Connection_Status 0 "Disconnected" 1 "Connected" 2 "Connection in Progress" 3 "Disconnection in Progress" 4 "Reserved" 5 "Reserved" 6 "Error" 7 "Not Available";
VAL_ 2360461774 Pre_Charge_Ready 0 "Pre-Charge Not Ready" 1 "Pre-Charge Ready" 2 "Error" 3 "Not Available";
VAL_ 2360461775 Battery_Voltage 65533 "Saturated" 65534 "Error" 65535 "Not Available";
VAL_ 2360461775 HVDC_Bus_Voltage 65533 "Saturated" 65534 "Error" 65535 "Not Available";
VAL_ 2360461775 Current 65533 "Saturated" 65534 "Error" 65535 "Not Available";
VAL_ 2360461775 Operational_Status 0 "Initialization" 1 "Reserved" 2 "Operational" 3 "Keep Alive" 4 "Emergency Stop" 5 "Disabled" 6 "Fault" 7 "Periodic checkup" 8 "Reserved" 9 "Reserved" 10 "Reserved" 11 "Reserved" 12 "Reserved" 13 "Reserved" 14 "Error" 15 "Not Available";
VAL_ 2360461775 HVDC_Bus_Disconnect_Forewarning 0 "Disconnect not pending" 1 "Disconnect imminent due to batte" 2 "Disconnect imminent due to batte" 3 "Reserved" 4 "Reserved" 5 "Disconnect imminent due to cell " 6 "Disconnect imminent due to cell " 7 "Disconnect imminent due to batte" 8 "Reserved" 9 "Reserved" 10 "Reserved" 11 "Reserved" 12 "Reserved" 13 "Disconnect imminent - no reason " 14 "Error" 15 "Not Available";
VAL_ 2360461775 HVDC_Bus_Connection_Status 0 "Disconnected" 1 "Connected" 2 "Connection in Progress" 3 "Disconnection in Progress" 4 "Reserved" 5 "Reserved" 6 "Error" 7 "Not Available";
VAL_ 2360461775 Pre_Charge_Ready 0 "Pre-Charge Not Ready" 1 "Pre-Charge Ready" 2 "Error" 3 "Not Available";
VAL_ 2360461776 Battery_Voltage 65533 "Saturated" 65534 "Error" 65535 "Not Available";
VAL_ 2360461776 HVDC_Bus_Voltage 65533 "Saturated" 65534 "Error" 65535 "Not Available";
VAL_ 2360461776 Current 65533 "Saturated" 65534 "Error" 65535 "Not Available";
VAL_ 2360461776 Operational_Status 0 "Initialization" 1 "Reserved" 2 "Operational" 3 "Keep Alive" 4 "Emergency Stop" 5 "Disabled" 6 "Fault" 7 "Periodic checkup" 8 "Reserved" 9 "Reserved" 10 "Reserved" 11 "Reserved" 12 "Reserved" 13 "Reserved" 14 "Error" 15 "Not Available";
VAL_ 2360461776 HVDC_Bus_Disconnect_Forewarning 0 "Disconnect not pending" 1 "Disconnect imminent due to batte" 2 "Disconnect imminent due to batte" 3 "Reserved" 4 "Reserved" 5 "Disconnect imminent due to cell " 6 "Disconnect imminent due to cell " 7 "Disconnect imminent due to batte" 8 "Reserved" 9 "Reserved" 10 "Reserved" 11 "Reserved" 12 "Reserved" 13 "Disconnect imminent - no reason " 14 "Error" 15 "Not Available";
VAL_ 2360461776 HVDC_Bus_Connection_Status 0 "Disconnected" 1 "Connected" 2 "Connection in Progress" 3 "Disconnection in Progress" 4 "Reserved" 5 "Reserved" 6 "Error" 7 "Not Available";
VAL_ 2360461776 Pre_Charge_Ready 0 "Pre-Charge Not Ready" 1 "Pre-Charge Ready" 2 "Error" 3 "Not Available";
VAL_ 2360461777 Battery_Voltage 65533 "Saturated" 65534 "Error" 65535 "Not Available";
VAL_ 2360461777 HVDC_Bus_Voltage 65533 "Saturated" 65534 "Error" 65535 "Not Available";
VAL_ 2360461777 Current 65533 "Saturated" 65534 "Error" 65535 "Not Available";
VAL_ 2360461777 Operational_Status 0 "Initialization" 1 "Reserved" 2 "Operational" 3 "Keep Alive" 4 "Emergency Stop" 5 "Disabled" 6 "Fault" 7 "Periodic checkup" 8 "Reserved" 9 "Reserved" 10 "Reserved" 11 "Reserved" 12 "Reserved" 13 "Reserved" 14 "Error" 15 "Not Available";
VAL_ 2360461777 HVDC_Bus_Disconnect_Forewarning 0 "Disconnect not pending" 1 "Disconnect imminent due to batte" 2 "Disconnect imminent due to batte" 3 "Reserved" 4 "Reserved" 5 "Disconnect imminent due to cell " 6 "Disconnect imminent due to cell " 7 "Disconnect imminent due to batte" 8 "Reserved" 9 "Reserved" 10 "Reserved" 11 "Reserved" 12 "Reserved" 13 "Disconnect imminent - no reason " 14 "Error" 15 "Not Available";
VAL_ 2360461777 HVDC_Bus_Connection_Status 0 "Disconnected" 1 "Connected" 2 "Connection in Progress" 3 "Disconnection in Progress" 4 "Reserved" 5 "Reserved" 6 "Error" 7 "Not Available";
VAL_ 2360461777 Pre_Charge_Ready 0 "Pre-Charge Not Ready" 1 "Pre-Charge Ready" 2 "Error" 3 "Not Available";
VAL_ 2360461778 Battery_Voltage 65533 "Saturated" 65534 "Error" 65535 "Not Available";
VAL_ 2360461778 HVDC_Bus_Voltage 65533 "Saturated" 65534 "Error" 65535 "Not Available";
VAL_ 2360461778 Current 65533 "Saturated" 65534 "Error" 65535 "Not Available";
VAL_ 2360461778 Operational_Status 0 "Initialization" 1 "Reserved" 2 "Operational" 3 "Keep Alive" 4 "Emergency Stop" 5 "Disabled" 6 "Fault" 7 "Periodic checkup" 8 "Reserved" 9 "Reserved" 10 "Reserved" 11 "Reserved" 12 "Reserved" 13 "Reserved" 14 "Error" 15 "Not Available";
VAL_ 2360461778 HVDC_Bus_Disconnect_Forewarning 0 "Disconnect not pending" 1 "Disconnect imminent due to batte" 2 "Disconnect imminent due to batte" 3 "Reserved" 4 "Reserved" 5 "Disconnect imminent due to cell " 6 "Disconnect imminent due to cell " 7 "Disconnect imminent due to batte" 8 "Reserved" 9 "Reserved" 10 "Reserved" 11 "Reserved" 12 "Reserved" 13 "Disconnect imminent - no reason " 14 "Error" 15 "Not Available";
VAL_ 2360461778 HVDC_Bus_Connection_Status 0 "Disconnected" 1 "Connected" 2 "Connection in Progress" 3 "Disconnection in Progress" 4 "Reserved" 5 "Reserved" 6 "Error" 7 "Not Available";
VAL_ 2360461778 Pre_Charge_Ready 0 "Pre-Charge Not Ready" 1 "Pre-Charge Ready" 2 "Error" 3 "Not Available";
VAL_ 2360461779 Battery_Voltage 65533 "Saturated" 65534 "Error" 65535 "Not Available";
VAL_ 2360461779 HVDC_Bus_Voltage 65533 "Saturated" 65534 "Error" 65535 "Not Available";
VAL_ 2360461779 Current 65533 "Saturated" 65534 "Error" 65535 "Not Available";
VAL_ 2360461779 Operational_Status 0 "Initialization" 1 "Reserved" 2 "Operational" 3 "Keep Alive" 4 "Emergency Stop" 5 "Disabled" 6 "Fault" 7 "Periodic checkup" 8 "Reserved" 9 "Reserved" 10 "Reserved" 11 "Reserved" 12 "Reserved" 13 "Reserved" 14 "Error" 15 "Not Available";
VAL_ 2360461779 HVDC_Bus_Disconnect_Forewarning 0 "Disconnect not pending" 1 "Disconnect imminent due to batte" 2 "Disconnect imminent due to batte" 3 "Reserved" 4 "Reserved" 5 "Disconnect imminent due to cell " 6 "Disconnect imminent due to cell " 7 "Disconnect imminent due to batte" 8 "Reserved" 9 "Reserved" 10 "Reserved" 11 "Reserved" 12 "Reserved" 13 "Disconnect imminent - no reason " 14 "Error" 15 "Not Available";
VAL_ 2360461779 HVDC_Bus_Connection_Status 0 "Disconnected" 1 "Connected" 2 "Connection in Progress" 3 "Disconnection in Progress" 4 "Reserved" 5 "Reserved" 6 "Error" 7 "Not Available";
VAL_ 2360461779 Pre_Charge_Ready 0 "Pre-Charge Not Ready" 1 "Pre-Charge Ready" 2 "Error" 3 "Not Available";
VAL_ 2360461780 Battery_Voltage 65533 "Saturated" 65534 "Error" 65535 "Not Available";
VAL_ 2360461780 HVDC_Bus_Voltage 65533 "Saturated" 65534 "Error" 65535 "Not Available";
VAL_ 2360461780 Current 65533 "Saturated" 65534 "Error" 65535 "Not Available";
VAL_ 2360461780 Operational_Status 0 "Initialization" 1 "Reserved" 2 "Operational" 3 "Keep Alive" 4 "Emergency Stop" 5 "Disabled" 6 "Fault" 7 "Periodic checkup" 8 "Reserved" 9 "Reserved" 10 "Reserved" 11 "Reserved" 12 "Reserved" 13 "Reserved" 14 "Error" 15 "Not Available";
VAL_ 2360461780 HVDC_Bus_Disconnect_Forewarning 0 "Disconnect not pending" 1 "Disconnect imminent due to batte" 2 "Disconnect imminent due to batte" 3 "Reserved" 4 "Reserved" 5 "Disconnect imminent due to cell " 6 "Disconnect imminent due to cell " 7 "Disconnect imminent due to batte" 8 "Reserved" 9 "Reserved" 10 "Reserved" 11 "Reserved" 12 "Reserved" 13 "Disconnect imminent - no reason " 14 "Error" 15 "Not Available";
VAL_ 2360461780 HVDC_Bus_Connection_Status 0 "Disconnected" 1 "Connected" 2 "Connection in Progress" 3 "Disconnection in Progress" 4 "Reserved" 5 "Reserved" 6 "Error" 7 "Not Available";
VAL_ 2360461780 Pre_Charge_Ready 0 "Pre-Charge Not Ready" 1 "Pre-Charge Ready" 2 "Error" 3 "Not Available";
VAL_ 2360461781 Battery_Voltage 65533 "Saturated" 65534 "Error" 65535 "Not Available";
VAL_ 2360461781 HVDC_Bus_Voltage 65533 "Saturated" 65534 "Error" 65535 "Not Available";
VAL_ 2360461781 Current 65533 "Saturated" 65534 "Error" 65535 "Not Available";
VAL_ 2360461781 Operational_Status 0 "Initialization" 1 "Reserved" 2 "Operational" 3 "Keep Alive" 4 "Emergency Stop" 5 "Disabled" 6 "Fault" 7 "Periodic checkup" 8 "Reserved" 9 "Reserved" 10 "Reserved" 11 "Reserved" 12 "Reserved" 13 "Reserved" 14 "Error" 15 "Not Available";
VAL_ 2360461781 HVDC_Bus_Disconnect_Forewarning 0 "Disconnect not pending" 1 "Disconnect imminent due to batte" 2 "Disconnect imminent due to batte" 3 "Reserved" 4 "Reserved" 5 "Disconnect imminent due to cell " 6 "Disconnect imminent due to cell " 7 "Disconnect imminent due to batte" 8 "Reserved" 9 "Reserved" 10 "Reserved" 11 "Reserved" 12 "Reserved" 13 "Disconnect imminent - no reason " 14 "Error" 15 "Not Available";
VAL_ 2360461781 HVDC_Bus_Connection_Status 0 "Disconnected" 1 "Connected" 2 "Connection in Progress" 3 "Disconnection in Progress" 4 "Reserved" 5 "Reserved" 6 "Error" 7 "Not Available";
VAL_ 2360461781 Pre_Charge_Ready 0 "Pre-Charge Not Ready" 1 "Pre-Charge Ready" 2 "Error" 3 "Not Available";
VAL_ 2360461782 Battery_Voltage 65533 "Saturated" 65534 "Error" 65535 "Not Available";
VAL_ 2360461782 HVDC_Bus_Voltage 65533 "Saturated" 65534 "Error" 65535 "Not Available";
VAL_ 2360461782 Current 65533 "Saturated" 65534 "Error" 65535 "Not Available";
VAL_ 2360461782 Operational_Status 0 "Initialization" 1 "Reserved" 2 "Operational" 3 "Keep Alive" 4 "Emergency Stop" 5 "Disabled" 6 "Fault" 7 "Periodic checkup" 8 "Reserved" 9 "Reserved" 10 "Reserved" 11 "Reserved" 12 "Reserved" 13 "Reserved" 14 "Error" 15 "Not Available";
VAL_ 2360461782 HVDC_Bus_Disconnect_Forewarning 0 "Disconnect not pending" 1 "Disconnect imminent due to batte" 2 "Disconnect imminent due to batte" 3 "Reserved" 4 "Reserved" 5 "Disconnect imminent due to cell " 6 "Disconnect imminent due to cell " 7 "Disconnect imminent due to batte" 8 "Reserved" 9 "Reserved" 10 "Reserved" 11 "Reserved" 12 "Reserved" 13 "Disconnect imminent - no reason " 14 "Error" 15 "Not Available";
VAL_ 2360461782 HVDC_Bus_Connection_Status 0 "Disconnected" 1 "Connected" 2 "Connection in Progress" 3 "Disconnection in Progress" 4 "Reserved" 5 "Reserved" 6 "Error" 7 "Not Available";
VAL_ 2360461782 Pre_Charge_Ready 0 "Pre-Charge Not Ready" 1 "Pre-Charge Ready" 2 "Error" 3 "Not Available";
VAL_ 2360461783 Battery_Voltage 65533 "Saturated" 65534 "Error" 65535 "Not Available";
VAL_ 2360461783 HVDC_Bus_Voltage 65533 "Saturated" 65534 "Error" 65535 "Not Available";
VAL_ 2360461783 Current 65533 "Saturated" 65534 "Error" 65535 "Not Available";
VAL_ 2360461783 Operational_Status 0 "Initialization" 1 "Reserved" 2 "Operational" 3 "Keep Alive" 4 "Emergency Stop" 5 "Disabled" 6 "Fault" 7 "Periodic checkup" 8 "Reserved" 9 "Reserved" 10 "Reserved" 11 "Reserved" 12 "Reserved" 13 "Reserved" 14 "Error" 15 "Not Available";
VAL_ 2360461783 HVDC_Bus_Disconnect_Forewarning 0 "Disconnect not pending" 1 "Disconnect imminent due to batte" 2 "Disconnect imminent due to batte" 3 "Reserved" 4 "Reserved" 5 "Disconnect imminent due to cell " 6 "Disconnect imminent due to cell " 7 "Disconnect imminent due to batte" 8 "Reserved" 9 "Reserved" 10 "Reserved" 11 "Reserved" 12 "Reserved" 13 "Disconnect imminent - no reason " 14 "Error" 15 "Not Available";
VAL_ 2360461783 HVDC_Bus_Connection_Status 0 "Disconnected" 1 "Connected" 2 "Connection in Progress" 3 "Disconnection in Progress" 4 "Reserved" 5 "Reserved" 6 "Error" 7 "Not Available";
VAL_ 2360461783 Pre_Charge_Ready 0 "Pre-Charge Not Ready" 1 "Pre-Charge Ready" 2 "Error" 3 "Not Available";
VAL_ 2360461784 Battery_Voltage 65533 "Saturated" 65534 "Error" 65535 "Not Available";
VAL_ 2360461784 HVDC_Bus_Voltage 65533 "Saturated" 65534 "Error" 65535 "Not Available";
VAL_ 2360461784 Current 65533 "Saturated" 65534 "Error" 65535 "Not Available";
VAL_ 2360461784 Operational_Status 0 "Initialization" 1 "Reserved" 2 "Operational" 3 "Keep Alive" 4 "Emergency Stop" 5 "Disabled" 6 "Fault" 7 "Periodic checkup" 8 "Reserved" 9 "Reserved" 10 "Reserved" 11 "Reserved" 12 "Reserved" 13 "Reserved" 14 "Error" 15 "Not Available";
VAL_ 2360461784 HVDC_Bus_Disconnect_Forewarning 0 "Disconnect not pending" 1 "Disconnect imminent due to batte" 2 "Disconnect imminent due to batte" 3 "Reserved" 4 "Reserved" 5 "Disconnect imminent due to cell " 6 "Disconnect imminent due to cell " 7 "Disconnect imminent due to batte" 8 "Reserved" 9 "Reserved" 10 "Reserved" 11 "Reserved" 12 "Reserved" 13 "Disconnect imminent - no reason " 14 "Error" 15 "Not Available";
VAL_ 2360461784 HVDC_Bus_Connection_Status 0 "Disconnected" 1 "Connected" 2 "Connection in Progress" 3 "Disconnection in Progress" 4 "Reserved" 5 "Reserved" 6 "Error" 7 "Not Available";
VAL_ 2360461784 Pre_Charge_Ready 0 "Pre-Charge Not Ready" 1 "Pre-Charge Ready" 2 "Error" 3 "Not Available";
VAL_ 2360527305 Available_Charge_Power 4093 "Saturated" 4094 "Error" 4095 "Not Available";
VAL_ 2360527305 Available_Discharge_Power 4093 "Saturated" 4094 "Error" 4095 "Not Available";
VAL_ 2360527305 Available_High_Charge_Power 4093 "Saturated" 4094 "Error" 4095 "Not Available";
VAL_ 2360527305 Available_High_Discharge_Power 4093 "Saturated" 4094 "Error" 4095 "Not Available";
VAL_ 2360527305 Instantaneous_Power 8189 "Saturated" 8190 "Error" 8191 "Not Available";
VAL_ 2360527306 Available_Charge_Power 4093 "Saturated" 4094 "Error" 4095 "Not Available";
VAL_ 2360527306 Available_Discharge_Power 4093 "Saturated" 4094 "Error" 4095 "Not Available";
VAL_ 2360527306 Available_High_Charge_Power 4093 "Saturated" 4094 "Error" 4095 "Not Available";
VAL_ 2360527306 Available_High_Discharge_Power 4093 "Saturated" 4094 "Error" 4095 "Not Available";
VAL_ 2360527306 Instantaneous_Power 8189 "Saturated" 8190 "Error" 8191 "Not Available";
VAL_ 2360527307 Available_Charge_Power 4093 "Saturated" 4094 "Error" 4095 "Not Available";
VAL_ 2360527307 Available_Discharge_Power 4093 "Saturated" 4094 "Error" 4095 "Not Available";
VAL_ 2360527307 Available_High_Charge_Power 4093 "Saturated" 4094 "Error" 4095 "Not Available";
VAL_ 2360527307 Available_High_Discharge_Power 4093 "Saturated" 4094 "Error" 4095 "Not Available";
VAL_ 2360527307 Instantaneous_Power 8189 "Saturated" 8190 "Error" 8191 "Not Available";
VAL_ 2360527308 Available_Charge_Power 4093 "Saturated" 4094 "Error" 4095 "Not Available";
VAL_ 2360527308 Available_Discharge_Power 4093 "Saturated" 4094 "Error" 4095 "Not Available";
VAL_ 2360527308 Available_High_Charge_Power 4093 "Saturated" 4094 "Error" 4095 "Not Available";
VAL_ 2360527308 Available_High_Discharge_Power 4093 "Saturated" 4094 "Error" 4095 "Not Available";
VAL_ 2360527308 Instantaneous_Power 8189 "Saturated" 8190 "Error" 8191 "Not Available";
VAL_ 2360527309 Available_Charge_Power 4093 "Saturated" 4094 "Error" 4095 "Not Available";
VAL_ 2360527309 Available_Discharge_Power 4093 "Saturated" 4094 "Error" 4095 "Not Available";
VAL_ 2360527309 Available_High_Charge_Power 4093 "Saturated" 4094 "Error" 4095 "Not Available";
VAL_ 2360527309 Available_High_Discharge_Power 4093 "Saturated" 4094 "Error" 4095 "Not Available";
VAL_ 2360527309 Instantaneous_Power 8189 "Saturated" 8190 "Error" 8191 "Not Available";
VAL_ 2360527310 Available_Charge_Power 4093 "Saturated" 4094 "Error" 4095 "Not Available";
VAL_ 2360527310 Available_Discharge_Power 4093 "Saturated" 4094 "Error" 4095 "Not Available";
VAL_ 2360527310 Available_High_Charge_Power 4093 "Saturated" 4094 "Error" 4095 "Not Available";
VAL_ 2360527310 Available_High_Discharge_Power 4093 "Saturated" 4094 "Error" 4095 "Not Available";
VAL_ 2360527310 Instantaneous_Power 8189 "Saturated" 8190 "Error" 8191 "Not Available";
VAL_ 2360527311 Available_Charge_Power 4093 "Saturated" 4094 "Error" 4095 "Not Available";
VAL_ 2360527311 Available_Discharge_Power 4093 "Saturated" 4094 "Error" 4095 "Not Available";
VAL_ 2360527311 Available_High_Charge_Power 4093 "Saturated" 4094 "Error" 4095 "Not Available";
VAL_ 2360527311 Available_High_Discharge_Power 4093 "Saturated" 4094 "Error" 4095 "Not Available";
VAL_ 2360527311 Instantaneous_Power 8189 "Saturated" 8190 "Error" 8191 "Not Available";
VAL_ 2360527312 Available_Charge_Power 4093 "Saturated" 4094 "Error" 4095 "Not Available";
VAL_ 2360527312 Available_Discharge_Power 4093 "Saturated" 4094 "Error" 4095 "Not Available";
VAL_ 2360527312 Available_High_Charge_Power 4093 "Saturated" 4094 "Error" 4095 "Not Available";
VAL_ 2360527312 Available_High_Discharge_Power 4093 "Saturated" 4094 "Error" 4095 "Not Available";
VAL_ 2360527312 Instantaneous_Power 8189 "Saturated" 8190 "Error" 8191 "Not Available";
VAL_ 2360527313 Available_Charge_Power 4093 "Saturated" 4094 "Error" 4095 "Not Available";
VAL_ 2360527313 Available_Discharge_Power 4093 "Saturated" 4094 "Error" 4095 "Not Available";
VAL_ 2360527313 Available_High_Charge_Power 4093 "Saturated" 4094 "Error" 4095 "Not Available";
VAL_ 2360527313 Available_High_Discharge_Power 4093 "Saturated" 4094 "Error" 4095 "Not Available";
VAL_ 2360527313 Instantaneous_Power 8189 "Saturated" 8190 "Error" 8191 "Not Available";
VAL_ 2360527314 Available_Charge_Power 4093 "Saturated" 4094 "Error" 4095 "Not Available";
VAL_ 2360527314 Available_Discharge_Power 4093 "Saturated" 4094 "Error" 4095 "Not Available";
VAL_ 2360527314 Available_High_Charge_Power 4093 "Saturated" 4094 "Error" 4095 "Not Available";
VAL_ 2360527314 Available_High_Discharge_Power 4093 "Saturated" 4094 "Error" 4095 "Not Available";
VAL_ 2360527314 Instantaneous_Power 8189 "Saturated" 8190 "Error" 8191 "Not Available";
VAL_ 2360527315 Available_Charge_Power 4093 "Saturated" 4094 "Error" 4095 "Not Available";
VAL_ 2360527315 Available_Discharge_Power 4093 "Saturated" 4094 "Error" 4095 "Not Available";
VAL_ 2360527315 Available_High_Charge_Power 4093 "Saturated" 4094 "Error" 4095 "Not Available";
VAL_ 2360527315 Available_High_Discharge_Power 4093 "Saturated" 4094 "Error" 4095 "Not Available";
VAL_ 2360527315 Instantaneous_Power 8189 "Saturated" 8190 "Error" 8191 "Not Available";
VAL_ 2360527316 Available_Charge_Power 4093 "Saturated" 4094 "Error" 4095 "Not Available";
VAL_ 2360527316 Available_Discharge_Power 4093 "Saturated" 4094 "Error" 4095 "Not Available";
VAL_ 2360527316 Available_High_Charge_Power 4093 "Saturated" 4094 "Error" 4095 "Not Available";
VAL_ 2360527316 Available_High_Discharge_Power 4093 "Saturated" 4094 "Error" 4095 "Not Available";
VAL_ 2360527316 Instantaneous_Power 8189 "Saturated" 8190 "Error" 8191 "Not Available";
VAL_ 2360527317 Available_Charge_Power 4093 "Saturated" 4094 "Error" 4095 "Not Available";
VAL_ 2360527317 Available_Discharge_Power 4093 "Saturated" 4094 "Error" 4095 "Not Available";
VAL_ 2360527317 Available_High_Charge_Power 4093 "Saturated" 4094 "Error" 4095 "Not Available";
VAL_ 2360527317 Available_High_Discharge_Power 4093 "Saturated" 4094 "Error" 4095 "Not Available";
VAL_ 2360527317 Instantaneous_Power 8189 "Saturated" 8190 "Error" 8191 "Not Available";
VAL_ 2360527318 Available_Charge_Power 4093 "Saturated" 4094 "Error" 4095 "Not Available";
VAL_ 2360527318 Available_Discharge_Power 4093 "Saturated" 4094 "Error" 4095 "Not Available";
VAL_ 2360527318 Available_High_Charge_Power 4093 "Saturated" 4094 "Error" 4095 "Not Available";
VAL_ 2360527318 Available_High_Discharge_Power 4093 "Saturated" 4094 "Error" 4095 "Not Available";
VAL_ 2360527318 Instantaneous_Power 8189 "Saturated" 8190 "Error" 8191 "Not Available";
VAL_ 2360527319 Available_Charge_Power 4093 "Saturated" 4094 "Error" 4095 "Not Available";
VAL_ 2360527319 Available_Discharge_Power 4093 "Saturated" 4094 "Error" 4095 "Not Available";
VAL_ 2360527319 Available_High_Charge_Power 4093 "Saturated" 4094 "Error" 4095 "Not Available";
VAL_ 2360527319 Available_High_Discharge_Power 4093 "Saturated" 4094 "Error" 4095 "Not Available";
VAL_ 2360527319 Instantaneous_Power 8189 "Saturated" 8190 "Error" 8191 "Not Available";
VAL_ 2360527320 Available_Charge_Power 4093 "Saturated" 4094 "Error" 4095 "Not Available";
VAL_ 2360527320 Available_Discharge_Power 4093 "Saturated" 4094 "Error" 4095 "Not Available";
VAL_ 2360527320 Available_High_Charge_Power 4093 "Saturated" 4094 "Error" 4095 "Not Available";
VAL_ 2360527320 Available_High_Discharge_Power 4093 "Saturated" 4094 "Error" 4095 "Not Available";
VAL_ 2360527320 Instantaneous_Power 8189 "Saturated" 8190 "Error" 8191 "Not Available";
VAL_ 2360592841 Lowest_Cell_Voltage 8189 "Saturated" 8190 "Error" 8191 "Not Available";
VAL_ 2360592841 Highest_Cell_Voltage 8189 "Saturated" 8190 "Error" 8191 "Not Available";
VAL_ 2360592841 Lowest_Cell_Temperature 2045 "Saturated" 2046 "Error" 2047 "Not Available";
VAL_ 2360592841 Highest_Cell_Temperature 2045 "Saturated" 2046 "Error" 2047 "Not Available";
VAL_ 2360592841 Battery_Isolation 65533 "Saturated" 65534 "Error" 65535 "Not Available";
VAL_ 2360592842 Lowest_Cell_Voltage 8189 "Saturated" 8190 "Error" 8191 "Not Available";
VAL_ 2360592842 Highest_Cell_Voltage 8189 "Saturated" 8190 "Error" 8191 "Not Available";
VAL_ 2360592842 Lowest_Cell_Temperature 2045 "Saturated" 2046 "Error" 2047 "Not Available";
VAL_ 2360592842 Highest_Cell_Temperature 2045 "Saturated" 2046 "Error" 2047 "Not Available";
VAL_ 2360592842 Battery_Isolation 65533 "Saturated" 65534 "Error" 65535 "Not Available";
VAL_ 2360592843 Lowest_Cell_Voltage 8189 "Saturated" 8190 "Error" 8191 "Not Available";
VAL_ 2360592843 Highest_Cell_Voltage 8189 "Saturated" 8190 "Error" 8191 "Not Available";
VAL_ 2360592843 Lowest_Cell_Temperature 2045 "Saturated" 2046 "Error" 2047 "Not Available";
VAL_ 2360592843 Highest_Cell_Temperature 2045 "Saturated" 2046 "Error" 2047 "Not Available";
VAL_ 2360592843 Battery_Isolation 65533 "Saturated" 65534 "Error" 65535 "Not Available";
VAL_ 2360592844 Lowest_Cell_Voltage 8189 "Saturated" 8190 "Error" 8191 "Not Available";
VAL_ 2360592844 Highest_Cell_Voltage 8189 "Saturated" 8190 "Error" 8191 "Not Available";
VAL_ 2360592844 Lowest_Cell_Temperature 2045 "Saturated" 2046 "Error" 2047 "Not Available";
VAL_ 2360592844 Highest_Cell_Temperature 2045 "Saturated" 2046 "Error" 2047 "Not Available";
VAL_ 2360592844 Battery_Isolation 65533 "Saturated" 65534 "Error" 65535 "Not Available";
VAL_ 2360592845 Lowest_Cell_Voltage 8189 "Saturated" 8190 "Error" 8191 "Not Available";
VAL_ 2360592845 Highest_Cell_Voltage 8189 "Saturated" 8190 "Error" 8191 "Not Available";
VAL_ 2360592845 Lowest_Cell_Temperature 2045 "Saturated" 2046 "Error" 2047 "Not Available";
VAL_ 2360592845 Highest_Cell_Temperature 2045 "Saturated" 2046 "Error" 2047 "Not Available";
VAL_ 2360592845 Battery_Isolation 65533 "Saturated" 65534 "Error" 65535 "Not Available";
VAL_ 2360592846 Lowest_Cell_Voltage 8189 "Saturated" 8190 "Error" 8191 "Not Available";
VAL_ 2360592846 Highest_Cell_Voltage 8189 "Saturated" 8190 "Error" 8191 "Not Available";
VAL_ 2360592846 Lowest_Cell_Temperature 2045 "Saturated" 2046 "Error" 2047 "Not Available";
VAL_ 2360592846 Highest_Cell_Temperature 2045 "Saturated" 2046 "Error" 2047 "Not Available";
VAL_ 2360592846 Battery_Isolation 65533 "Saturated" 65534 "Error" 65535 "Not Available";
VAL_ 2360592847 Lowest_Cell_Voltage 8189 "Saturated" 8190 "Error" 8191 "Not Available";
VAL_ 2360592847 Highest_Cell_Voltage 8189 "Saturated" 8190 "Error" 8191 "Not Available";
VAL_ 2360592847 Lowest_Cell_Temperature 2045 "Saturated" 2046 "Error" 2047 "Not Available";
VAL_ 2360592847 Highest_Cell_Temperature 2045 "Saturated" 2046 "Error" 2047 "Not Available";
VAL_ 2360592847 Battery_Isolation 65533 "Saturated" 65534 "Error" 65535 "Not Available";
VAL_ 2360592848 Lowest_Cell_Voltage 8189 "Saturated" 8190 "Error" 8191 "Not Available";
VAL_ 2360592848 Highest_Cell_Voltage 8189 "Saturated" 8190 "Error" 8191 "Not Available";
VAL_ 2360592848 Lowest_Cell_Temperature 2045 "Saturated" 2046 "Error" 2047 "Not Available";
VAL_ 2360592848 Highest_Cell_Temperature 2045 "Saturated" 2046 "Error" 2047 "Not Available";
VAL_ 2360592848 Battery_Isolation 65533 "Saturated" 65534 "Error" 65535 "Not Available";
VAL_ 2360592849 Lowest_Cell_Voltage 8189 "Saturated" 8190 "Error" 8191 "Not Available";
VAL_ 2360592849 Highest_Cell_Voltage 8189 "Saturated" 8190 "Error" 8191 "Not Available";
VAL_ 2360592849 Lowest_Cell_Temperature 2045 "Saturated" 2046 "Error" 2047 "Not Available";
VAL_ 2360592849 Highest_Cell_Temperature 2045 "Saturated" 2046 "Error" 2047 "Not Available";
VAL_ 2360592849 Battery_Isolation 65533 "Saturated" 65534 "Error" 65535 "Not Available";
VAL_ 2360592850 Lowest_Cell_Voltage 8189 "Saturated" 8190 "Error" 8191 "Not Available";
VAL_ 2360592850 Highest_Cell_Voltage 8189 "Saturated" 8190 "Error" 8191 "Not Available";
VAL_ 2360592850 Lowest_Cell_Temperature 2045 "Saturated" 2046 "Error" 2047 "Not Available";
VAL_ 2360592850 Highest_Cell_Temperature 2045 "Saturated" 2046 "Error" 2047 "Not Available";
VAL_ 2360592850 Battery_Isolation 65533 "Saturated" 65534 "Error" 65535 "Not Available";
VAL_ 2360592851 Lowest_Cell_Voltage 8189 "Saturated" 8190 "Error" 8191 "Not Available";
VAL_ 2360592851 Highest_Cell_Voltage 8189 "Saturated" 8190 "Error" 8191 "Not Available";
VAL_ 2360592851 Lowest_Cell_Temperature 2045 "Saturated" 2046 "Error" 2047 "Not Available";
VAL_ 2360592851 Highest_Cell_Temperature 2045 "Saturated" 2046 "Error" 2047 "Not Available";
VAL_ 2360592851 Battery_Isolation 65533 "Saturated" 65534 "Error" 65535 "Not Available";
VAL_ 2360592852 Lowest_Cell_Voltage 8189 "Saturated" 8190 "Error" 8191 "Not Available";
VAL_ 2360592852 Highest_Cell_Voltage 8189 "Saturated" 8190 "Error" 8191 "Not Available";
VAL_ 2360592852 Lowest_Cell_Temperature 2045 "Saturated" 2046 "Error" 2047 "Not Available";
VAL_ 2360592852 Highest_Cell_Temperature 2045 "Saturated" 2046 "Error" 2047 "Not Available";
VAL_ 2360592852 Battery_Isolation 65533 "Saturated" 65534 "Error" 65535 "Not Available";
VAL_ 2360592853 Lowest_Cell_Voltage 8189 "Saturated" 8190 "Error" 8191 "Not Available";
VAL_ 2360592853 Highest_Cell_Voltage 8189 "Saturated" 8190 "Error" 8191 "Not Available";
VAL_ 2360592853 Lowest_Cell_Temperature 2045 "Saturated" 2046 "Error" 2047 "Not Available";
VAL_ 2360592853 Highest_Cell_Temperature 2045 "Saturated" 2046 "Error" 2047 "Not Available";
VAL_ 2360592853 Battery_Isolation 65533 "Saturated" 65534 "Error" 65535 "Not Available";
VAL_ 2360592854 Lowest_Cell_Voltage 8189 "Saturated" 8190 "Error" 8191 "Not Available";
VAL_ 2360592854 Highest_Cell_Voltage 8189 "Saturated" 8190 "Error" 8191 "Not Available";
VAL_ 2360592854 Lowest_Cell_Temperature 2045 "Saturated" 2046 "Error" 2047 "Not Available";
VAL_ 2360592854 Highest_Cell_Temperature 2045 "Saturated" 2046 "Error" 2047 "Not Available";
VAL_ 2360592854 Battery_Isolation 65533 "Saturated" 65534 "Error" 65535 "Not Available";
VAL_ 2360592855 Lowest_Cell_Voltage 8189 "Saturated" 8190 "Error" 8191 "Not Available";
VAL_ 2360592855 Highest_Cell_Voltage 8189 "Saturated" 8190 "Error" 8191 "Not Available";
VAL_ 2360592855 Lowest_Cell_Temperature 2045 "Saturated" 2046 "Error" 2047 "Not Available";
VAL_ 2360592855 Highest_Cell_Temperature 2045 "Saturated" 2046 "Error" 2047 "Not Available";
VAL_ 2360592855 Battery_Isolation 65533 "Saturated" 65534 "Error" 65535 "Not Available";
VAL_ 2360592856 Lowest_Cell_Voltage 8189 "Saturated" 8190 "Error" 8191 "Not Available";
VAL_ 2360592856 Highest_Cell_Voltage 8189 "Saturated" 8190 "Error" 8191 "Not Available";
VAL_ 2360592856 Lowest_Cell_Temperature 2045 "Saturated" 2046 "Error" 2047 "Not Available";
VAL_ 2360592856 Highest_Cell_Temperature 2045 "Saturated" 2046 "Error" 2047 "Not Available";
VAL_ 2360592856 Battery_Isolation 65533 "Saturated" 65534 "Error" 65535 "Not Available";
VAL_ 2360658377 Lowest_Cell_State_of_Charge 1021 "Saturated" 1022 "Error" 1023 "Not Available";
VAL_ 2360658377 Highest_Cell_State_of_Charge 1021 "Saturated" 1022 "Error" 1023 "Not Available";
VAL_ 2360658377 Charge_Capacity 1021 "Saturated" 1022 "Error" 1023 "Not Available";
VAL_ 2360658377 Discharge_Capacity 1021 "Saturated" 1022 "Error" 1023 "Not Available";
VAL_ 2360658377 Estimated_Charge_Time_Remaining 16381 "Saturated" 16382 "Error" 16383 "Not Available";
VAL_ 2360658378 Lowest_Cell_State_of_Charge 1021 "Saturated" 1022 "Error" 1023 "Not Available";
VAL_ 2360658378 Highest_Cell_State_of_Charge 1021 "Saturated" 1022 "Error" 1023 "Not Available";
VAL_ 2360658378 Charge_Capacity 1021 "Saturated" 1022 "Error" 1023 "Not Available";
VAL_ 2360658378 Discharge_Capacity 1021 "Saturated" 1022 "Error" 1023 "Not Available";
VAL_ 2360658378 Estimated_Charge_Time_Remaining 16381 "Saturated" 16382 "Error" 16383 "Not Available";
VAL_ 2360658379 Lowest_Cell_State_of_Charge 1021 "Saturated" 1022 "Error" 1023 "Not Available";
VAL_ 2360658379 Highest_Cell_State_of_Charge 1021 "Saturated" 1022 "Error" 1023 "Not Available";
VAL_ 2360658379 Charge_Capacity 1021 "Saturated" 1022 "Error" 1023 "Not Available";
VAL_ 2360658379 Discharge_Capacity 1021 "Saturated" 1022 "Error" 1023 "Not Available";
VAL_ 2360658379 Estimated_Charge_Time_Remaining 16381 "Saturated" 16382 "Error" 16383 "Not Available";
VAL_ 2360658380 Lowest_Cell_State_of_Charge 1021 "Saturated" 1022 "Error" 1023 "Not Available";
VAL_ 2360658380 Highest_Cell_State_of_Charge 1021 "Saturated" 1022 "Error" 1023 "Not Available";
VAL_ 2360658380 Charge_Capacity 1021 "Saturated" 1022 "Error" 1023 "Not Available";
VAL_ 2360658380 Discharge_Capacity 1021 "Saturated" 1022 "Error" 1023 "Not Available";
VAL_ 2360658380 Estimated_Charge_Time_Remaining 16381 "Saturated" 16382 "Error" 16383 "Not Available";
VAL_ 2360658381 Lowest_Cell_State_of_Charge 1021 "Saturated" 1022 "Error" 1023 "Not Available";
VAL_ 2360658381 Highest_Cell_State_of_Charge 1021 "Saturated" 1022 "Error" 1023 "Not Available";
VAL_ 2360658381 Charge_Capacity 1021 "Saturated" 1022 "Error" 1023 "Not Available";
VAL_ 2360658381 Discharge_Capacity 1021 "Saturated" 1022 "Error" 1023 "Not Available";
VAL_ 2360658381 Estimated_Charge_Time_Remaining 16381 "Saturated" 16382 "Error" 16383 "Not Available";
VAL_ 2360658382 Lowest_Cell_State_of_Charge 1021 "Saturated" 1022 "Error" 1023 "Not Available";
VAL_ 2360658382 Highest_Cell_State_of_Charge 1021 "Saturated" 1022 "Error" 1023 "Not Available";
VAL_ 2360658382 Charge_Capacity 1021 "Saturated" 1022 "Error" 1023 "Not Available";
VAL_ 2360658382 Discharge_Capacity 1021 "Saturated" 1022 "Error" 1023 "Not Available";
VAL_ 2360658382 Estimated_Charge_Time_Remaining 16381 "Saturated" 16382 "Error" 16383 "Not Available";
VAL_ 2360658383 Lowest_Cell_State_of_Charge 1021 "Saturated" 1022 "Error" 1023 "Not Available";
VAL_ 2360658383 Highest_Cell_State_of_Charge 1021 "Saturated" 1022 "Error" 1023 "Not Available";
VAL_ 2360658383 Charge_Capacity 1021 "Saturated" 1022 "Error" 1023 "Not Available";
VAL_ 2360658383 Discharge_Capacity 1021 "Saturated" 1022 "Error" 1023 "Not Available";
VAL_ 2360658383 Estimated_Charge_Time_Remaining 16381 "Saturated" 16382 "Error" 16383 "Not Available";
VAL_ 2360658384 Lowest_Cell_State_of_Charge 1021 "Saturated" 1022 "Error" 1023 "Not Available";
VAL_ 2360658384 Highest_Cell_State_of_Charge 1021 "Saturated" 1022 "Error" 1023 "Not Available";
VAL_ 2360658384 Charge_Capacity 1021 "Saturated" 1022 "Error" 1023 "Not Available";
VAL_ 2360658384 Discharge_Capacity 1021 "Saturated" 1022 "Error" 1023 "Not Available";
VAL_ 2360658384 Estimated_Charge_Time_Remaining 16381 "Saturated" 16382 "Error" 16383 "Not Available";
VAL_ 2360658385 Lowest_Cell_State_of_Charge 1021 "Saturated" 1022 "Error" 1023 "Not Available";
VAL_ 2360658385 Highest_Cell_State_of_Charge 1021 "Saturated" 1022 "Error" 1023 "Not Available";
VAL_ 2360658385 Charge_Capacity 1021 "Saturated" 1022 "Error" 1023 "Not Available";
VAL_ 2360658385 Discharge_Capacity 1021 "Saturated" 1022 "Error" 1023 "Not Available";
VAL_ 2360658385 Estimated_Charge_Time_Remaining 16381 "Saturated" 16382 "Error" 16383 "Not Available";
VAL_ 2360658386 Lowest_Cell_State_of_Charge 1021 "Saturated" 1022 "Error" 1023 "Not Available";
VAL_ 2360658386 Highest_Cell_State_of_Charge 1021 "Saturated" 1022 "Error" 1023 "Not Available";
VAL_ 2360658386 Charge_Capacity 1021 "Saturated" 1022 "Error" 1023 "Not Available";
VAL_ 2360658386 Discharge_Capacity 1021 "Saturated" 1022 "Error" 1023 "Not Available";
VAL_ 2360658386 Estimated_Charge_Time_Remaining 16381 "Saturated" 16382 "Error" 16383 "Not Available";
VAL_ 2360658387 Lowest_Cell_State_of_Charge 1021 "Saturated" 1022 "Error" 1023 "Not Available";
VAL_ 2360658387 Highest_Cell_State_of_Charge 1021 "Saturated" 1022 "Error" 1023 "Not Available";
VAL_ 2360658387 Charge_Capacity 1021 "Saturated" 1022 "Error" 1023 "Not Available";
VAL_ 2360658387 Discharge_Capacity 1021 "Saturated" 1022 "Error" 1023 "Not Available";
VAL_ 2360658387 Estimated_Charge_Time_Remaining 16381 "Saturated" 16382 "Error" 16383 "Not Available";
VAL_ 2360658388 Lowest_Cell_State_of_Charge 1021 "Saturated" 1022 "Error" 1023 "Not Available";
VAL_ 2360658388 Highest_Cell_State_of_Charge 1021 "Saturated" 1022 "Error" 1023 "Not Available";
VAL_ 2360658388 Charge_Capacity 1021 "Saturated" 1022 "Error" 1023 "Not Available";
VAL_ 2360658388 Discharge_Capacity 1021 "Saturated" 1022 "Error" 1023 "Not Available";
VAL_ 2360658388 Estimated_Charge_Time_Remaining 16381 "Saturated" 16382 "Error" 16383 "Not Available";
VAL_ 2360658389 Lowest_Cell_State_of_Charge 1021 "Saturated" 1022 "Error" 1023 "Not Available";
VAL_ 2360658389 Highest_Cell_State_of_Charge 1021 "Saturated" 1022 "Error" 1023 "Not Available";
VAL_ 2360658389 Charge_Capacity 1021 "Saturated" 1022 "Error" 1023 "Not Available";
VAL_ 2360658389 Discharge_Capacity 1021 "Saturated" 1022 "Error" 1023 "Not Available";
VAL_ 2360658389 Estimated_Charge_Time_Remaining 16381 "Saturated" 16382 "Error" 16383 "Not Available";
VAL_ 2360658390 Lowest_Cell_State_of_Charge 1021 "Saturated" 1022 "Error" 1023 "Not Available";
VAL_ 2360658390 Highest_Cell_State_of_Charge 1021 "Saturated" 1022 "Error" 1023 "Not Available";
VAL_ 2360658390 Charge_Capacity 1021 "Saturated" 1022 "Error" 1023 "Not Available";
VAL_ 2360658390 Discharge_Capacity 1021 "Saturated" 1022 "Error" 1023 "Not Available";
VAL_ 2360658390 Estimated_Charge_Time_Remaining 16381 "Saturated" 16382 "Error" 16383 "Not Available";
VAL_ 2360658391 Lowest_Cell_State_of_Charge 1021 "Saturated" 1022 "Error" 1023 "Not Available";
VAL_ 2360658391 Highest_Cell_State_of_Charge 1021 "Saturated" 1022 "Error" 1023 "Not Available";
VAL_ 2360658391 Charge_Capacity 1021 "Saturated" 1022 "Error" 1023 "Not Available";
VAL_ 2360658391 Discharge_Capacity 1021 "Saturated" 1022 "Error" 1023 "Not Available";
VAL_ 2360658391 Estimated_Charge_Time_Remaining 16381 "Saturated" 16382 "Error" 16383 "Not Available";
VAL_ 2360658392 Lowest_Cell_State_of_Charge 1021 "Saturated" 1022 "Error" 1023 "Not Available";
VAL_ 2360658392 Highest_Cell_State_of_Charge 1021 "Saturated" 1022 "Error" 1023 "Not Available";
VAL_ 2360658392 Charge_Capacity 1021 "Saturated" 1022 "Error" 1023 "Not Available";
VAL_ 2360658392 Discharge_Capacity 1021 "Saturated" 1022 "Error" 1023 "Not Available";
VAL_ 2360658392 Estimated_Charge_Time_Remaining 16381 "Saturated" 16382 "Error" 16383 "Not Available";
